VERSION ""

NS_ :

BS_:

BU_: FUSION BMS CCU EBM EOP_F EOP_R MCU_B_F MCU_B_R Shifter MCU_N_F MCU_N_R DataCenter

BO_ 496 FD3_VCU0: 64 FUSION
 SG_ SysPwrSta : 7|4@0+ (1,0) [0|15] "" Vector__XXX
 SG_ PowerUpFault : 11|4@0+ (1,0) [0|7] "" Vector__XXX
 SG_ PowerUpState : 15|4@0+ (1,0) [0|7] "" Vector__XXX
 SG_ PowerDownFault : 19|4@0+ (1,0) [0|7] "" Vector__XXX
 SG_ PowerDownState : 22|3@0+ (1,0) [0|7] "" Vector__XXX
 SG_ TCountSta : 26|2@0+ (1,0) [0|2] "" Vector__XXX
 SG_ PwrStaConstraint : 29|3@0+ (1,0) [0|4] "" Vector__XXX
 SG_ PwrStaSelect : 31|2@0+ (1,0) [0|3] "" Vector__XXX
 SG_ Rr_TqSource : 35|4@0+ (1,0) [0|9] "" Vector__XXX
 SG_ PwrDownReq : 37|2@0+ (1,0) [0|2] "" Vector__XXX
 SG_ PwrUpReq : 39|2@0+ (1,0) [0|2] "" Vector__XXX
 SG_ HVTHCMSysAvail : 41|2@0+ (1,0) [0|3] "" Vector__XXX
 SG_ LVBattVoltSta : 43|2@0+ (1,0) [0|3] "" DataCenter
 SG_ Fr_TqSource : 47|4@0+ (1,0) [0|9] "" Vector__XXX
 SG_ VehHVPwrAvail4THCM : 55|8@0+ (50,0) [0|12650] "W" Vector__XXX
 SG_ HVRlyOpFail : 56|1@0+ (1,0) [0|1] "" Vector__XXX
 SG_ SysAllowReadySta : 57|1@0+ (1,0) [0|1] "" Vector__XXX
 SG_ VCURRDoorSta : 58|1@0+ (1,0) [0|1] "" Vector__XXX
 SG_ VCURLDoorSta : 59|1@0+ (1,0) [0|1] "" Vector__XXX
 SG_ VCUFRDoorSta : 60|1@0+ (1,0) [0|1] "" Vector__XXX
 SG_ VCUFLDoorSta : 61|1@0+ (1,0) [0|1] "" Vector__XXX
 SG_ VCUBrkSWSta : 63|2@0+ (1,0) [0|2] "" Vector__XXX
 SG_ PwrStaONTOIVIPopT : 67|12@0+ (1,0) [0|4095] "SECOND" Vector__XXX
 SG_ PwrStaTOSta : 69|1@0+ (1,0) [0|1] "" Vector__XXX
 SG_ PwrStaONTOIVIPopReq : 70|1@0+ (1,0) [0|1] "" Vector__XXX
 SG_ MCUActDisFail : 71|1@0+ (1,0) [0|1] "" Vector__XXX
 SG_ TimerAllowSleep : 80|1@0+ (1,0) [0|1] "" Vector__XXX
 SG_ LVSilentChrgReq : 81|1@0+ (1,0) [0|1] "" Vector__XXX
 SG_ LVSilentChrgLv : 83|2@0+ (1,0) [0|3] "" Vector__XXX
 SG_ LVSilentChrgSta : 85|2@0+ (1,0) [0|3] "" Vector__XXX
 SG_ SilentChkAllowSleep : 86|1@0+ (1,0) [0|1] "" Vector__XXX
 SG_ SchedChgTOSta : 87|1@0+ (1,0) [0|1] "" Vector__XXX
 SG_ LVChrgHoldTAct : 91|12@0+ (1,0) [0|4095] "SECOND" Vector__XXX
 SG_ EVCCAplusPwrUpReq : 94|1@0+ (1,0) [0|1] "" Vector__XXX
 SG_ PMMAllowECUSleep : 95|1@0+ (1,0) [0|1] "" Vector__XXX
 SG_ LVBattChrgtimeAct : 107|12@0+ (1,0) [0|4095] "SECOND" Vector__XXX
 SG_ FDADC12VDetAvg : 127|8@0+ (0.1,0) [0|25.5] "V" DataCenter
 SG_ WisrBootReason : 231|32@0+ (1,0) [0|4.294967295E9] "" Vector__XXX
 SG_ PmicBootReason : 223|8@0+ (1,0) [0|255] "" Vector__XXX
 SG_ FDC_VMC_ActStESCYaw_Sta : 263|16@0+ (0.01,-300) [-300|300] "Deg/s" Vector__XXX
 SG_ FDC_VMC_LongAcc_Sta : 279|16@0+ (0.001,-20) [-20|20] "G's" Vector__XXX
 SG_ FDC_VCU_VehActSpd_Sta : 295|16@0+ (0.01,-300) [-300|300] "km/h" Vector__XXX
 SG_ FDC_VCU_ActMaxSlideRate_Sta : 311|16@0+ (0.01,-150) [-150|150] "%" Vector__XXX
 SG_ FDC_VCU_SlideRegenLimTq_Sta : 327|16@0+ (0.5,-5300) [-5300|5300] "Nm" Vector__XXX
 SG_ FDC_VCU_DTCCarousel_Sta : 343|8@0+ (1,0) [0|255] "" Vector__XXX
 SG_ FDC_VCU_VehMalfunLevel_Sta : 3|4@0+ (1,0) [0|15] "" Vector__XXX
 SG_ FDC_VCU_RWDRDCActive_Sta : 93|2@0+ (1,0) [0|3] "" Vector__XXX
 SG_ FDC_VCU_AllowMovThd_OTA_Sta : 111|2@0+ (1,0) [0|3] "" Vector__XXX
 SG_ FDC_VCU_RegenTqLimitEn_Sta : 23|1@0+ (1,0) [0|1] "" Vector__XXX
 SG_ FDC_VCU_ForceP_Cmd : 24|1@0+ (1,0) [0|1] "" Vector__XXX
 SG_ FDC_VCU_PwrReq_OTA_Sta : 109|2@0+ (1,0) [0|3] "" Vector__XXX
 SG_ FDC_VCU_OTAPwrReqOFFChk_Sta : 351|2@0+ (1,0) [0|3] "" Vector__XXX
 SG_ FDC_VCU_OTAPwrReqStdChk_Sta : 349|2@0+ (1,0) [0|3] "" Vector__XXX
 SG_ FDADC12VDet : 215|8@0+ (0.1,0) [0|25.5] "V" Vector__XXX
 SG_ FDC_VCU_EAPS2Raw_Sta : 367|8@0+ (0.4,0) [0|102] "%" Vector__XXX
 SG_ FDC_VCU_EAPS1Raw_Sta : 359|8@0+ (0.4,0) [0|102] "%" Vector__XXX
 SG_ FDC_VCU_EAPS2Min_Sta : 383|8@0+ (0.4,0) [0|102] "%" Vector__XXX
 SG_ FDC_VCU_EAPS1Min_Sta : 375|8@0+ (0.4,0) [0|102] "%" Vector__XXX
 SG_ FDC_VCU_BrakeSigMatrix_Sta : 391|6@0+ (1,0) [0|63] "" Vector__XXX
 SG_ FDC_VCU_CANBrkSW2Sta_Sta : 347|2@0+ (1,0) [0|3] "" Vector__XXX
 SG_ FDC_VCU_BrkPedalPosSta_Sta : 345|2@0+ (1,0) [0|3] "" Vector__XXX
 SG_ FDC_VCU_LowIdleAccPedal_Sta : 68|1@0+ (1,0) [0|1] "" Vector__XXX
 SG_ FDC_SYS_PmicBootPath : 487|32@0+ (1,0) [0|4.294967295E9] "" Vector__XXX
 SG_ FDC_VCU_LVStaDropQukCnt_Sta : 471|8@0+ (1,0) [0|255] "" DataCenter
 SG_ FDC_VCU_LVChrgFreqCnt_Sta : 479|8@0+ (1,0) [0|255] "" DataCenter
 SG_ FDC_VCU_FrRateLimitInc_Sta : 135|16@0+ (2,0) [0|131070] "Nm" Vector__XXX
 SG_ FDC_VCU_RrRateLimitInc_Sta : 167|16@0+ (2,0) [0|131070] "Nm" Vector__XXX
 SG_ FDC_VCU_FrRateLimitDec_Sta : 151|16@0+ (2,-131070) [-131070|0] "Nm" Vector__XXX
 SG_ FDC_VCU_RrRateLimitDec_Sta : 183|16@0+ (2,-131070) [-131070|0] "Nm" Vector__XXX
 SG_ FDC_VCU_FrFirstOrderInpTs : 199|8@0+ (0.01,0) [0|2.55] "" Vector__XXX
 SG_ FDC_VCU_RrFirstOrderInpTs : 207|8@0+ (0.01,0) [0|2.55] "" Vector__XXX
 SG_ FDC_VCU_BOSEnable_Sta : 385|1@0+ (1,0) [0|1] "" Vector__XXX

BO_ 534 FD3_BCM1: 16 FUSION
 SG_ BCM_Buzzer_Req : 64|1@0+ (1,0) [0|1] "" Vector__XXX
 SG_ TailgateRemote : 66|2@0+ (1,0) [0|3] "" Vector__XXX
 SG_ RoomLampL : 67|1@0+ (1,0) [0|1] "" Vector__XXX
 SG_ RoomLampH : 68|1@0+ (1,0) [0|1] "" Vector__XXX
 SG_ DimmerEN : 69|1@0+ (1,0) [0|1] "" Shifter
 SG_ BCM_DoorLock_Sta : 70|1@0+ (1,0) [0|1] "" Vector__XXX
 SG_ HornCtrl : 71|1@0+ (1,0) [0|1] "" Vector__XXX
 SG_ Dimmer : 78|7@0+ (1,0) [0|100] "%" Shifter
 SG_ LockSetting : 79|1@0+ (1,0) [0|1] "" Vector__XXX
 SG_ LTurnLP : 80|1@0+ (1,0) [0|1] "" Vector__XXX
 SG_ RTurnLP : 81|1@0+ (1,0) [0|1] "" Vector__XXX
 SG_ AntitheftSta : 83|2@0+ (1,0) [0|3] "" Vector__XXX
 SG_ AntiTheftSeatFold : 84|1@0+ (1,0) [0|1] "" Vector__XXX
 SG_ CrashDetd : 85|1@0+ (1,0) [0|1] "" Vector__XXX
 SG_ L_APM_WdwEnable : 87|1@0+ (1,0) [0|1] "" Vector__XXX
 SG_ RDRL : 88|1@0+ (1,0) [0|1] "" Vector__XXX
 SG_ ReverseLamp : 89|1@0+ (1,0) [0|1] "" Vector__XXX
 SG_ BrakeLamp : 90|1@0+ (1,0) [0|1] "" Vector__XXX
 SG_ LBSD : 91|1@0+ (1,0) [0|1] "" Vector__XXX
 SG_ RBSD : 92|1@0+ (1,0) [0|1] "" Vector__XXX
 SG_ Fr_FogLamp : 93|1@0+ (1,0) [0|1] "" Vector__XXX
 SG_ Rr_FogLamp : 94|1@0+ (1,0) [0|1] "" Vector__XXX
 SG_ HazardSW : 95|1@0+ (1,0) [0|1] "" Vector__XXX
 SG_ Rr_Wiper : 96|1@0+ (1,0) [0|1] "" Vector__XXX
 SG_ WiperFixMode : 97|1@0+ (1,0) [0|1] "" Vector__XXX
 SG_ WasherCtrl : 99|2@0+ (1,0) [0|3] "" Vector__XXX
 SG_ L_Beam : 100|1@0+ (1,0) [0|1] "" Vector__XXX
 SG_ H_Beam : 101|1@0+ (1,0) [0|1] "" Vector__XXX
 SG_ PosLamp : 102|1@0+ (1,0) [0|1] "" Vector__XXX
 SG_ LDRL : 103|1@0+ (1,0) [0|1] "" Vector__XXX
 SG_ MirrorDefog : 104|1@0+ (1,0) [0|1] "" Vector__XXX
 SG_ Rr_Defog : 105|1@0+ (1,0) [0|1] "" Vector__XXX
 SG_ TrunkRel : 106|1@0+ (1,0) [0|1] "" Vector__XXX
 SG_ TailgateHDSW : 107|1@0+ (1,0) [0|1] "" Vector__XXX
 SG_ MirrorCtrl : 109|2@0+ (1,0) [0|3] "" Vector__XXX
 SG_ Fr_Wiper_H : 110|1@0+ (1,0) [0|1] "" Vector__XXX
 SG_ Fr_Wiper_L : 111|1@0+ (1,0) [0|1] "" Vector__XXX
 SG_ CTDCtrl : 113|2@0+ (1,0) [0|3] "" BMS
 SG_ Fr_ChargingDoorCtrl : 115|2@0+ (1,0) [0|3] "" Vector__XXX
 SG_ Rr_ChargingDoorCtrl : 117|2@0+ (1,0) [0|3] "" Vector__XXX
 SG_ CTDLockSW : 118|1@0+ (1,0) [0|1] "" Vector__XXX
 SG_ CTDUnlockSW : 119|1@0+ (1,0) [0|1] "" Vector__XXX
 SG_ DrDoorSW : 120|1@0+ (1,0) [0|1] "" EBM
 SG_ PsDoorSW : 121|1@0+ (1,0) [0|1] "" Vector__XXX
 SG_ RLDoorSW : 122|1@0+ (1,0) [0|1] "" Vector__XXX
 SG_ RRDoorSW : 123|1@0+ (1,0) [0|1] "" Vector__XXX
 SG_ AllDoorSW : 124|1@0+ (1,0) [0|1] "" Vector__XXX
 SG_ DoorLockIND : 125|1@0+ (1,0) [0|1] "" Vector__XXX
 SG_ HoodSW : 126|1@0+ (1,0) [0|1] "" Vector__XXX
 SG_ Tailgate_SW : 127|1@0+ (1,0) [0|1] "" Vector__XXX

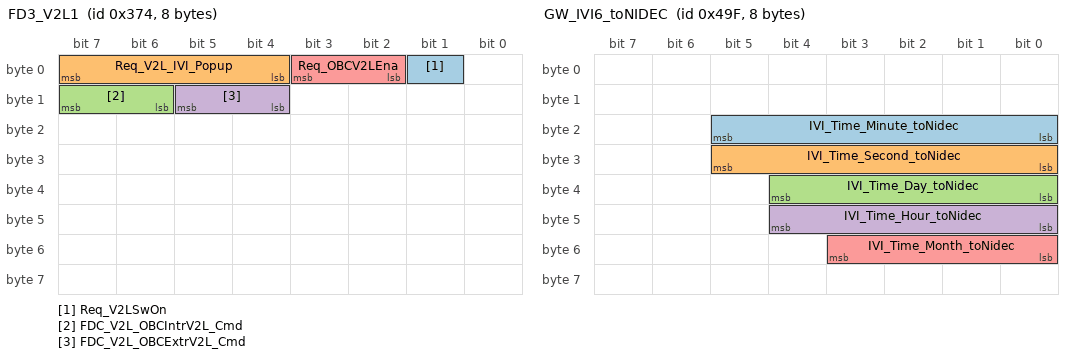
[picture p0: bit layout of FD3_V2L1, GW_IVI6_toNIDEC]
BO_ 884 FD3_V2L1: 8 FUSION
 SG_ Req_V2LSwOn : 1|1@0+ (1,0) [0|1] "" Vector__XXX
 SG_ Req_V2L_IVI_Popup : 7|4@0+ (1,0) [0|7] "" Vector__XXX
 SG_ FDC_V2L_OBCIntrV2L_Cmd : 15|2@0+ (1,0) [0|3] "" CCU
 SG_ FDC_V2L_OBCExtrV2L_Cmd : 13|2@0+ (1,0) [0|3] "" CCU
 SG_ Req_OBCV2LEna : 3|2@0+ (1,0) [0|2] "" CCU

BO_ 1080 FD3_OTA1: 12 FUSION
 SG_ OTA_Progress_Rate : 7|8@0+ (1,0) [0|102] "%" Vector__XXX
 SG_ OTA_DL_Available : 8|1@0+ (1,0) [0|1] "" Vector__XXX
 SG_ OTA_Mode : 9|1@0+ (1,0) [0|1] "" BMS,Shifter
 SG_ OTA_Network_Type : 11|2@0+ (1,0) [0|3] "" Vector__XXX
 SG_ OTA_MDA_Status : 52|5@0+ (1,0) [0|14] "" Vector__XXX
 SG_ OTA_Updating_ECU_8bit : 23|8@0+ (1,0) [0|255] "" Vector__XXX
 SG_ OTA_DL_Speed : 27|20@0+ (1,0) [0|1048575] "Kb/s" Vector__XXX
 SG_ OTA_InVehicle_FW : 29|2@0+ (1,0) [0|2] "" Vector__XXX
 SG_ OTA_TBOXResetReq : 30|1@0+ (1,0) [0|1] "" Vector__XXX
 SG_ OTA_Lock_Req : 31|1@0+ (1,0) [0|1] "" Vector__XXX
 SG_ OTA_Remained_Time : 58|11@0+ (10,0) [0|1081] "SECOND" Vector__XXX
 SG_ OTA_Update_Available : 62|1@0+ (1,0) [0|1] "" Vector__XXX
 SG_ OTA_Permit_Agreed : 63|1@0+ (1,0) [0|1] "" Vector__XXX
 SG_ OTA_Debug_Code : 79|8@0+ (1,0) [0|65] "" Vector__XXX
 SG_ OTA_Emergency_Sta : 61|2@0+ (1,0) [0|3] "" Vector__XXX

BO_ 1183 GW_IVI6_toNIDEC: 8 FUSION
 SG_ IVI_Time_Minute_toNidec : 21|6@0+ (1,0) [0|63] "MINUTE" EOP_F,EOP_R,MCU_N_F,MCU_N_R
 SG_ IVI_Time_Second_toNidec : 29|6@0+ (1,0) [0|63] "SECOND" EOP_F,EOP_R,MCU_N_F,MCU_N_R
 SG_ IVI_Time_Day_toNidec : 36|5@0+ (1,0) [0|31] "DAY" EOP_F,EOP_R,MCU_N_F,MCU_N_R
 SG_ IVI_Time_Hour_toNidec : 44|5@0+ (1,0) [0|31] "HOUR" EOP_F,EOP_R,MCU_N_F,MCU_N_R
 SG_ IVI_Time_Month_toNidec : 51|4@0+ (1,0) [0|12] "MONTH" EOP_F,EOP_R,MCU_N_F,MCU_N_R

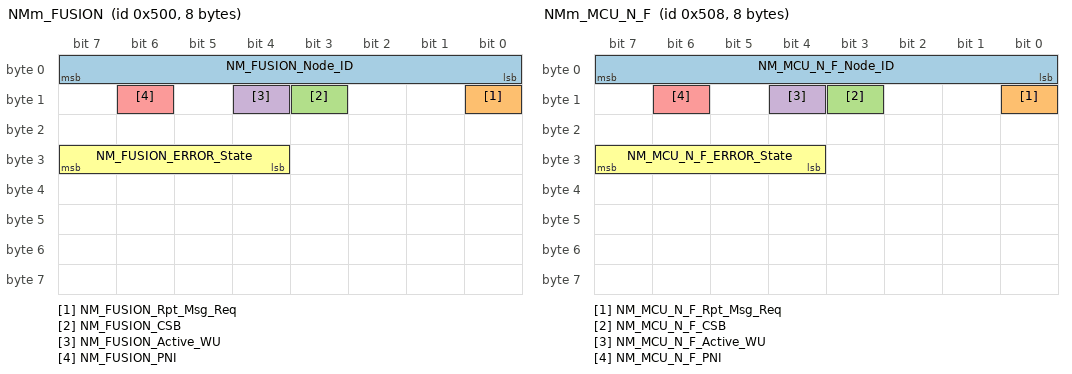
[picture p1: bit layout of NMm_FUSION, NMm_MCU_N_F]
BO_ 1280 NMm_FUSION: 8 FUSION
 SG_ NM_FUSION_Node_ID : 7|8@0+ (1,0) [0|127] "" BMS,CCU,EBM,EOP_F,EOP_R,MCU_N_F,MCU_N_R,Shifter,MCU_B_F,MCU_B_R
 SG_ NM_FUSION_Rpt_Msg_Req : 8|1@0+ (1,0) [0|1] "" BMS,CCU,EBM,EOP_F,EOP_R,MCU_N_F,MCU_N_R,Shifter,MCU_B_F,MCU_B_R
 SG_ NM_FUSION_CSB : 11|1@0+ (1,0) [0|1] "" BMS,CCU,EBM,EOP_F,EOP_R,MCU_N_F,MCU_N_R,Shifter,MCU_B_F,MCU_B_R
 SG_ NM_FUSION_Active_WU : 12|1@0+ (1,0) [0|1] "" BMS,CCU,EBM,EOP_F,EOP_R,MCU_N_F,MCU_N_R,Shifter,MCU_B_F,MCU_B_R
 SG_ NM_FUSION_PNI : 14|1@0+ (1,0) [0|1] "" BMS,CCU,EBM,EOP_F,EOP_R,MCU_N_F,MCU_N_R,Shifter,MCU_B_F,MCU_B_R
 SG_ NM_FUSION_ERROR_State : 31|4@0+ (1,0) [0|8] "" BMS,CCU,EBM,EOP_F,EOP_R,MCU_N_F,MCU_N_R,Shifter,MCU_B_F,MCU_B_R

BO_ 1667 DiagPhysReqToMCU_N_R: 8 FUSION
 SG_ DiagPhysReqToMCU_N_R : 7|64@0+ (1,0) [0|0] "" MCU_N_R

BO_ 1672 DiagPhysReqToMCU_N_F: 8 FUSION
 SG_ DiagPhysReqToMCU_N_F : 7|64@0+ (1,0) [0|0] "" MCU_N_F

BO_ 1683 DiagPhysReqToEOP_R: 64 FUSION
 SG_ DiagPhysReqToEOP_R : 7|64@0+ (1,0) [0|0] "" EOP_R

BO_ 1688 DiagPhysReqToEOP_F: 64 FUSION
 SG_ DiagPhysReqToEOP_F : 7|64@0+ (1,0) [0|0] "" EOP_F

BO_ 1699 DiagPhysReqToEBM: 64 FUSION
 SG_ DiagPhysReqToEBM : 7|64@0+ (1,0) [0|0] "" EBM

BO_ 1712 DiagPhysReqToBMS: 8 FUSION
 SG_ DiagPhysReqToBMS : 7|64@0+ (1,0) [0|0] "" BMS

BO_ 1715 DiagPhysReqToCCU: 8 FUSION
 SG_ DiagPhysReqToCCU : 7|64@0+ (1,0) [0|0] "" CCU

BO_ 1720 DiagPhysReqToShifter: 8 FUSION
 SG_ DiagPhysReqToShifter : 7|64@0+ (1,0) [0|0] "" Shifter

BO_ 2000 DiagFuncReqFT: 8 FUSION
 SG_ DiagFuncReqFT : 7|64@0+ (1,0) [0|0] "" BMS,CCU,EBM,EOP_F,EOP_R,MCU_N_F,MCU_N_R,Shifter,MCU_B_F,MCU_B_R

BO_ 401 MCU_B_F1: 32 MCU_B_F
 SG_ Fr_MCU1Chksum : 7|8@0+ (1,0) [0|255] "" FUSION
 SG_ Fr_MCU1RolCnt : 11|4@0+ (1,0) [0|14] "" FUSION
 SG_ Fr_MCUSysSta : 59|4@0+ (1,0) [0|15] "" FUSION
 SG_ MCUWarn_F : 62|3@0+ (1,0) [0|7] "" FUSION
 SG_ Fr_MCUReady : 63|1@0+ (1,0) [0|1] "" FUSION
 SG_ Fr_MCUBAT : 71|8@0+ (0.1,0) [0|25.4] "V" FUSION
 SG_ Fr_MCUIGN_sta : 72|1@0+ (1,0) [0|1] "" FUSION
 SG_ Fr_Reserved_bits : 79|7@0+ (1,0) [0|127] "" FUSION
 SG_ Fr_RegenAvailTq : 87|12@0+ (1,-1022) [-1022|0] "Nm" FUSION
 SG_ Fr_MotorAvailTq : 91|12@0+ (1,0) [0|1022] "Nm" FUSION
 SG_ Fr_TMiq : 110|15@0+ (0.1,-1500) [-1500|1500] "A" FUSION
 SG_ Fr_TMid : 126|15@0+ (0.1,-1500) [-1500|1500] "A" FUSION
 SG_ Fr_MCUErr : 143|8@0+ (1,0) [0|255] "" FUSION
 SG_ Fr_TMTemp : 144|9@0+ (1,-40) [-40|254] "Deg^C" FUSION
 SG_ Fr_MCUTemp : 167|9@0+ (1,-40) [-40|254] "Deg^C" FUSION
 SG_ Fr_MCUDCBusCurr : 174|15@0+ (0.1,-1500) [-1500|1500] "A" FUSION
 SG_ Fr_MCUDCBusVolt : 191|16@0+ (0.1,0) [0|4000] "V" FUSION
 SG_ Fr_MCUReady4Pre : 200|1@0+ (1,0) [0|1] "" FUSION
 SG_ Fr_ActvDmpDisabSta : 201|1@0+ (1,0) [0|1] "" FUSION
 SG_ Fr_EDUDrtSta : 202|1@0+ (1,0) [0|1] "" FUSION
 SG_ Fr_MCUDischrgSta : 203|1@0+ (1,0) [0|1] "" FUSION
 SG_ Fr_TMSpd : 215|16@0+ (1,-18000) [-18000|18000] "RPM" FUSION
 SG_ Fr_EDURealTMTq : 231|16@0+ (0.1,-1022) [-1022|5531.5] "Nm" FUSION
 SG_ Fr_EDUTqReqFbk : 243|12@0+ (1,-1022) [-1022|1022] "Nm" FUSION
 SG_ Fr_MCUEnaSta : 244|1@0+ (1,0) [0|1] "" FUSION
 SG_ Fr_EDUOpratingSta : 245|1@0+ (1,0) [0|1] "" FUSION
 SG_ Fr_EDURotateDirction : 247|2@0+ (1,0) [0|2] "" FUSION
 SG_ MCU_B_F_IGBTDdeTemp_Sta : 24|9@0+ (1,-40) [-40|254] "Deg^C" FUSION
 SG_ MCU_B_F_RealPwrKw_Sta : 47|16@0+ (0.1,-530) [-530|6023.4] "KW" FUSION

BO_ 404 MCU_B_F2: 16 MCU_B_F
 SG_ Fr_MCU2Chksum : 7|8@0+ (1,0) [0|255] "" FUSION
 SG_ Fr_MCU2RolCnt : 11|4@0+ (1,0) [0|14] "" FUSION
 SG_ Fr_LLCflowReq : 21|6@0+ (0.25,0) [0|15.5] "L/min" FUSION
 SG_ Fr_CoolanttempReq : 24|9@0+ (1,-40) [-40|214] "Deg^C" FUSION
 SG_ Fr_Failcodehistory1 : 41|2@0+ (1,0) [0|2] "" FUSION
 SG_ Fr_Failcodehistory2 : 43|2@0+ (1,0) [0|2] "" FUSION
 SG_ Fr_TMTempWarn : 45|2@0+ (1,0) [0|3] "" FUSION
 SG_ Fr_MCUTempWarn : 47|2@0+ (1,0) [0|3] "" FUSION
 SG_ Fr_Failcode2 : 55|8@0+ (1,0) [0|255] "" FUSION
 SG_ Fr_Failcode1 : 63|8@0+ (1,0) [0|255] "" FUSION
 SG_ Fr_LLCTemp : 80|9@0+ (1,-40) [-40|214] "Deg^C" FUSION
 SG_ Fr_MCU_HW_Ver : 103|16@0+ (1,0) [0|65535] "" FUSION
 SG_ Fr_MCU_SW_Ver : 119|16@0+ (1,0) [0|65535] "" FUSION
 SG_ MCU_B_F_LLCTempWarn_Sta : 23|2@0+ (1,0) [0|3] "" FUSION
 SG_ MCU_B_F_FailLv_Sta : 27|3@0+ (1,0) [0|7] "" FUSION
 SG_ MCU_B_F_KL302TqCnt_Sta : 71|8@0+ (1,0) [0|254] "" FUSION

BO_ 406 MCU_N_F1: 32 MCU_N_F
 SG_ Fr_MCU1Chksum_Nidec : 7|8@0+ (1,0) [0|255] "" FUSION
 SG_ MCUWarn_F_Nidec : 10|3@0+ (1,0) [0|7] "" FUSION
 SG_ Fr_MCUReady_Nidec : 11|1@0+ (1,0) [0|1] "" FUSION
 SG_ Fr_MCU1RolCnt_Nidec : 15|4@0+ (1,0) [0|15] "" FUSION
 SG_ Fr_MCUSysSta_Nidec : 59|4@0+ (1,0) [0|15] "" FUSION
 SG_ Fr_MCUBAT_Nidec : 71|8@0+ (0.1,0) [0|25.4] "V" FUSION
 SG_ Fr_MCUIGN_sta_Nidec : 72|1@0+ (1,0) [0|1] "" FUSION
 SG_ Fr_Reserved_bits_Nidec : 79|7@0+ (1,0) [0|127] "" FUSION
 SG_ Fr_RegenAvailTq_Nidec : 87|12@0+ (1,-1022) [-1022|0] "Nm" FUSION
 SG_ Fr_MotorAvailTq_Nidec : 91|12@0+ (1,0) [0|1022] "Nm" FUSION
 SG_ Fr_TMiq_Nidec : 110|15@0+ (0.1,-1500) [-1500|1500] "A" FUSION
 SG_ Fr_TMid_Nidec : 126|15@0+ (0.1,-1500) [-1500|1500] "A" FUSION
 SG_ Fr_MCUErr_Nidec : 143|8@0+ (1,0) [0|255] "" FUSION
 SG_ Fr_TMTemp_Nidec : 144|9@0+ (1,-40) [-40|254] "Deg^C" FUSION
 SG_ Fr_MCUTemp_Nidec : 167|9@0+ (1,-40) [-40|254] "Deg^C" FUSION
 SG_ Fr_MCUDCBusCurr_Nidec : 174|15@0+ (0.1,-1500) [-1500|1500] "A" FUSION
 SG_ Fr_MCUDCBusVolt_Nidec : 191|16@0+ (0.1,0) [0|4000] "V" FUSION
 SG_ Fr_MCUReady4Pre_Nidec : 200|1@0+ (1,0) [0|1] "" FUSION
 SG_ Fr_ActvDmpDisabSta_Nidec : 201|1@0+ (1,0) [0|1] "" FUSION
 SG_ Fr_EDUDrtSta_Nidec : 202|1@0+ (1,0) [0|1] "" FUSION
 SG_ Fr_MCUDischrgSta_Nidec : 203|1@0+ (1,0) [0|1] "" FUSION
 SG_ Fr_TMSpd_Nidec : 215|16@0+ (1,-17000) [-17000|17000] "RPM" FUSION
 SG_ Fr_EDURealTMTq_Nidec : 227|12@0+ (1,-1022) [-1022|1022] "Nm" FUSION
 SG_ Fr_EDUTqReqFbk_Nidec : 243|12@0+ (1,-1022) [-1022|1022] "Nm" FUSION
 SG_ Fr_MCUEnaSta_Nidec : 244|1@0+ (1,0) [0|1] "" FUSION
 SG_ Fr_EDUOpratingSta_Nidec : 245|1@0+ (1,0) [0|1] "" FUSION
 SG_ Fr_EDURotateDirction_Nidec : 247|2@0+ (1,0) [0|2] "" FUSION

BO_ 408 MCU_N_F2: 12 MCU_N_F
 SG_ Fr_MCU2Chksum_Nidec : 7|8@0+ (1,0) [0|255] "" FUSION
 SG_ Fr_MCU2RolCnt_Nidec : 15|4@0+ (1,0) [0|15] "" FUSION
 SG_ Fr_CoolanttempReq_Nidec : 24|9@0+ (1,-40) [-40|214] "Deg^C" FUSION
 SG_ Fr_Failcodehistory1_Nidec : 41|2@0+ (1,0) [0|2] "" FUSION
 SG_ Fr_Failcodehistory2_Nidec : 43|2@0+ (1,0) [0|2] "" FUSION
 SG_ Fr_TMTempWarn_Nidec : 45|2@0+ (1,0) [0|3] "" FUSION
 SG_ Fr_MCUTempWarn_Nidec : 47|2@0+ (1,0) [0|3] "" FUSION
 SG_ Fr_Failcode2_Nidec : 55|8@0+ (1,0) [0|255] "" FUSION
 SG_ Fr_Failcode1_Nidec : 63|8@0+ (1,0) [0|255] "" FUSION
 SG_ Fr_EOP_SpdSet_Nidec : 67|12@0+ (1,0) [0|4000] "RPM" FUSION
 SG_ Fr_LLCTemp_Nidec : 80|9@0+ (1,-40) [-40|214] "Deg^C" FUSION
 SG_ Fr_LLCflowReq_Nidec : 87|6@0+ (0.25,0) [0|15.5] "L/min" FUSION
 SG_ MCU_F_ResetCnt_Sta : 23|8@0+ (1,0) [0|255] "" FUSION

BO_ 921 MCU_N_F3: 8 MCU_N_F
 SG_ Fr_MCU_HW_Ver_Nidec : 39|16@0+ (1,0) [0|65535] "" FUSION
 SG_ Fr_MCU_SW_Ver_Nidec : 55|16@0+ (1,0) [0|65535] "" FUSION

BO_ 1288 NMm_MCU_N_F: 8 MCU_N_F
 SG_ NM_MCU_N_F_Node_ID : 7|8@0+ (1,0) [0|127] "" FUSION
 SG_ NM_MCU_N_F_Rpt_Msg_Req : 8|1@0+ (1,0) [0|1] "" FUSION
 SG_ NM_MCU_N_F_CSB : 11|1@0+ (1,0) [0|1] "" FUSION
 SG_ NM_MCU_N_F_Active_WU : 12|1@0+ (1,0) [0|1] "" FUSION
 SG_ NM_MCU_N_F_PNI : 14|1@0+ (1,0) [0|1] "" FUSION
 SG_ NM_MCU_N_F_ERROR_State : 31|4@0+ (1,0) [0|8] "" FUSION

BO_ 1544 DiagRespFromMCU_N_F: 8 MCU_N_F
 SG_ DiagRespFromMCU_N_F : 7|64@0+ (1,0) [0|0] "" FUSION

BO_ 400 MCU_B_R1: 32 MCU_B_R
 SG_ Rr_MCU1Chksum : 7|8@0+ (1,0) [0|255] "" FUSION
 SG_ Rr_MCU1RolCnt : 11|4@0+ (1,0) [0|14] "" FUSION
 SG_ Rr_MCUSysSta : 59|4@0+ (1,0) [0|15] "" FUSION
 SG_ MCUWarn_R : 62|3@0+ (1,0) [0|7] "" FUSION
 SG_ Rr_MCUReady : 63|1@0+ (1,0) [0|1] "" FUSION
 SG_ Rr_MCUBAT : 71|8@0+ (0.1,0) [0|25.4] "V" FUSION
 SG_ Rr_MCUIGN_sta : 72|1@0+ (1,0) [0|1] "" FUSION
 SG_ Rr_Reserved_bits : 79|7@0+ (1,0) [0|127] "" FUSION
 SG_ Rr_RegenAvailTq : 87|12@0+ (1,-1022) [-1022|0] "Nm" FUSION
 SG_ Rr_MotorAvailTq : 91|12@0+ (1,0) [0|1022] "Nm" FUSION
 SG_ Rr_TMiq : 110|15@0+ (0.1,-1500) [-1500|1500] "A" FUSION
 SG_ Rr_TMid : 126|15@0+ (0.1,-1500) [-1500|1500] "A" FUSION
 SG_ Rr_MCUErr : 143|8@0+ (1,0) [0|255] "" FUSION
 SG_ Rr_TMTemp : 144|9@0+ (1,-40) [-40|254] "Deg^C" FUSION
 SG_ Rr_MCUTemp : 167|9@0+ (1,-40) [-40|254] "Deg^C" FUSION
 SG_ Rr_MCUDCBusCurr : 174|15@0+ (0.1,-1500) [-1500|1500] "A" FUSION
 SG_ Rr_MCUDCBusVolt : 191|16@0+ (0.1,0) [0|4000] "V" FUSION
 SG_ Rr_MCUReady4Pre : 200|1@0+ (1,0) [0|1] "" FUSION
 SG_ Rr_ActvDmpDisabSta : 201|1@0+ (1,0) [0|1] "" FUSION
 SG_ Rr_EDUDrtSta : 202|1@0+ (1,0) [0|1] "" FUSION
 SG_ Rr_MCUDischrgSta : 203|1@0+ (1,0) [0|1] "" FUSION
 SG_ Rr_TMSpd : 215|16@0+ (1,-18000) [-18000|18000] "RPM" FUSION
 SG_ Rr_EDURealTMTq : 231|16@0+ (0.1,-1022) [-1022|5531.5] "Nm" FUSION
 SG_ Rr_EDUTqReqFbk : 243|12@0+ (1,-1022) [-1022|1022] "Nm" FUSION
 SG_ Rr_MCUEnaSta : 244|1@0+ (1,0) [0|1] "" FUSION
 SG_ Rr_EDUOpratingSta : 245|1@0+ (1,0) [0|1] "" FUSION
 SG_ Rr_EDURotateDirction : 247|2@0+ (1,0) [0|2] "" FUSION
 SG_ MCU_B_R_RealPwrKw_Sta : 47|16@0+ (0.1,-530) [-530|6023.4] "KW" FUSION
 SG_ MCU_B_R_IGBTDdeTemp_Sta : 24|9@0+ (1,-40) [-40|254] "Deg^C" FUSION

BO_ 402 MCU_N_R1: 32 MCU_N_R
 SG_ Rr_MCU1Chksum_Nidec : 7|8@0+ (1,0) [0|255] "" FUSION
 SG_ MCUWarn_R_Nidec : 10|3@0+ (1,0) [0|7] "" FUSION
 SG_ Rr_MCU1RolCnt_Nidec : 15|4@0+ (1,0) [0|15] "" FUSION
 SG_ Rr_MCUSysSta_Nidec : 59|4@0+ (1,0) [0|15] "" FUSION
 SG_ Rr_MCUBAT_Nidec : 71|8@0+ (0.1,0) [0|25.4] "V" FUSION
 SG_ Rr_MCUIGN_sta_Nidec : 72|1@0+ (1,0) [0|1] "" FUSION
 SG_ Rr_Reserved_bits_Nidec : 79|7@0+ (1,0) [0|127] "" FUSION
 SG_ Rr_RegenAvailTq_Nidec : 87|12@0+ (1,-1022) [-1022|0] "Nm" FUSION
 SG_ Rr_MotorAvailTq_Nidec : 91|12@0+ (1,0) [0|1022] "Nm" FUSION
 SG_ Rr_TMiq_Nidec : 110|15@0+ (0.1,-1500) [-1500|1500] "A" FUSION
 SG_ Rr_TMid_Nidec : 126|15@0+ (0.1,-1500) [-1500|1500] "A" FUSION
 SG_ Rr_MCUErr_Nidec : 143|8@0+ (1,0) [0|255] "" FUSION
 SG_ Rr_TMTemp_Nidec : 144|9@0+ (1,-40) [-40|254] "Deg^C" FUSION
 SG_ Rr_MCUTemp_Nidec : 167|9@0+ (1,-40) [-40|254] "Deg^C" FUSION
 SG_ Rr_MCUDCBusCurr_Nidec : 174|15@0+ (0.1,-1500) [-1500|1500] "A" FUSION
 SG_ Rr_MCUDCBusVolt_Nidec : 191|16@0+ (0.1,0) [0|4000] "V" FUSION
 SG_ Rr_MCUReady4Pre_Nidec : 200|1@0+ (1,0) [0|1] "" FUSION
 SG_ Rr_ActvDmpDisabSta_Nidec : 201|1@0+ (1,0) [0|1] "" FUSION
 SG_ Rr_EDUDrtSta_Nidec : 202|1@0+ (1,0) [0|1] "" FUSION
 SG_ Rr_MCUDischrgSta_Nidec : 203|1@0+ (1,0) [0|1] "" FUSION
 SG_ Rr_MCUReady_Nidec : 207|1@0+ (1,0) [0|1] "" FUSION
 SG_ Rr_TMSpd_Nidec : 215|16@0+ (1,-17000) [-17000|17000] "RPM" FUSION
 SG_ Rr_EDURealTMTq_Nidec : 227|12@0+ (1,-1022) [-1022|1022] "Nm" FUSION
 SG_ Rr_EDUTqReqFbk_Nidec : 243|12@0+ (1,-1022) [-1022|1022] "Nm" FUSION
 SG_ Rr_MCUEnaSta_Nidec : 244|1@0+ (1,0) [0|1] "" FUSION
 SG_ Rr_EDUOpratingSta_Nidec : 245|1@0+ (1,0) [0|1] "" FUSION
 SG_ Rr_EDURotateDirction_Nidec : 247|2@0+ (1,0) [0|2] "" FUSION

BO_ 403 MCU_B_R2: 16 MCU_B_R
 SG_ Rr_MCU2Chksum : 7|8@0+ (1,0) [0|255] "" FUSION
 SG_ Rr_MCU2RolCnt : 11|4@0+ (1,0) [0|14] "" FUSION
 SG_ Rr_LLCflowReq : 21|6@0+ (0.25,0) [0|15.5] "L/min" FUSION
 SG_ Rr_CoolanttempReq : 24|9@0+ (1,-40) [-40|214] "" FUSION
 SG_ Rr_Failcodehistory1 : 41|2@0+ (1,0) [0|2] "" FUSION
 SG_ Rr_Failcodehistory2 : 43|2@0+ (1,0) [0|2] "" FUSION
 SG_ Rr_TMTempWarn : 45|2@0+ (1,0) [0|3] "" FUSION
 SG_ Rr_MCUTempWarn : 47|2@0+ (1,0) [0|3] "" FUSION
 SG_ Rr_Failcode2 : 55|8@0+ (1,0) [0|255] "" FUSION
 SG_ Rr_Failcode1 : 63|8@0+ (1,0) [0|255] "" FUSION
 SG_ Rr_LLCTemp : 80|9@0+ (1,-40) [-40|214] "Deg^C" FUSION
 SG_ Rr_MCU3_HW_Ver : 103|16@0+ (1,0) [0|65535] "" FUSION
 SG_ Rr_MCU3_SW_Ver : 119|16@0+ (1,0) [0|65535] "" FUSION
 SG_ MCU_B_R_LLCTempWarn_Sta : 23|2@0+ (1,0) [0|3] "" FUSION
 SG_ MCU_B_R_FailLv_Sta : 27|3@0+ (1,0) [0|7] "" FUSION
 SG_ MCU_B_R_KL302TqCnt_Sta : 71|8@0+ (1,0) [0|254] "" FUSION

BO_ 412 MCU_N_R2: 12 MCU_N_R
 SG_ Rr_MCU2Chksum_Nidec : 7|8@0+ (1,0) [0|255] "" FUSION
 SG_ Rr_MCU2RolCnt_Nidec : 15|4@0+ (1,0) [0|15] "" FUSION
 SG_ Rr_CoolanttempReq_Nidec : 24|9@0+ (1,-40) [-40|214] "" FUSION
 SG_ Rr_Failcodehistory1_Nidec : 41|2@0+ (1,0) [0|2] "" FUSION
 SG_ Rr_Failcodehistory2_Nidec : 43|2@0+ (1,0) [0|2] "" FUSION
 SG_ Rr_TMTempWarn_Nidec : 45|2@0+ (1,0) [0|3] "" FUSION
 SG_ Rr_MCUTempWarn_Nidec : 47|2@0+ (1,0) [0|3] "" FUSION
 SG_ Rr_Failcode2_Nidec : 55|8@0+ (1,0) [0|255] "" FUSION
 SG_ Rr_Failcode1_Nidec : 63|8@0+ (1,0) [0|255] "" FUSION
 SG_ Rr_EOP_SpdSet_Nidec : 67|12@0+ (1,0) [0|4000] "RPM" FUSION
 SG_ Rr_LLCTemp_Nidec : 80|9@0+ (1,-40) [-40|214] "Deg^C" FUSION
 SG_ Rr_LLCflowReq_Nidec : 87|6@0+ (0.25,0) [0|15.5] "L/min" FUSION
 SG_ MCU_R_ResetCnt_Sta : 23|8@0+ (1,0) [0|255] "" FUSION

BO_ 925 MCU_N_R3: 8 MCU_N_R
 SG_ Rr_MCU3_HW_Ver_Nidec : 39|16@0+ (1,0) [0|65535] "" FUSION
 SG_ Rr_MCU3_SW_Ver_Nidec : 55|16@0+ (1,0) [0|65535] "" FUSION

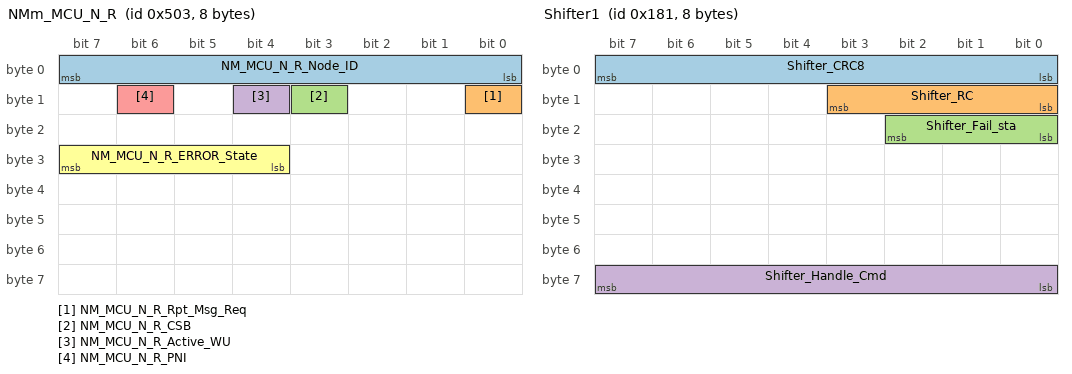
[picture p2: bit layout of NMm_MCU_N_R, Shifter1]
BO_ 1283 NMm_MCU_N_R: 8 MCU_N_R
 SG_ NM_MCU_N_R_Node_ID : 7|8@0+ (1,0) [0|127] "" FUSION
 SG_ NM_MCU_N_R_Rpt_Msg_Req : 8|1@0+ (1,0) [0|1] "" FUSION
 SG_ NM_MCU_N_R_CSB : 11|1@0+ (1,0) [0|1] "" FUSION
 SG_ NM_MCU_N_R_Active_WU : 12|1@0+ (1,0) [0|1] "" FUSION
 SG_ NM_MCU_N_R_PNI : 14|1@0+ (1,0) [0|1] "" FUSION
 SG_ NM_MCU_N_R_ERROR_State : 31|4@0+ (1,0) [0|8] "" FUSION

BO_ 1539 DiagRespFromMCU_N_R: 8 MCU_N_R
 SG_ DiagRespFromMCU_N_R : 7|64@0+ (1,0) [0|0] "" FUSION

BO_ 385 Shifter1: 8 Shifter
 SG_ Shifter_CRC8 : 7|8@0+ (1,0) [0|255] "" FUSION
 SG_ Shifter_RC : 11|4@0+ (1,0) [0|14] "" FUSION
 SG_ Shifter_Fail_sta : 18|3@0+ (1,0) [0|7] "" FUSION
 SG_ Shifter_Handle_Cmd : 63|8@0+ (1,0) [0|255] "" FUSION

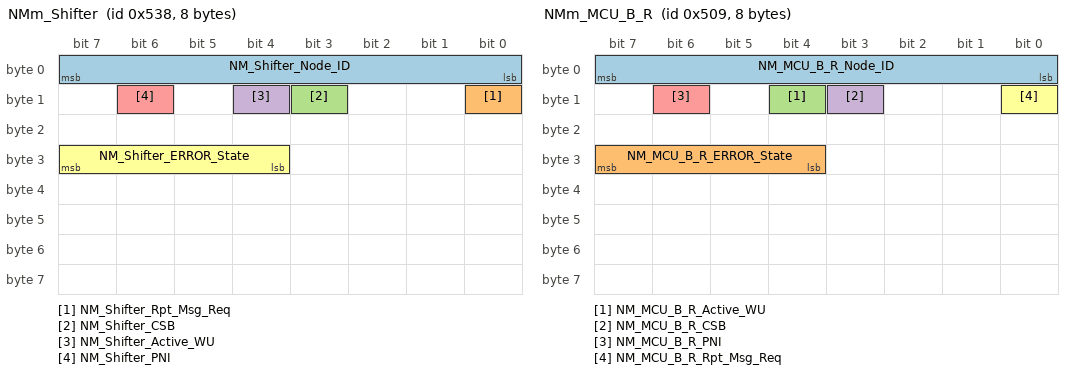
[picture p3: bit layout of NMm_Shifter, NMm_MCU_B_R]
BO_ 1336 NMm_Shifter: 8 Shifter
 SG_ NM_Shifter_Node_ID : 7|8@0+ (1,0) [0|127] "" FUSION
 SG_ NM_Shifter_Rpt_Msg_Req : 8|1@0+ (1,0) [0|1] "" FUSION
 SG_ NM_Shifter_CSB : 11|1@0+ (1,0) [0|1] "" FUSION
 SG_ NM_Shifter_Active_WU : 12|1@0+ (1,0) [0|1] "" FUSION
 SG_ NM_Shifter_PNI : 14|1@0+ (1,0) [0|1] "" FUSION
 SG_ NM_Shifter_ERROR_State : 31|4@0+ (1,0) [0|8] "" FUSION

BO_ 1592 DiagRespFromShifter: 8 Shifter
 SG_ DiagRespFromShifter : 7|64@0+ (1,0) [0|0] "" FUSION

BO_ 1545 DiagRespFromMCU_B_R: 64 MCU_B_R
 SG_ DiagRespFromMCU_B_R : 7|64@0+ (1,0) [0|0] "" FUSION

BO_ 1673 DiagPhysReqToMCU_B_R: 64 FUSION
 SG_ DiagPhysReqToMCU_B_R : 7|64@0+ (1,0) [0|0] "" MCU_B_R

BO_ 1674 DiagPhysReqToMCU_B_F: 64 FUSION
 SG_ DiagPhysReqToMCU_B_F : 7|64@0+ (1,0) [0|0] "" MCU_B_F

BO_ 1546 DiagRespFromMCU_B_F: 64 MCU_B_F
 SG_ DiagRespFromMCU_B_F : 7|64@0+ (1,0) [0|0] "" FUSION

BO_ 1289 NMm_MCU_B_R: 8 MCU_B_R
 SG_ NM_MCU_B_R_Node_ID : 7|8@0+ (1,0) [0|127] "" FUSION
 SG_ NM_MCU_B_R_ERROR_State : 31|4@0+ (1,0) [0|8] "" FUSION
 SG_ NM_MCU_B_R_Active_WU : 12|1@0+ (1,0) [0|1] "" FUSION
 SG_ NM_MCU_B_R_CSB : 11|1@0+ (1,0) [0|1] "" FUSION
 SG_ NM_MCU_B_R_PNI : 14|1@0+ (1,0) [0|1] "" FUSION
 SG_ NM_MCU_B_R_Rpt_Msg_Req : 8|1@0+ (1,0) [0|1] "" FUSION

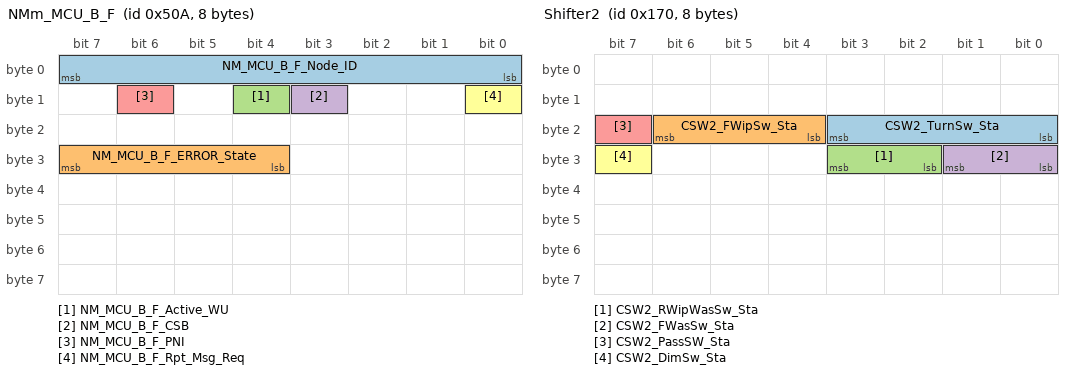
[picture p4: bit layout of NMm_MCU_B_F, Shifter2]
BO_ 1290 NMm_MCU_B_F: 8 MCU_B_F
 SG_ NM_MCU_B_F_Node_ID : 7|8@0+ (1,0) [0|127] "" FUSION
 SG_ NM_MCU_B_F_ERROR_State : 31|4@0+ (1,0) [0|8] "" FUSION
 SG_ NM_MCU_B_F_Active_WU : 12|1@0+ (1,0) [0|1] "" FUSION
 SG_ NM_MCU_B_F_CSB : 11|1@0+ (1,0) [0|1] "" FUSION
 SG_ NM_MCU_B_F_PNI : 14|1@0+ (1,0) [0|1] "" FUSION
 SG_ NM_MCU_B_F_Rpt_Msg_Req : 8|1@0+ (1,0) [0|1] "" FUSION

BO_ 368 Shifter2: 8 Shifter
 SG_ CSW2_TurnSw_Sta : 19|4@0+ (1,0) [0|5] "" FUSION
 SG_ CSW2_FWipSw_Sta : 22|3@0+ (1,0) [0|7] "" FUSION
 SG_ CSW2_RWipWasSw_Sta : 27|2@0+ (1,0) [0|3] "" FUSION
 SG_ CSW2_FWasSw_Sta : 25|2@0+ (1,0) [0|3] "" FUSION
 SG_ CSW2_PassSW_Sta : 23|1@0+ (1,0) [0|1] "" FUSION
 SG_ CSW2_DimSw_Sta : 31|1@0+ (1,0) [0|1] "" FUSION

BO_ 2015 DiagFuncReqOBD: 8 FUSION
 SG_ DiagFuncReqOBD : 7|64@0+ (1,0) [0|0] "" BMS,CCU,MCU_B_F,MCU_B_R

BO_ 564 BMS13: 64 BMS
 SG_ CellVoltage160 : 7|16@0+ (1,0) [0|65534] "mV" FUSION
 SG_ CellVoltage159 : 23|16@0+ (1,0) [0|65534] "mV" FUSION
 SG_ CellVoltage158 : 39|16@0+ (1,0) [0|65534] "mV" FUSION
 SG_ CellVoltage157 : 55|16@0+ (1,0) [0|65534] "mV" FUSION
 SG_ CellVoltage156 : 71|16@0+ (1,0) [0|65534] "mV" FUSION
 SG_ CellVoltage155 : 87|16@0+ (1,0) [0|65534] "mV" FUSION
 SG_ CellVoltage154 : 103|16@0+ (1,0) [0|65534] "mV" FUSION
 SG_ CellVoltage153 : 119|16@0+ (1,0) [0|65534] "mV" FUSION
 SG_ CellVoltage152 : 135|16@0+ (1,0) [0|65534] "mV" FUSION
 SG_ CellVoltage151 : 151|16@0+ (1,0) [0|65534] "mV" FUSION
 SG_ CellVoltage150 : 167|16@0+ (1,0) [0|65534] "mV" FUSION
 SG_ CellVoltage149 : 183|16@0+ (1,0) [0|65534] "mV" FUSION
 SG_ CellVoltage148 : 199|16@0+ (1,0) [0|65534] "mV" FUSION
 SG_ CellVoltage147 : 215|16@0+ (1,0) [0|65534] "mV" FUSION
 SG_ CellVoltage146 : 231|16@0+ (1,0) [0|65534] "mV" FUSION
 SG_ CellVoltage145 : 247|16@0+ (1,0) [0|65534] "mV" FUSION
 SG_ CellVoltage144 : 263|16@0+ (1,0) [0|65534] "mV" FUSION
 SG_ CellVoltage143 : 279|16@0+ (1,0) [0|65534] "mV" FUSION
 SG_ CellVoltage142 : 295|16@0+ (1,0) [0|65534] "mV" FUSION
 SG_ CellVoltage141 : 311|16@0+ (1,0) [0|65534] "mV" FUSION
 SG_ CellVoltage140 : 327|16@0+ (1,0) [0|65534] "mV" FUSION
 SG_ CellVoltage139 : 343|16@0+ (1,0) [0|65534] "mV" FUSION
 SG_ CellVoltage138 : 359|16@0+ (1,0) [0|65534] "mV" FUSION
 SG_ CellVoltage137 : 375|16@0+ (1,0) [0|65534] "mV" FUSION
 SG_ CellVoltage136 : 391|16@0+ (1,0) [0|65534] "mV" FUSION
 SG_ CellVoltage135 : 407|16@0+ (1,0) [0|65534] "mV" FUSION
 SG_ CellVoltage134 : 423|16@0+ (1,0) [0|65534] "mV" FUSION
 SG_ CellVoltage133 : 439|16@0+ (1,0) [0|65534] "mV" FUSION
 SG_ CellVoltage132 : 455|16@0+ (1,0) [0|65534] "mV" FUSION
 SG_ CellVoltage131 : 471|16@0+ (1,0) [0|65534] "mV" FUSION
 SG_ CellVoltage130 : 487|16@0+ (1,0) [0|65534] "mV" FUSION
 SG_ CellVoltage129 : 503|16@0+ (1,0) [0|65534] "mV" FUSION

BO_ 565 BMS14: 64 BMS
 SG_ CellVoltage192 : 7|16@0+ (1,0) [0|65534] "mV" FUSION
 SG_ CellVoltage191 : 23|16@0+ (1,0) [0|65534] "mV" FUSION
 SG_ CellVoltage190 : 39|16@0+ (1,0) [0|65534] "mV" FUSION
 SG_ CellVoltage189 : 55|16@0+ (1,0) [0|65534] "mV" FUSION
 SG_ CellVoltage188 : 71|16@0+ (1,0) [0|65534] "mV" FUSION
 SG_ CellVoltage187 : 87|16@0+ (1,0) [0|65534] "mV" FUSION
 SG_ CellVoltage186 : 103|16@0+ (1,0) [0|65534] "mV" FUSION
 SG_ CellVoltage185 : 119|16@0+ (1,0) [0|65534] "mV" FUSION
 SG_ CellVoltage184 : 135|16@0+ (1,0) [0|65534] "mV" FUSION
 SG_ CellVoltage183 : 151|16@0+ (1,0) [0|65534] "mV" FUSION
 SG_ CellVoltage182 : 167|16@0+ (1,0) [0|65534] "mV" FUSION
 SG_ CellVoltage181 : 183|16@0+ (1,0) [0|65534] "mV" FUSION
 SG_ CellVoltage180 : 199|16@0+ (1,0) [0|65534] "mV" FUSION
 SG_ CellVoltage179 : 215|16@0+ (1,0) [0|65534] "mV" FUSION
 SG_ CellVoltage178 : 231|16@0+ (1,0) [0|65534] "mV" FUSION
 SG_ CellVoltage177 : 247|16@0+ (1,0) [0|65534] "mV" FUSION
 SG_ CellVoltage176 : 263|16@0+ (1,0) [0|65534] "mV" FUSION
 SG_ CellVoltage175 : 279|16@0+ (1,0) [0|65534] "mV" FUSION
 SG_ CellVoltage174 : 295|16@0+ (1,0) [0|65534] "mV" FUSION
 SG_ CellVoltage173 : 311|16@0+ (1,0) [0|65534] "mV" FUSION
 SG_ CellVoltage172 : 327|16@0+ (1,0) [0|65534] "mV" FUSION
 SG_ CellVoltage171 : 343|16@0+ (1,0) [0|65534] "mV" FUSION
 SG_ CellVoltage170 : 359|16@0+ (1,0) [0|65534] "mV" FUSION
 SG_ CellVoltage169 : 375|16@0+ (1,0) [0|65534] "mV" FUSION
 SG_ CellVoltage168 : 391|16@0+ (1,0) [0|65534] "mV" FUSION
 SG_ CellVoltage167 : 407|16@0+ (1,0) [0|65534] "mV" FUSION
 SG_ CellVoltage166 : 423|16@0+ (1,0) [0|65534] "mV" FUSION
 SG_ CellVoltage165 : 439|16@0+ (1,0) [0|65534] "mV" FUSION
 SG_ CellVoltage164 : 455|16@0+ (1,0) [0|65534] "mV" FUSION
 SG_ CellVoltage163 : 471|16@0+ (1,0) [0|65534] "mV" FUSION
 SG_ CellVoltage162 : 487|16@0+ (1,0) [0|65534] "mV" FUSION
 SG_ CellVoltage161 : 503|16@0+ (1,0) [0|65534] "mV" FUSION

BO_ 566 BMS15: 64 BMS
 SG_ CellVoltage216 : 135|16@0+ (1,0) [0|65534] "mV" FUSION
 SG_ CellVoltage215 : 151|16@0+ (1,0) [0|65534] "mV" FUSION
 SG_ CellVoltage214 : 167|16@0+ (1,0) [0|65534] "mV" FUSION
 SG_ CellVoltage213 : 183|16@0+ (1,0) [0|65534] "mV" FUSION
 SG_ CellVoltage212 : 199|16@0+ (1,0) [0|65534] "mV" FUSION
 SG_ CellVoltage211 : 215|16@0+ (1,0) [0|65534] "mV" FUSION
 SG_ CellVoltage210 : 231|16@0+ (1,0) [0|65534] "mV" FUSION
 SG_ CellVoltage209 : 247|16@0+ (1,0) [0|65534] "mV" FUSION
 SG_ CellVoltage208 : 263|16@0+ (1,0) [0|65534] "mV" FUSION
 SG_ CellVoltage207 : 279|16@0+ (1,0) [0|65534] "mV" FUSION
 SG_ CellVoltage206 : 295|16@0+ (1,0) [0|65534] "mV" FUSION
 SG_ CellVoltage205 : 311|16@0+ (1,0) [0|65534] "mV" FUSION
 SG_ CellVoltage204 : 327|16@0+ (1,0) [0|65534] "mV" FUSION
 SG_ CellVoltage203 : 343|16@0+ (1,0) [0|65534] "mV" FUSION
 SG_ CellVoltage202 : 359|16@0+ (1,0) [0|65534] "mV" FUSION
 SG_ CellVoltage201 : 375|16@0+ (1,0) [0|65534] "mV" FUSION
 SG_ CellVoltage200 : 391|16@0+ (1,0) [0|65534] "mV" FUSION
 SG_ CellVoltage199 : 407|16@0+ (1,0) [0|65534] "mV" FUSION
 SG_ CellVoltage198 : 423|16@0+ (1,0) [0|65534] "mV" FUSION
 SG_ CellVoltage197 : 439|16@0+ (1,0) [0|65534] "mV" FUSION
 SG_ CellVoltage196 : 455|16@0+ (1,0) [0|65534] "mV" FUSION
 SG_ CellVoltage195 : 471|16@0+ (1,0) [0|65534] "mV" FUSION
 SG_ CellVoltage194 : 487|16@0+ (1,0) [0|65534] "mV" FUSION
 SG_ CellVoltage193 : 503|16@0+ (1,0) [0|65534] "mV" FUSION

BO_ 409 MCU_FVT_R1: 20 MCU_B_R
 SG_ MCU_FVT_R_TMSpd_Sta : 55|16@0+ (1,-22000) [-22000|43535] "RPM" FUSION
 SG_ MCU_FVT_R_EDUTqReq_Fbk : 71|16@0+ (0.1,-1022) [-1022|5531.5] "" FUSION
 SG_ MCU_FVT_R_Failcode3_Sta : 95|8@0+ (1,0) [0|255] "" FUSION
 SG_ MCU_FVT_R_MCUErr_Sta : 87|8@0+ (1,0) [0|255] "" FUSION
 SG_ MCU_FVT_R_OilTemp_Sta : 32|9@0+ (1,-40) [-40|471] "Deg^C" FUSION
 SG_ MCU_FVT_R_MCUBAT_Sta : 16|9@0+ (0.2,0) [0|102.2] "V" FUSION
 SG_ MCU_FVT_R_MCUSys_Sta : 23|4@0+ (1,0) [0|15] "" FUSION
 SG_ MCU_FVT_R_HeatingOP_Sta : 33|1@0+ (1,0) [0|1] "" FUSION
 SG_ MCU_FVT_R_BoostOP_Sta : 17|1@0+ (1,0) [0|1] "" FUSION

BO_ 410 MCU_FVT_F1: 20 MCU_B_F
 SG_ MCU_FVT_F_TMSpd_Sta : 55|16@0+ (1,-22000) [-22000|43535] "RPM" FUSION
 SG_ MCU_FVT_F_EDUTqReq_Fbk : 71|16@0+ (0.1,-1022) [-1022|5531.5] "" FUSION
 SG_ MCU_FVT_F_Failcode3_Sta : 95|8@0+ (1,0) [0|255] "" FUSION
 SG_ MCU_FVT_F_MCUErr_Sta : 87|8@0+ (1,0) [0|255] "" FUSION
 SG_ MCU_FVT_F_OilTemp_Sta : 32|9@0+ (1,-40) [-40|471] "Deg^C" FUSION
 SG_ MCU_FVT_F_MCUBAT_Sta : 16|9@0+ (0.2,0) [0|102.2] "V" FUSION
 SG_ MCU_FVT_F_MCUSys_Sta : 23|4@0+ (1,0) [0|15] "" FUSION
 SG_ MCU_FVT_F_HeatingOP_Sta : 33|1@0+ (1,0) [0|1] "" FUSION
 SG_ MCU_FVT_F_BoostOP_Sta : 17|1@0+ (1,0) [0|1] "" FUSION

BO_ 1731 DiagPhysReqToEOP_FVT_R: 8 FUSION
 SG_ DiagPhysReqToEOP_FVT_R : 7|64@0+ (1,0) [0|0] "" MCU_B_R

BO_ 1603 DiagRespFromEOP_FVT_R: 8 MCU_B_R
 SG_ DiagRespFromEOP_FVT_R : 7|64@0+ (1,0) [0|0] "" FUSION

BO_ 1732 DiagPhysReqToEOP_FVT_F: 8 FUSION
 SG_ DiagPhysReqToEOP_FVT_F : 7|64@0+ (1,0) [0|0] "" MCU_B_F

BO_ 1604 DiagRespFromEOP_FVT_F: 8 MCU_B_F
 SG_ DiagRespFromEOP_FVT_F : 7|64@0+ (1,0) [0|0] "" FUSION

CM_ BO_ 1183 "for D31L NIDEC MCU";
CM_ BO_ 368 "Shifter and CSW gen2 CAN ECU";
CM_ SG_ 496 SysPwrSta "System power mode";
CM_ SG_ 496 PowerUpFault "Power up fault";
CM_ SG_ 496 PowerUpState "Power up mode";
CM_ SG_ 496 PowerDownFault "Power down fault";
CM_ SG_ 496 PowerDownState "Power down state";
CM_ SG_ 496 TCountSta "Timmer counting state";
CM_ SG_ 496 PwrStaConstraint "Power state constraint";
CM_ SG_ 496 PwrStaSelect "Power state select";
CM_ SG_ 496 Rr_TqSource "Rear EDU Torque Source";
CM_ SG_ 496 PwrUpReq "Power up request";
CM_ SG_ 496 HVTHCMSysAvail "HV THCM syetem avaliable state";
CM_ SG_ 496 LVBattVoltSta "LV battery voltage state";
CM_ SG_ 496 Fr_TqSource "Front EDU Torque Source";
CM_ SG_ 496 VehHVPwrAvail4THCM "Vehicle HV power avalible for THCM";
CM_ SG_ 496 HVRlyOpFail "HV relay opend fail";
CM_ SG_ 496 SysAllowReadySta "System allow  to ready state";
CM_ SG_ 496 VCURRDoorSta "VCU RR door state";
CM_ SG_ 496 VCURLDoorSta "VCU RL door state";
CM_ SG_ 496 VCUFRDoorSta "VCU FR door state";
CM_ SG_ 496 VCUFLDoorSta "VCU FL door state";
CM_ SG_ 496 VCUBrkSWSta "VCU brake SW state";
CM_ SG_ 496 PwrStaONTOIVIPopT "Count down time value for power state ON timeout IVI popup";
CM_ SG_ 496 PwrStaTOSta "Power state timeout state";
CM_ SG_ 496 PwrStaONTOIVIPopReq "Power state ON timeout IVI popup";
CM_ SG_ 496 MCUActDisFail "MCU active discharge fail";
CM_ SG_ 496 TimerAllowSleep "Timer allow sleep flag.";
CM_ SG_ 496 LVSilentChrgReq "LV Silent Chrge Request";
CM_ SG_ 496 LVSilentChrgLv "LV silent charging level";
CM_ SG_ 496 LVSilentChrgSta "LV Silent Chrge State";
CM_ SG_ 496 SilentChkAllowSleep "Silent charge check allow sleep flag.";
CM_ SG_ 496 SchedChgTOSta "Schedule charge timeout state";
CM_ SG_ 496 LVChrgHoldTAct "Calibration value for LV charge hold time";
CM_ SG_ 496 EVCCAplusPwrUpReq "EVCC A-plus signal power up request.";
CM_ SG_ 496 PMMAllowECUSleep "PMM allow ECU sleep flag.";
CM_ SG_ 496 LVBattChrgtimeAct "V Battery charge time.";
CM_ SG_ 496 FDADC12VDetAvg "FD ADC 12V detect voltage average value";
CM_ SG_ 496 WisrBootReason "FDC wisr boot reason";
CM_ SG_ 496 PmicBootReason "FDC PMIC boot reason";
CM_ SG_ 496 FDC_VMC_ActStESCYaw_Sta "Actual standard ESC yaw rate";
CM_ SG_ 496 FDC_VMC_LongAcc_Sta "longitudinal acceleration";
CM_ SG_ 496 FDC_VCU_VehActSpd_Sta "Actual max slide rate";
CM_ SG_ 496 FDC_VCU_ActMaxSlideRate_Sta "Actual max slide rate";
CM_ SG_ 496 FDC_VCU_SlideRegenLimTq_Sta "Slide regen limit tq";
CM_ SG_ 496 FDC_VCU_DTCCarousel_Sta "DTC carousel";
CM_ SG_ 496 FDC_VCU_VehMalfunLevel_Sta "Vehicle malfunction level";
CM_ SG_ 496 FDC_VCU_RWDRDCActive_Sta "RWD RDC active";
CM_ SG_ 496 FDC_VCU_AllowMovThd_OTA_Sta "OTA allow move threshold";
CM_ SG_ 496 FDC_VCU_RegenTqLimitEn_Sta "Regen torque limit enable";
CM_ SG_ 496 FDC_VCU_ForceP_Cmd "Force P gear command";
CM_ SG_ 496 FDC_VCU_PwrReq_OTA_Sta "Power request by OTA";
CM_ SG_ 496 FDC_VCU_OTAPwrReqOFFChk_Sta "VCU check state of OTA power request OFF";
CM_ SG_ 496 FDC_VCU_OTAPwrReqStdChk_Sta "VCU check state of OTA power request STANDBY";
CM_ SG_ 496 FDADC12VDet "FD ADC 12V detect voltage value";
CM_ SG_ 496 FDC_VCU_EAPS2Raw_Sta "APS2 raw reading";
CM_ SG_ 496 FDC_VCU_EAPS1Raw_Sta "APS1 raw reading";
CM_ SG_ 496 FDC_VCU_EAPS2Min_Sta "APS2 minimum point";
CM_ SG_ 496 FDC_VCU_EAPS1Min_Sta "APS1 minimum point";
CM_ SG_ 496 FDC_VCU_BrakeSigMatrix_Sta "Brake signal matrix";
CM_ SG_ 496 FDC_VCU_CANBrkSW2Sta_Sta "Brake switch state from CAN";
CM_ SG_ 496 FDC_VCU_BrkPedalPosSta_Sta "Brake pedal position state";
CM_ SG_ 496 FDC_VCU_LowIdleAccPedal_Sta "Accel pedal low idle state";
CM_ SG_ 496 FDC_SYS_PmicBootPath "Output a 4 bytes raw value for we can identify the FDC boot path.";
CM_ SG_ 496 FDC_VCU_LVStaDropQukCnt_Sta "Count number of LV state drop quickly  ";
CM_ SG_ 496 FDC_VCU_LVChrgFreqCnt_Sta "Count number of LV charge frequently level";
CM_ SG_ 496 FDC_VCU_FrRateLimitInc_Sta "Fr Increase Rate Limit Tq";
CM_ SG_ 496 FDC_VCU_RrRateLimitInc_Sta "Rr Increase Rate Limit Tq";
CM_ SG_ 496 FDC_VCU_FrRateLimitDec_Sta "Fr Decrease Rate Limit Tq";
CM_ SG_ 496 FDC_VCU_RrRateLimitDec_Sta "Rr Decrease Rate Limit Tq";
CM_ SG_ 496 FDC_VCU_FrFirstOrderInpTs "Fr 1st Order Input Ts";
CM_ SG_ 496 FDC_VCU_RrFirstOrderInpTs "Rr 1st Order Input Ts";
CM_ SG_ 496 FDC_VCU_BOSEnable_Sta "BOS enable flag";
CM_ SG_ 534 BCM_Buzzer_Req "BCM Buzzer Request";
CM_ SG_ 534 TailgateRemote "Remote Control PTG";
CM_ SG_ 534 RoomLampL "Room Lamp Low";
CM_ SG_ 534 RoomLampH "Room Lamp High";
CM_ SG_ 534 DimmerEN "Dimmer Enable";
CM_ SG_ 534 BCM_DoorLock_Sta "BCM Unlock Single Door Setting";
CM_ SG_ 534 HornCtrl "Horn Control";
CM_ SG_ 534 Dimmer "Dimmer";
CM_ SG_ 534 LockSetting "BCM Unlock Single Door Setting";
CM_ SG_ 534 LTurnLP "Left Turn Lamp";
CM_ SG_ 534 RTurnLP "Right Turn Lamp";
CM_ SG_ 534 AntitheftSta "Anti-theft Status";
CM_ SG_ 534 AntiTheftSeatFold "Anti-theft Seat Fold";
CM_ SG_ 534 CrashDetd "Crash Detected";
CM_ SG_ 534 L_APM_WdwEnable "Enable windows movement";
CM_ SG_ 534 RDRL "Right DRL";
CM_ SG_ 534 ReverseLamp "ReverseLamp";
CM_ SG_ 534 BrakeLamp "BrakeLamp";
CM_ SG_ 534 LBSD "Left BSD";
CM_ SG_ 534 RBSD "Right BSD";
CM_ SG_ 534 Fr_FogLamp "Front Fog Lamp";
CM_ SG_ 534 Rr_FogLamp "Rear Fog Lamp";
CM_ SG_ 534 HazardSW "Hazard SW";
CM_ SG_ 534 Rr_Wiper "Rear Wiper";
CM_ SG_ 534 WiperFixMode "Wiper Fix Mode";
CM_ SG_ 534 WasherCtrl "WasherControl";
CM_ SG_ 534 L_Beam "Low Beam";
CM_ SG_ 534 H_Beam "High Beam";
CM_ SG_ 534 PosLamp "PositionLamp";
CM_ SG_ 534 LDRL "Left DRL";
CM_ SG_ 534 MirrorDefog "Mirror Defog";
CM_ SG_ 534 Rr_Defog "Rear Defog";
CM_ SG_ 534 TrunkRel "Trunk Release";
CM_ SG_ 534 TailgateHDSW "Tailgate Handle SW";
CM_ SG_ 534 MirrorCtrl "Mirror Control";
CM_ SG_ 534 Fr_Wiper_H "Front Wiper High";
CM_ SG_ 534 Fr_Wiper_L "Front Wiper LOW";
CM_ SG_ 534 CTDCtrl "Door Lock Control";
CM_ SG_ 534 Fr_ChargingDoorCtrl "Front Charging Door Control";
CM_ SG_ 534 Rr_ChargingDoorCtrl "Rear Charging Door Control";
CM_ SG_ 534 CTDLockSW "Central Door Lock SW";
CM_ SG_ 534 CTDUnlockSW "Central Door Unlock SW";
CM_ SG_ 534 DrDoorSW "Driver Side Door Switch";
CM_ SG_ 534 PsDoorSW "Passenger Side Door Switch";
CM_ SG_ 534 RLDoorSW "Rear Left Door Switch";
CM_ SG_ 534 RRDoorSW "Rear Right Door Switch";
CM_ SG_ 534 AllDoorSW "All Door Switch";
CM_ SG_ 534 DoorLockIND "Door Lock Indicator";
CM_ SG_ 534 HoodSW "Hood Switch";
CM_ SG_ 534 Tailgate_SW "Tailgate Switch";
CM_ SG_ 884 Req_V2LSwOn "FD asks IVI popup wording for SW on.";
CM_ SG_ 884 Req_V2L_IVI_Popup "FD asks IVI popup wording for V2L fault.";
CM_ SG_ 884 FDC_V2L_OBCIntrV2L_Cmd "Request the internal discharge relay status of the OBC.";
CM_ SG_ 884 FDC_V2L_OBCExtrV2L_Cmd "Request the external discharge relay status of the OBC.";
CM_ SG_ 884 Req_OBCV2LEna "FD trigs OBC V2L enabled.";
CM_ SG_ 1080 OTA_Progress_Rate "MDA download or update progress rate";
CM_ SG_ 1080 OTA_DL_Available "Fusion MDA available for download";
CM_ SG_ 1080 OTA_Mode "Vehicel OTA mode Status";
CM_ SG_ 1080 OTA_Network_Type "Vehicle Network Type";
CM_ SG_ 1080 OTA_MDA_Status "Fusion Master OTA agent status";
CM_ SG_ 1080 OTA_Updating_ECU_8bit "Fusion MDA is updating ECU";
CM_ SG_ 1080 OTA_DL_Speed "Firmware Package download speed";
CM_ SG_ 1080 OTA_InVehicle_FW "In Vehicle Firmware Version Status";
CM_ SG_ 1080 OTA_TBOXResetReq "TBOX Reset Request";
CM_ SG_ 1080 OTA_Lock_Req "OTA Lock request to DKC";
CM_ SG_ 1080 OTA_Remained_Time "Download/Upgrade Estimated Time";
CM_ SG_ 1080 OTA_Update_Available "Fusion MDA available for update";
CM_ SG_ 1080 OTA_Permit_Agreed "Download/Upgrade coundition check result";
CM_ SG_ 1080 OTA_Debug_Code "OTA Error Code for Debug";
CM_ SG_ 1080 OTA_Emergency_Sta "Fusion emergency state";
CM_ SG_ 1183 IVI_Time_Minute_toNidec "IVI_GPS Satellite Time_Minute
FDC for D31L NIDEC MCU";
CM_ SG_ 1183 IVI_Time_Second_toNidec "IVI_GPS Satellite Time_Second
FDC for D31L NIDEC MCU";
CM_ SG_ 1183 IVI_Time_Day_toNidec "IVI_GPS Satellite Time_Day
FDC for D31L NIDEC MCU";
CM_ SG_ 1183 IVI_Time_Hour_toNidec "IVI_GPS Satellite Time_Hour
FDC for D31L NIDEC MCU";
CM_ SG_ 1183 IVI_Time_Month_toNidec "IVI_GPS Satellite Time_Month
FDC for D31L NIDEC MCU";
CM_ SG_ 1280 NM_FUSION_Node_ID "Source Node Identifier";
CM_ SG_ 1280 NM_FUSION_Rpt_Msg_Req "Repeat Message Request";
CM_ SG_ 1280 NM_FUSION_CSB "NM Coordinator Sleep Bit";
CM_ SG_ 1280 NM_FUSION_Active_WU "Active Wakeup Bit";
CM_ SG_ 1280 NM_FUSION_PNI "Partial Network Information Bit (PNI)";
CM_ SG_ 1280 NM_FUSION_ERROR_State "Defined Error states of the CAN Controller";
CM_ SG_ 1667 DiagPhysReqToMCU_N_R "Diagnostic Physical Request to MCU_R";
CM_ SG_ 1672 DiagPhysReqToMCU_N_F "Diagnostic Physical Request to MCU_F";
CM_ SG_ 1683 DiagPhysReqToEOP_R "Diagnostic Physical Request to EOP_R";
CM_ SG_ 1688 DiagPhysReqToEOP_F "Diagnostic Physical Request to EOP_F";
CM_ SG_ 1699 DiagPhysReqToEBM "Diagnostic Physical Request to EBM";
CM_ SG_ 1712 DiagPhysReqToBMS "Diagnostic Physical Request to BMS";
CM_ SG_ 1715 DiagPhysReqToCCU "Diagnostic Physical Request to CCU";
CM_ SG_ 1720 DiagPhysReqToShifter "Diagnostic Physical Request to Shifter";
CM_ SG_ 2000 DiagFuncReqFT "Diagnostic Functional Request from Tester";
CM_ SG_ 401 Fr_MCU1Chksum "Checksum of MCU_F1(AUTOSAR E2E profile 1)

Polynomial 0x1D (x^8+x^4+x^3+x^2+1) Both start value and XOR value are 0x00.";
CM_ SG_ 401 Fr_MCU1RolCnt "MCU1_F1 4-bit rolling counter
It starts counting from 0, ends at 14 and returns to zero (0~14).";
CM_ SG_ 401 Fr_MCUSysSta "Front MCU System Status";
CM_ SG_ 401 MCUWarn_F "MCU warning signal_Front";
CM_ SG_ 401 Fr_MCUReady "Front MCU Ready";
CM_ SG_ 401 Fr_MCUBAT "Front Bat Voltage";
CM_ SG_ 401 Fr_MCUIGN_sta "IGN ON/OFF Status";
CM_ SG_ 401 Fr_Reserved_bits "Front Reserved bits";
CM_ SG_ 401 Fr_RegenAvailTq "Front RegenerationTorque Available";
CM_ SG_ 401 Fr_MotorAvailTq "Front Motor Torque Available";
CM_ SG_ 401 Fr_TMiq "Front TM iq Feedback";
CM_ SG_ 401 Fr_TMid "Front TM id Feedback";
CM_ SG_ 401 Fr_MCUErr "Front MCU Error Code";
CM_ SG_ 401 Fr_TMTemp "Front TM Temperature";
CM_ SG_ 401 Fr_MCUTemp "Front MCU Temperature";
CM_ SG_ 401 Fr_MCUDCBusCurr "Front MCU DC Current";
CM_ SG_ 401 Fr_MCUDCBusVolt "Front MCU DC-Bus Voltage";
CM_ SG_ 401 Fr_MCUReady4Pre "Front MCU Ready for Precharge";
CM_ SG_ 401 Fr_ActvDmpDisabSta "Front MCU Low speed active damping disable status";
CM_ SG_ 401 Fr_EDUDrtSta "Front EDU Torque Derating Status";
CM_ SG_ 401 Fr_MCUDischrgSta "Front MCU Discharge Status";
CM_ SG_ 401 Fr_TMSpd "Front TM speed";
CM_ SG_ 401 Fr_EDURealTMTq "Front EDU Real Torque from TM";
CM_ SG_ 401 Fr_EDUTqReqFbk "Front EDU Torque Request Feedback";
CM_ SG_ 401 Fr_MCUEnaSta "Front MCU Enable Status";
CM_ SG_ 401 Fr_EDUOpratingSta "Front EDU Torque/Speed Status";
CM_ SG_ 401 Fr_EDURotateDirction "Front EDU Direction Status";
CM_ SG_ 401 MCU_B_F_IGBTDdeTemp_Sta "Front IGBTDde of MCU Temp";
CM_ SG_ 401 MCU_B_F_RealPwrKw_Sta "Front Real Power_Kw";
CM_ SG_ 404 Fr_MCU2Chksum "Checksum of MCU_F2(AUTOSAR E2E profile 1)

Polynomial 0x1D (x^8+x^4+x^3+x^2+1) Both start value and XOR value are 0x00.";
CM_ SG_ 404 Fr_MCU2RolCnt "MCU_F2 4-bit rolling counter
It starts counting from 0, ends at 14 and returns to zero (0~14).";
CM_ SG_ 404 Fr_LLCflowReq "Front request LLC flow rate";
CM_ SG_ 404 Fr_CoolanttempReq "LLC coolant temp Request";
CM_ SG_ 404 Fr_Failcodehistory1 "Front Failcode history status";
CM_ SG_ 404 Fr_Failcodehistory2 "Front Failcode history status";
CM_ SG_ 404 Fr_TMTempWarn "Front TM Temperature Warning";
CM_ SG_ 404 Fr_MCUTempWarn "Front MCU Temperature Warning";
CM_ SG_ 404 Fr_Failcode2 "Front Detail fail code";
CM_ SG_ 404 Fr_Failcode1 "Front Detail fail code";
CM_ SG_ 404 Fr_LLCTemp "Front LLC temperature";
CM_ SG_ 404 Fr_MCU_HW_Ver "Front MCU Hardware version";
CM_ SG_ 404 Fr_MCU_SW_Ver "Front MCU Software version";
CM_ SG_ 404 MCU_B_F_LLCTempWarn_Sta "Front LLC temperature Warning";
CM_ SG_ 404 MCU_B_F_FailLv_Sta "Front EDU Failure LVL Status";
CM_ SG_ 404 MCU_B_F_KL302TqCnt_Sta "Front KL30 to Torque mode counter";
CM_ SG_ 406 Fr_MCU1Chksum_Nidec "Front MCU1 Frame checksum(SAEJ1850) 
x^8+x^4+x^3+x^2+1
It shall use 0xFF as the start value and XOR value.";
CM_ SG_ 406 MCUWarn_F_Nidec "Front MCU warning signal from Nidec";
CM_ SG_ 406 Fr_MCUReady_Nidec "Front MCU Ready from Nidec";
CM_ SG_ 406 Fr_MCU1RolCnt_Nidec "Front MCU1 4 bits Process counter";
CM_ SG_ 406 Fr_MCUSysSta_Nidec "Front MCU System Status from Nidec";
CM_ SG_ 406 Fr_MCUBAT_Nidec "Front Bat Voltage from Nidec";
CM_ SG_ 406 Fr_MCUIGN_sta_Nidec "IGN ON/OFF Status from Nidec";
CM_ SG_ 406 Fr_Reserved_bits_Nidec "Front Reserved bits from Nidec";
CM_ SG_ 406 Fr_RegenAvailTq_Nidec "Front RegenerationTorque Available from Nidec";
CM_ SG_ 406 Fr_MotorAvailTq_Nidec "Front Motor Torque Available from Nidec";
CM_ SG_ 406 Fr_TMiq_Nidec "Front TM iq Feedback from Nidec";
CM_ SG_ 406 Fr_TMid_Nidec "Front TM id Feedback from Nidec";
CM_ SG_ 406 Fr_MCUErr_Nidec "Front MCU Error Code from Nidec";
CM_ SG_ 406 Fr_TMTemp_Nidec "Front TM Temperature from Nidec";
CM_ SG_ 406 Fr_MCUTemp_Nidec "Front MCU Temperature from Nidec";
CM_ SG_ 406 Fr_MCUDCBusCurr_Nidec "Front MCU DC Current from Nidec";
CM_ SG_ 406 Fr_MCUDCBusVolt_Nidec "Front MCU DC-Bus Voltage from Nidec";
CM_ SG_ 406 Fr_MCUReady4Pre_Nidec "Front MCU Ready for Precharge from Nidec";
CM_ SG_ 406 Fr_ActvDmpDisabSta_Nidec "Front MCU Low speed active damping disable status from Nidec";
CM_ SG_ 406 Fr_EDUDrtSta_Nidec "Front EDU Torque Derating Status from Nidec";
CM_ SG_ 406 Fr_MCUDischrgSta_Nidec "Front MCU Discharge Status from Nidec";
CM_ SG_ 406 Fr_TMSpd_Nidec "Front TM speed from Nidec";
CM_ SG_ 406 Fr_EDURealTMTq_Nidec "Front EDU Real Torque from TM from Nidec";
CM_ SG_ 406 Fr_EDUTqReqFbk_Nidec "Front EDU Torque Request Feedback from Nidec";
CM_ SG_ 406 Fr_MCUEnaSta_Nidec "Front MCU Enable Status from Nidec";
CM_ SG_ 406 Fr_EDUOpratingSta_Nidec "Front EDU Torque/Speed Status from Nidec";
CM_ SG_ 406 Fr_EDURotateDirction_Nidec "Front EDU Direction Status from Nidec";
CM_ SG_ 408 Fr_MCU2Chksum_Nidec "Front MCU2 Frame checksum(SAEJ1850) 
x^8+x^4+x^3+x^2+1
It shall use 0xFF as the start value and XOR value.";
CM_ SG_ 408 Fr_MCU2RolCnt_Nidec "Front MCU2 4bits Process counter";
CM_ SG_ 408 Fr_CoolanttempReq_Nidec "LLC coolant temp Request from Nidec";
CM_ SG_ 408 Fr_Failcodehistory1_Nidec "Front Failcode history status from Nidec";
CM_ SG_ 408 Fr_Failcodehistory2_Nidec "Front Failcode history status from Nidec";
CM_ SG_ 408 Fr_TMTempWarn_Nidec "Front TM Temperature Warning from Nidec";
CM_ SG_ 408 Fr_MCUTempWarn_Nidec "Front MCU Temperature Warning from Nidec";
CM_ SG_ 408 Fr_Failcode2_Nidec "Front Detail fail code from Nidec";
CM_ SG_ 408 Fr_Failcode1_Nidec "Front Detail fail code from Nidec";
CM_ SG_ 408 Fr_EOP_SpdSet_Nidec "Front MCU request EOP Speed from Nidec";
CM_ SG_ 408 Fr_LLCTemp_Nidec "Front LLC temperature from Nidec";
CM_ SG_ 408 Fr_LLCflowReq_Nidec "Front request LLC flow rate from Nidec";
CM_ SG_ 408 MCU_F_ResetCnt_Sta "Front  MCU Reset counter";
CM_ SG_ 921 Fr_MCU_HW_Ver_Nidec "Front MCU Hardware version from Nidec";
CM_ SG_ 921 Fr_MCU_SW_Ver_Nidec "Front MCU Software version from Nidec";
CM_ SG_ 1288 NM_MCU_N_F_Node_ID "Source Node Identifier";
CM_ SG_ 1288 NM_MCU_N_F_Rpt_Msg_Req "Repeat Message Request";
CM_ SG_ 1288 NM_MCU_N_F_CSB "NM Coordinator Sleep Bit";
CM_ SG_ 1288 NM_MCU_N_F_Active_WU "Active Wakeup Bit";
CM_ SG_ 1288 NM_MCU_N_F_PNI "Partial Network Information Bit (PNI)";
CM_ SG_ 1288 NM_MCU_N_F_ERROR_State "Defined Error states of the CAN Controller";
CM_ SG_ 1544 DiagRespFromMCU_N_F "Diagnostic Response from MCU_F";
CM_ SG_ 400 Rr_MCU1Chksum "Checksum of MCU_R1(AUTOSAR E2E profile 1)

Polynomial 0x1D (x^8+x^4+x^3+x^2+1) Both start value and XOR value are 0x00.";
CM_ SG_ 400 Rr_MCU1RolCnt "MCU_R1 4-bit rolling counter
It starts counting from 0, ends at 14 and returns to zero (0~14).";
CM_ SG_ 400 Rr_MCUSysSta "Rear MCU System Status";
CM_ SG_ 400 MCUWarn_R "MCU warning signal_Rear";
CM_ SG_ 400 Rr_MCUReady "Rear MCU Ready";
CM_ SG_ 400 Rr_MCUBAT "Rear  Bat Voltage";
CM_ SG_ 400 Rr_MCUIGN_sta "IGN ON/OFF Status";
CM_ SG_ 400 Rr_Reserved_bits "Rear  Reserved bits";
CM_ SG_ 400 Rr_RegenAvailTq "Rear RegenerationTorque Available";
CM_ SG_ 400 Rr_MotorAvailTq "Rear Motor Torque Available";
CM_ SG_ 400 Rr_TMiq "Rear  TM iq Feedback";
CM_ SG_ 400 Rr_TMid "Rear  TM id Feedback";
CM_ SG_ 400 Rr_MCUErr "Rear  MCU Error Code";
CM_ SG_ 400 Rr_TMTemp "Rear TM Temperature";
CM_ SG_ 400 Rr_MCUTemp "Rear MCU Temperature";
CM_ SG_ 400 Rr_MCUDCBusCurr "Rear  MCU DC Current";
CM_ SG_ 400 Rr_MCUDCBusVolt "Rear MCU DC-Bus Voltage";
CM_ SG_ 400 Rr_MCUReady4Pre "Rear MCU Ready for Precharge";
CM_ SG_ 400 Rr_ActvDmpDisabSta "Rear MCU Low speed active damping disable status";
CM_ SG_ 400 Rr_EDUDrtSta "Rear EDU Torque Derating Status";
CM_ SG_ 400 Rr_MCUDischrgSta "Rear MCU Discharge Status";
CM_ SG_ 400 Rr_TMSpd "Rear TM speed";
CM_ SG_ 400 Rr_EDURealTMTq "Rear EDU Real Torque from TM";
CM_ SG_ 400 Rr_EDUTqReqFbk "Rear EDU Torque Request Feedback";
CM_ SG_ 400 Rr_MCUEnaSta "Rear MCU Enable Status";
CM_ SG_ 400 Rr_EDUOpratingSta "Rear EDU Torque/Speed Status";
CM_ SG_ 400 Rr_EDURotateDirction "Rear EDU Direction Status";
CM_ SG_ 400 MCU_B_R_RealPwrKw_Sta "Rear Real Power_Kw";
CM_ SG_ 400 MCU_B_R_IGBTDdeTemp_Sta "Rear IGBTDde of MCU Temp";
CM_ SG_ 402 Rr_MCU1Chksum_Nidec "Front MCU1 Frame checksum(SAEJ1850) 
x^8+x^4+x^3+x^2+1
It shall use 0xFF as the start value and XOR value.";
CM_ SG_ 402 MCUWarn_R_Nidec "Rear MCU warning signal from Nidec";
CM_ SG_ 402 Rr_MCU1RolCnt_Nidec "Front MCU1 4 bits Process counter";
CM_ SG_ 402 Rr_MCUSysSta_Nidec "Rear MCU System Status from Nidec";
CM_ SG_ 402 Rr_MCUBAT_Nidec "Rear  Bat Voltage from Nidec";
CM_ SG_ 402 Rr_MCUIGN_sta_Nidec "IGN ON/OFF Status from Nidec";
CM_ SG_ 402 Rr_Reserved_bits_Nidec "Rear  Reserved bits from Nidec";
CM_ SG_ 402 Rr_RegenAvailTq_Nidec "Rear RegenerationTorque Available from Nidec";
CM_ SG_ 402 Rr_MotorAvailTq_Nidec "Rear Motor Torque Available from Nidec";
CM_ SG_ 402 Rr_TMiq_Nidec "Rear  TM iq Feedback from Nidec";
CM_ SG_ 402 Rr_TMid_Nidec "Rear  TM id Feedback from Nidec";
CM_ SG_ 402 Rr_MCUErr_Nidec "Rear  MCU Error Code from Nidec";
CM_ SG_ 402 Rr_TMTemp_Nidec "Rear TM Temperature from Nidec";
CM_ SG_ 402 Rr_MCUTemp_Nidec "Rear MCU Temperature from Nidec";
CM_ SG_ 402 Rr_MCUDCBusCurr_Nidec "Rear  MCU DC Current from Nidec";
CM_ SG_ 402 Rr_MCUDCBusVolt_Nidec "Rear MCU DC-Bus Voltage from Nidec";
CM_ SG_ 402 Rr_MCUReady4Pre_Nidec "Rear MCU Ready for Precharge from Nidec";
CM_ SG_ 402 Rr_ActvDmpDisabSta_Nidec "Rear MCU Low speed active damping disable status from Nidec";
CM_ SG_ 402 Rr_EDUDrtSta_Nidec "Rear EDU Torque Derating Status from Nidec";
CM_ SG_ 402 Rr_MCUDischrgSta_Nidec "Rear MCU Discharge Status from Nidec";
CM_ SG_ 402 Rr_MCUReady_Nidec "Rear MCU Ready from Nidec";
CM_ SG_ 402 Rr_TMSpd_Nidec "Rear TM speed from Nidec";
CM_ SG_ 402 Rr_EDURealTMTq_Nidec "Rear EDU Real Torque from TM from Nidec";
CM_ SG_ 402 Rr_EDUTqReqFbk_Nidec "Rear EDU Torque Request Feedback from Nidec";
CM_ SG_ 402 Rr_MCUEnaSta_Nidec "Rear MCU Enable Status from Nidec";
CM_ SG_ 402 Rr_EDUOpratingSta_Nidec "Rear EDU Torque/Speed Status from Nidec";
CM_ SG_ 402 Rr_EDURotateDirction_Nidec "Rear EDU Direction Status from Nidec";
CM_ SG_ 403 Rr_MCU2Chksum "Checksum of MCU_R2(AUTOSAR E2E profile 1)

Polynomial 0x1D (x^8+x^4+x^3+x^2+1) Both start value and XOR value are 0x00.";
CM_ SG_ 403 Rr_MCU2RolCnt "MCU_R2 4-bit rolling counter
It starts counting from 0, ends at 14 and returns to zero (0~14).";
CM_ SG_ 403 Rr_LLCflowReq "Rear  request LLC flow rate";
CM_ SG_ 403 Rr_CoolanttempReq "LLC coolant temp Request";
CM_ SG_ 403 Rr_Failcodehistory1 "Rear  Failcode history status";
CM_ SG_ 403 Rr_Failcodehistory2 "Rear Failcode history status";
CM_ SG_ 403 Rr_TMTempWarn "Rear TM Temperature Warning";
CM_ SG_ 403 Rr_MCUTempWarn "Rear MCU Temperature Warning";
CM_ SG_ 403 Rr_Failcode2 "Rear  Detail fail code";
CM_ SG_ 403 Rr_Failcode1 "Rear  Detail fail code";
CM_ SG_ 403 Rr_LLCTemp "Rear  LLC temperature";
CM_ SG_ 403 Rr_MCU3_HW_Ver "Rear MCU Hardware version";
CM_ SG_ 403 Rr_MCU3_SW_Ver "Rear MCU Software version";
CM_ SG_ 403 MCU_B_R_LLCTempWarn_Sta "Rear LLC temperature Warning";
CM_ SG_ 403 MCU_B_R_FailLv_Sta "Rear EDU Failure LVL Status";
CM_ SG_ 403 MCU_B_R_KL302TqCnt_Sta "Rear KL30 to Torque mode counter";
CM_ SG_ 412 Rr_MCU2Chksum_Nidec "Rear  MCU2 Frame checksum(SAEJ1850) 
x^8+x^4+x^3+x^2+1
It shall use 0xFF as the start value and XOR value.";
CM_ SG_ 412 Rr_MCU2RolCnt_Nidec "Rear MCU2 4bits Process counter";
CM_ SG_ 412 Rr_CoolanttempReq_Nidec "LLC coolant temp Request from Nidec";
CM_ SG_ 412 Rr_Failcodehistory1_Nidec "Rear  Failcode history status from Nidec";
CM_ SG_ 412 Rr_Failcodehistory2_Nidec "Rear Failcode history status from Nidec";
CM_ SG_ 412 Rr_TMTempWarn_Nidec "Rear TM Temperature Warning from Nidec";
CM_ SG_ 412 Rr_MCUTempWarn_Nidec "Rear MCU Temperature Warning from Nidec";
CM_ SG_ 412 Rr_Failcode2_Nidec "Rear  Detail fail code from Nidec";
CM_ SG_ 412 Rr_Failcode1_Nidec "Rear  Detail fail code from Nidec";
CM_ SG_ 412 Rr_EOP_SpdSet_Nidec "Rear  MCU request EOP Speed from Nidec";
CM_ SG_ 412 Rr_LLCTemp_Nidec "Rear  LLC temperature from Nidec";
CM_ SG_ 412 Rr_LLCflowReq_Nidec "Rear  request LLC flow rate from Nidec";
CM_ SG_ 412 MCU_R_ResetCnt_Sta "Rear MCU Reset counter";
CM_ SG_ 925 Rr_MCU3_HW_Ver_Nidec "Rear MCU Hardware version from Nidec";
CM_ SG_ 925 Rr_MCU3_SW_Ver_Nidec "Rear MCU Software version from Nidec";
CM_ SG_ 1283 NM_MCU_N_R_Node_ID "Source Node Identifier";
CM_ SG_ 1283 NM_MCU_N_R_Rpt_Msg_Req "Repeat Message Request";
CM_ SG_ 1283 NM_MCU_N_R_CSB "NM Coordinator Sleep Bit";
CM_ SG_ 1283 NM_MCU_N_R_Active_WU "Active Wakeup Bit";
CM_ SG_ 1283 NM_MCU_N_R_PNI "Partial Network Information Bit (PNI)";
CM_ SG_ 1283 NM_MCU_N_R_ERROR_State "Defined Error states of the CAN Controller";
CM_ SG_ 1539 DiagRespFromMCU_N_R "Diagnostic Response from MCU_R";
CM_ SG_ 385 Shifter_CRC8 "Checksum of Shifter1(AUTOSAR E2E profile 1)

Polynomial 0x1D (x^8+x^4+x^3+x^2+1) Both start value and XOR value are 0x00.";
CM_ SG_ 385 Shifter_RC "Shifter 4-bit rolling counter
It starts counting from 0, ends at 14 and returns to zero (0~14).";
CM_ SG_ 385 Shifter_Fail_sta "Shifter fail status";
CM_ SG_ 385 Shifter_Handle_Cmd "Shifter Control Unit handle Command(PRND)";
CM_ SG_ 1336 NM_Shifter_Node_ID "Source Node Identifier";
CM_ SG_ 1336 NM_Shifter_Rpt_Msg_Req "Repeat Message Request";
CM_ SG_ 1336 NM_Shifter_CSB "NM Coordinator Sleep Bit";
CM_ SG_ 1336 NM_Shifter_Active_WU "Active Wakeup Bit";
CM_ SG_ 1336 NM_Shifter_PNI "Partial Network Information Bit (PNI)";
CM_ SG_ 1336 NM_Shifter_ERROR_State "Defined Error states of the CAN Controller";
CM_ SG_ 1592 DiagRespFromShifter "Diagnostic Response from Shifter";
CM_ SG_ 1545 DiagRespFromMCU_B_R "Diagnostic Response from MCU_R";
CM_ SG_ 1673 DiagPhysReqToMCU_B_R "Diagnostic Physical Request to MCU_R";
CM_ SG_ 1674 DiagPhysReqToMCU_B_F "Diagnostic Physical Request to MCU_F";
CM_ SG_ 1546 DiagRespFromMCU_B_F "Diagnostic Response from MCU_F";
CM_ SG_ 1289 NM_MCU_B_R_Node_ID "Source Node Identifier";
CM_ SG_ 1289 NM_MCU_B_R_ERROR_State "Defined Error states of the CAN Controller";
CM_ SG_ 1289 NM_MCU_B_R_Active_WU "Active Wakeup Bit";
CM_ SG_ 1289 NM_MCU_B_R_CSB "NM Coordinator Sleep Bit";
CM_ SG_ 1289 NM_MCU_B_R_PNI "Partial Network Information Bit (PNI)";
CM_ SG_ 1289 NM_MCU_B_R_Rpt_Msg_Req "Repeat Message Request";
CM_ SG_ 1290 NM_MCU_B_F_Node_ID "Source Node Identifier";
CM_ SG_ 1290 NM_MCU_B_F_ERROR_State "Defined Error states of the CAN Controller";
CM_ SG_ 1290 NM_MCU_B_F_Active_WU "Active Wakeup Bit";
CM_ SG_ 1290 NM_MCU_B_F_CSB "NM Coordinator Sleep Bit";
CM_ SG_ 1290 NM_MCU_B_F_PNI "Partial Network Information Bit (PNI)";
CM_ SG_ 1290 NM_MCU_B_F_Rpt_Msg_Req "Repeat Message Request";
CM_ SG_ 368 CSW2_TurnSw_Sta "Turning Switch Status (Shifter and CSW gen2 CAN ECU)";
CM_ SG_ 368 CSW2_FWipSw_Sta "Front Wiper Switch Status (Shifter and CSW gen2 CAN ECU)";
CM_ SG_ 368 CSW2_RWipWasSw_Sta "Rear Wiper_Washer Switch Status (Shifter and CSW gen2 CAN ECU)";
CM_ SG_ 368 CSW2_FWasSw_Sta "Front Washer_mist Switch Status (Shifter and CSW gen2 CAN ECU)";
CM_ SG_ 368 CSW2_PassSW_Sta "Passing Switch Status (Shifter and CSW gen2 CAN ECU)";
CM_ SG_ 368 CSW2_DimSw_Sta "Dimmer Switch Status (Shifter and CSW gen2 CAN ECU)";
CM_ SG_ 2015 DiagFuncReqOBD "Diagnostic Functional Request from OBD Tester";
CM_ SG_ 564 CellVoltage160 "CellVoltage160";
CM_ SG_ 564 CellVoltage159 "CellVoltage159";
CM_ SG_ 564 CellVoltage158 "CellVoltage158";
CM_ SG_ 564 CellVoltage157 "CellVoltage157";
CM_ SG_ 564 CellVoltage156 "CellVoltage156";
CM_ SG_ 564 CellVoltage155 "CellVoltage155";
CM_ SG_ 564 CellVoltage154 "CellVoltage154";
CM_ SG_ 564 CellVoltage153 "CellVoltage153";
CM_ SG_ 564 CellVoltage152 "CellVoltage152";
CM_ SG_ 564 CellVoltage151 "CellVoltage151";
CM_ SG_ 564 CellVoltage150 "CellVoltage150";
CM_ SG_ 564 CellVoltage149 "CellVoltage149";
CM_ SG_ 564 CellVoltage148 "CellVoltage148";
CM_ SG_ 564 CellVoltage147 "CellVoltage147";
CM_ SG_ 564 CellVoltage146 "CellVoltage146";
CM_ SG_ 564 CellVoltage145 "CellVoltage145";
CM_ SG_ 564 CellVoltage144 "CellVoltage144";
CM_ SG_ 564 CellVoltage143 "CellVoltage143";
CM_ SG_ 564 CellVoltage142 "CellVoltage142";
CM_ SG_ 564 CellVoltage141 "CellVoltage141";
CM_ SG_ 564 CellVoltage140 "CellVoltage140";
CM_ SG_ 564 CellVoltage139 "CellVoltage139";
CM_ SG_ 564 CellVoltage138 "CellVoltage138";
CM_ SG_ 564 CellVoltage137 "CellVoltage137";
CM_ SG_ 564 CellVoltage136 "CellVoltage136";
CM_ SG_ 564 CellVoltage135 "CellVoltage135";
CM_ SG_ 564 CellVoltage134 "CellVoltage134";
CM_ SG_ 564 CellVoltage133 "CellVoltage133";
CM_ SG_ 564 CellVoltage132 "CellVoltage132";
CM_ SG_ 564 CellVoltage131 "CellVoltage131";
CM_ SG_ 564 CellVoltage130 "CellVoltage130";
CM_ SG_ 564 CellVoltage129 "CellVoltage129";
CM_ SG_ 565 CellVoltage192 "CellVoltage192";
CM_ SG_ 565 CellVoltage191 "CellVoltage191";
CM_ SG_ 565 CellVoltage190 "CellVoltage190";
CM_ SG_ 565 CellVoltage189 "CellVoltage189";
CM_ SG_ 565 CellVoltage188 "CellVoltage188";
CM_ SG_ 565 CellVoltage187 "CellVoltage187";
CM_ SG_ 565 CellVoltage186 "CellVoltage186";
CM_ SG_ 565 CellVoltage185 "CellVoltage185";
CM_ SG_ 565 CellVoltage184 "CellVoltage184";
CM_ SG_ 565 CellVoltage183 "CellVoltage183";
CM_ SG_ 565 CellVoltage182 "CellVoltage182";
CM_ SG_ 565 CellVoltage181 "CellVoltage181";
CM_ SG_ 565 CellVoltage180 "CellVoltage180";
CM_ SG_ 565 CellVoltage179 "CellVoltage179";
CM_ SG_ 565 CellVoltage178 "CellVoltage178";
CM_ SG_ 565 CellVoltage177 "CellVoltage177";
CM_ SG_ 565 CellVoltage176 "CellVoltage176";
CM_ SG_ 565 CellVoltage175 "CellVoltage175";
CM_ SG_ 565 CellVoltage174 "CellVoltage174";
CM_ SG_ 565 CellVoltage173 "CellVoltage173";
CM_ SG_ 565 CellVoltage172 "CellVoltage172";
CM_ SG_ 565 CellVoltage171 "CellVoltage171";
CM_ SG_ 565 CellVoltage170 "CellVoltage170";
CM_ SG_ 565 CellVoltage169 "CellVoltage169";
CM_ SG_ 565 CellVoltage168 "CellVoltage168";
CM_ SG_ 565 CellVoltage167 "CellVoltage167";
CM_ SG_ 565 CellVoltage166 "CellVoltage166";
CM_ SG_ 565 CellVoltage165 "CellVoltage165";
CM_ SG_ 565 CellVoltage164 "CellVoltage164";
CM_ SG_ 565 CellVoltage163 "CellVoltage163";
CM_ SG_ 565 CellVoltage162 "CellVoltage162";
CM_ SG_ 565 CellVoltage161 "CellVoltage161";
CM_ SG_ 566 CellVoltage216 "CellVoltage216";
CM_ SG_ 566 CellVoltage215 "CellVoltage215";
CM_ SG_ 566 CellVoltage214 "CellVoltage214";
CM_ SG_ 566 CellVoltage213 "CellVoltage213";
CM_ SG_ 566 CellVoltage212 "CellVoltage212";
CM_ SG_ 566 CellVoltage211 "CellVoltage211";
CM_ SG_ 566 CellVoltage210 "CellVoltage210";
CM_ SG_ 566 CellVoltage209 "CellVoltage209";
CM_ SG_ 566 CellVoltage208 "CellVoltage208";
CM_ SG_ 566 CellVoltage207 "CellVoltage207";
CM_ SG_ 566 CellVoltage206 "CellVoltage206";
CM_ SG_ 566 CellVoltage205 "CellVoltage205";
CM_ SG_ 566 CellVoltage204 "CellVoltage204";
CM_ SG_ 566 CellVoltage203 "CellVoltage203";
CM_ SG_ 566 CellVoltage202 "CellVoltage202";
CM_ SG_ 566 CellVoltage201 "CellVoltage201";
CM_ SG_ 566 CellVoltage200 "CellVoltage200";
CM_ SG_ 566 CellVoltage199 "CellVoltage199";
CM_ SG_ 566 CellVoltage198 "CellVoltage198";
CM_ SG_ 566 CellVoltage197 "CellVoltage197";
CM_ SG_ 566 CellVoltage196 "CellVoltage196";
CM_ SG_ 566 CellVoltage195 "CellVoltage195";
CM_ SG_ 566 CellVoltage194 "CellVoltage194";
CM_ SG_ 566 CellVoltage193 "CellVoltage193";
CM_ SG_ 409 MCU_FVT_R_TMSpd_Sta "Rear TM speed for FVT";
CM_ SG_ 409 MCU_FVT_R_EDUTqReq_Fbk "Rear EDU Torque Request Feedback for FVT";
CM_ SG_ 409 MCU_FVT_R_Failcode3_Sta "Rear MCU Detail fail code for FVT";
CM_ SG_ 409 MCU_FVT_R_MCUErr_Sta "Rear MCU Error Code for FVT";
CM_ SG_ 409 MCU_FVT_R_OilTemp_Sta "Rear Oil Temperature for FVT";
CM_ SG_ 409 MCU_FVT_R_MCUBAT_Sta "Rear MCU Bat Voltage for FVT";
CM_ SG_ 409 MCU_FVT_R_MCUSys_Sta "Rear MCU System Status for FVT";
CM_ SG_ 409 MCU_FVT_R_HeatingOP_Sta "Rear Heating Operating Feedback for FVT";
CM_ SG_ 409 MCU_FVT_R_BoostOP_Sta "Rear Boost Charge Operating Feedback for FVT";
CM_ SG_ 410 MCU_FVT_F_TMSpd_Sta "Front TM speed for FVT1";
CM_ SG_ 410 MCU_FVT_F_EDUTqReq_Fbk "Front EDU Torque Request Feedback for FVT";
CM_ SG_ 410 MCU_FVT_F_Failcode3_Sta "Front MCU Detail fail code for FVT";
CM_ SG_ 410 MCU_FVT_F_MCUErr_Sta "Front MCU Error Code for FVT";
CM_ SG_ 410 MCU_FVT_F_OilTemp_Sta "Front Oil Temperature for FVT";
CM_ SG_ 410 MCU_FVT_F_MCUBAT_Sta "Front MCU Bat Voltage for FVT";
CM_ SG_ 410 MCU_FVT_F_MCUSys_Sta "Front MCU System Status for FVT";
CM_ SG_ 410 MCU_FVT_F_HeatingOP_Sta "Front Heating Operating Feedback for FVT";
CM_ SG_ 410 MCU_FVT_F_BoostOP_Sta "Front Boost Charge Operating Feedback for FVT";
CM_ SG_ 1731 DiagPhysReqToEOP_FVT_R "Diagnostic Physical Request to EOP_FVT_R";
CM_ SG_ 1603 DiagRespFromEOP_FVT_R "Diagnostic Response from EOP_FVT_R";
CM_ SG_ 1732 DiagPhysReqToEOP_FVT_F "Diagnostic Physical Request to EOP_FVT_F";
CM_ SG_ 1604 DiagRespFromEOP_FVT_F "Diagnostic Response from EOP_FVT_F";
BA_DEF_ BO_ "GenMsgSendType" ENUM "Cycle","NoMsgSendType","IfActive","Event","CA","CE";
BA_DEF_ BO_ "GenMsgNrOfRepetition" INT 0 0;
BA_DEF_ BO_ "GenMsgILSupport" ENUM "No","Yes";
BA_DEF_ BO_ "GenMsgCycleTime" INT 0 0;
BA_DEF_ BO_ "DiagResponse" ENUM "No","Yes";
BA_DEF_ BO_ "DiagRequest" ENUM "No","Yes";
BA_DEF_ BO_ "NmMessage" ENUM "No","Yes";
BA_DEF_ BO_ "VFrameFormat" ENUM "StandardCAN","ExtendedCAN","reserved","reserved","reserved","reserved","reserved","reserved","reserved","reserved","reserved","reserved","reserved","reserved","StandardCAN_FD","ExtendedCAN_FD";
BA_DEF_ BO_ "DataID" STRING ;
BA_DEF_ BO_ "DoIPLogicalAddress" STRING ;
BA_DEF_ BO_ "CANFD_BRS" ENUM "0","1";
BA_DEF_ BO_ "GenMsgRequestable" INT 0 1;
BA_DEF_ SG_ "GenSigInvalidValue" HEX 0 0;
BA_DEF_ SG_ "GenSigStartValue" HEX 0 0;
BA_DEF_ SG_ "GenSigInactiveValue" HEX 0 0;
BA_DEF_ SG_ "GenSigRoutingTimeoutValue_String" STRING ;
BA_DEF_ SG_ "DataCenterDataType" STRING ;
BA_DEF_ SG_ "GenSigRoutingTimeoutValue" HEX 0 0;
BA_DEF_ SG_ "GenSigSendType" ENUM "Cycle","OnWrite","OnWriteWithRepetition","OnChange","OnChangeWithRepetition","IfActive","IfActiveWithRepetition","NoSigSendType","vector_leerstring";
BA_DEF_ SG_ "SigType" ENUM "Default","Range","RangeSigned","ASCII","Discrete","Control","ReferencePGN","DTC","StringDelimiter","StringLength","StringLengthControl","MessageCounter","MessageChecksum";
BA_DEF_ SG_ "GenSigILSupport" ENUM "No","Yes";
BA_DEF_DEF_ "GenMsgSendType" "Cycle";
BA_DEF_DEF_ "GenMsgNrOfRepetition" 0;
BA_DEF_DEF_ "GenMsgILSupport" "Yes";
BA_DEF_DEF_ "GenMsgCycleTime" 100;
BA_DEF_DEF_ "DiagResponse" "No";
BA_DEF_DEF_ "DiagRequest" "No";
BA_DEF_DEF_ "NmMessage" "No";
BA_DEF_DEF_ "VFrameFormat" "StandardCAN";
BA_DEF_DEF_ "DataID" "";
BA_DEF_DEF_ "DoIPLogicalAddress" "";
BA_DEF_DEF_ "CANFD_BRS" "1";
BA_DEF_DEF_ "GenMsgRequestable" 1;
BA_DEF_DEF_ "GenSigInvalidValue" 0;
BA_DEF_DEF_ "GenSigStartValue" 0;
BA_DEF_DEF_ "GenSigInactiveValue" 0;
BA_DEF_DEF_ "GenSigRoutingTimeoutValue_String" "";
BA_DEF_DEF_ "DataCenterDataType" "";
BA_DEF_DEF_ "GenSigRoutingTimeoutValue" 0;
BA_DEF_DEF_ "GenSigSendType" "Cycle";
BA_DEF_DEF_ "SigType" "Default";
BA_DEF_DEF_ "GenSigILSupport" "Yes";
BA_ "GenMsgCycleTime" BO_ 496 10;
BA_ "VFrameFormat" BO_ 496 14;
BA_ "GenMsgNrOfRepetition" BO_ 534 1;
BA_ "GenMsgCycleTime" BO_ 534 200;
BA_ "GenMsgSendType" BO_ 534 5;
BA_ "VFrameFormat" BO_ 534 14;
BA_ "GenMsgNrOfRepetition" BO_ 884 1;
BA_ "GenMsgSendType" BO_ 884 5;
BA_ "VFrameFormat" BO_ 884 14;
BA_ "GenMsgNrOfRepetition" BO_ 1080 1;
BA_ "GenMsgCycleTime" BO_ 1080 200;
BA_ "GenMsgSendType" BO_ 1080 5;
BA_ "VFrameFormat" BO_ 1080 14;
BA_ "GenMsgCycleTime" BO_ 1183 1000;
BA_ "VFrameFormat" BO_ 1183 14;
BA_ "GenMsgCycleTime" BO_ 1280 0;
BA_ "NmMessage" BO_ 1280 1;
BA_ "GenMsgSendType" BO_ 1280 3;
BA_ "GenMsgCycleTime" BO_ 1667 0;
BA_ "DiagRequest" BO_ 1667 1;
BA_ "GenMsgSendType" BO_ 1667 3;
BA_ "VFrameFormat" BO_ 1667 14;
BA_ "DoIPLogicalAddress" BO_ 1667 "0x0683";
BA_ "GenMsgCycleTime" BO_ 1672 0;
BA_ "DiagRequest" BO_ 1672 1;
BA_ "GenMsgSendType" BO_ 1672 3;
BA_ "VFrameFormat" BO_ 1672 14;
BA_ "DoIPLogicalAddress" BO_ 1672 "0x0688";
BA_ "GenMsgCycleTime" BO_ 1683 0;
BA_ "DiagRequest" BO_ 1683 1;
BA_ "GenMsgSendType" BO_ 1683 3;
BA_ "VFrameFormat" BO_ 1683 14;
BA_ "DoIPLogicalAddress" BO_ 1683 "0x0693";
BA_ "GenMsgCycleTime" BO_ 1688 0;
BA_ "DiagRequest" BO_ 1688 1;
BA_ "GenMsgSendType" BO_ 1688 3;
BA_ "VFrameFormat" BO_ 1688 14;
BA_ "DoIPLogicalAddress" BO_ 1688 "0x0698";
BA_ "GenMsgCycleTime" BO_ 1699 0;
BA_ "DiagRequest" BO_ 1699 1;
BA_ "GenMsgSendType" BO_ 1699 3;
BA_ "VFrameFormat" BO_ 1699 14;
BA_ "DoIPLogicalAddress" BO_ 1699 "0x06A3";
BA_ "GenMsgCycleTime" BO_ 1712 0;
BA_ "DiagRequest" BO_ 1712 1;
BA_ "GenMsgSendType" BO_ 1712 3;
BA_ "VFrameFormat" BO_ 1712 14;
BA_ "DoIPLogicalAddress" BO_ 1712 "0x06B0";
BA_ "GenMsgCycleTime" BO_ 1715 0;
BA_ "DiagRequest" BO_ 1715 1;
BA_ "GenMsgSendType" BO_ 1715 3;
BA_ "VFrameFormat" BO_ 1715 14;
BA_ "DoIPLogicalAddress" BO_ 1715 "0x06B3";
BA_ "GenMsgCycleTime" BO_ 1720 0;
BA_ "DiagRequest" BO_ 1720 1;
BA_ "GenMsgSendType" BO_ 1720 3;
BA_ "VFrameFormat" BO_ 1720 14;
BA_ "DoIPLogicalAddress" BO_ 1720 "0x06B8";
BA_ "GenMsgCycleTime" BO_ 2000 0;
BA_ "DiagRequest" BO_ 2000 1;
BA_ "GenMsgSendType" BO_ 2000 3;
BA_ "VFrameFormat" BO_ 2000 14;
BA_ "DoIPLogicalAddress" BO_ 2000 "0xEFFF";
BA_ "GenMsgCycleTime" BO_ 401 10;
BA_ "DataID" BO_ 401 "0x57F4";
BA_ "VFrameFormat" BO_ 401 14;
BA_ "GenMsgCycleTime" BO_ 404 10;
BA_ "DataID" BO_ 404 "0x5277";
BA_ "VFrameFormat" BO_ 404 14;
BA_ "DataID" BO_ 406 "0x95F9";
BA_ "VFrameFormat" BO_ 406 14;
BA_ "GenMsgCycleTime" BO_ 408 200;
BA_ "VFrameFormat" BO_ 408 14;
BA_ "GenMsgCycleTime" BO_ 921 1000;
BA_ "VFrameFormat" BO_ 921 14;
BA_ "GenMsgCycleTime" BO_ 1288 0;
BA_ "NmMessage" BO_ 1288 1;
BA_ "GenMsgSendType" BO_ 1288 3;
BA_ "GenMsgCycleTime" BO_ 1544 0;
BA_ "DiagResponse" BO_ 1544 1;
BA_ "GenMsgSendType" BO_ 1544 3;
BA_ "VFrameFormat" BO_ 1544 14;
BA_ "DoIPLogicalAddress" BO_ 1544 "0x0688";
BA_ "GenMsgCycleTime" BO_ 400 10;
BA_ "DataID" BO_ 400 "0x1274";
BA_ "VFrameFormat" BO_ 400 14;
BA_ "GenMsgCycleTime" BO_ 402 10;
BA_ "DataID" BO_ 402 "0x0278";
BA_ "VFrameFormat" BO_ 402 14;
BA_ "GenMsgCycleTime" BO_ 403 10;
BA_ "DataID" BO_ 403 "0x62BB";
BA_ "VFrameFormat" BO_ 403 14;
BA_ "GenMsgCycleTime" BO_ 412 200;
BA_ "VFrameFormat" BO_ 412 14;
BA_ "GenMsgCycleTime" BO_ 925 1000;
BA_ "VFrameFormat" BO_ 925 14;
BA_ "GenMsgCycleTime" BO_ 1283 0;
BA_ "NmMessage" BO_ 1283 1;
BA_ "GenMsgSendType" BO_ 1283 3;
BA_ "GenMsgCycleTime" BO_ 1539 0;
BA_ "DiagResponse" BO_ 1539 1;
BA_ "GenMsgSendType" BO_ 1539 3;
BA_ "VFrameFormat" BO_ 1539 14;
BA_ "DoIPLogicalAddress" BO_ 1539 "0x0683";
BA_ "GenMsgNrOfRepetition" BO_ 385 1;
BA_ "DataID" BO_ 385 "0xF99D";
BA_ "GenMsgSendType" BO_ 385 5;
BA_ "VFrameFormat" BO_ 385 14;
BA_ "GenMsgCycleTime" BO_ 1336 0;
BA_ "NmMessage" BO_ 1336 1;
BA_ "GenMsgSendType" BO_ 1336 3;
BA_ "GenMsgCycleTime" BO_ 1592 0;
BA_ "DiagResponse" BO_ 1592 1;
BA_ "GenMsgSendType" BO_ 1592 3;
BA_ "VFrameFormat" BO_ 1592 14;
BA_ "DoIPLogicalAddress" BO_ 1592 "0x06B8";
BA_ "GenMsgCycleTime" BO_ 1545 0;
BA_ "DiagResponse" BO_ 1545 1;
BA_ "GenMsgSendType" BO_ 1545 3;
BA_ "VFrameFormat" BO_ 1545 14;
BA_ "DoIPLogicalAddress" BO_ 1545 "0x0689";
BA_ "GenMsgCycleTime" BO_ 1673 0;
BA_ "DiagRequest" BO_ 1673 1;
BA_ "GenMsgSendType" BO_ 1673 3;
BA_ "VFrameFormat" BO_ 1673 14;
BA_ "DoIPLogicalAddress" BO_ 1673 "0x0689";
BA_ "GenMsgCycleTime" BO_ 1674 0;
BA_ "DiagRequest" BO_ 1674 1;
BA_ "GenMsgSendType" BO_ 1674 3;
BA_ "VFrameFormat" BO_ 1674 14;
BA_ "DoIPLogicalAddress" BO_ 1674 "0x068A";
BA_ "GenMsgCycleTime" BO_ 1546 0;
BA_ "DiagResponse" BO_ 1546 1;
BA_ "GenMsgSendType" BO_ 1546 3;
BA_ "VFrameFormat" BO_ 1546 14;
BA_ "DoIPLogicalAddress" BO_ 1546 "0x068A";
BA_ "GenMsgCycleTime" BO_ 1289 0;
BA_ "NmMessage" BO_ 1289 1;
BA_ "GenMsgSendType" BO_ 1289 3;
BA_ "GenMsgCycleTime" BO_ 1290 0;
BA_ "NmMessage" BO_ 1290 1;
BA_ "GenMsgSendType" BO_ 1290 3;
BA_ "GenMsgNrOfRepetition" BO_ 368 1;
BA_ "GenMsgSendType" BO_ 368 5;
BA_ "VFrameFormat" BO_ 368 14;
BA_ "GenMsgCycleTime" BO_ 2015 0;
BA_ "DiagRequest" BO_ 2015 1;
BA_ "GenMsgSendType" BO_ 2015 3;
BA_ "VFrameFormat" BO_ 2015 14;
BA_ "DoIPLogicalAddress" BO_ 2015 "0xE000 ";
BA_ "VFrameFormat" BO_ 564 14;
BA_ "VFrameFormat" BO_ 565 14;
BA_ "VFrameFormat" BO_ 566 14;
BA_ "GenMsgCycleTime" BO_ 409 10;
BA_ "VFrameFormat" BO_ 409 14;
BA_ "GenMsgCycleTime" BO_ 410 10;
BA_ "VFrameFormat" BO_ 410 14;
BA_ "GenMsgCycleTime" BO_ 1731 0;
BA_ "DiagRequest" BO_ 1731 1;
BA_ "GenMsgSendType" BO_ 1731 3;
BA_ "VFrameFormat" BO_ 1731 14;
BA_ "DoIPLogicalAddress" BO_ 1731 "0x06C3";
BA_ "GenMsgCycleTime" BO_ 1603 0;
BA_ "DiagResponse" BO_ 1603 1;
BA_ "GenMsgSendType" BO_ 1603 3;
BA_ "VFrameFormat" BO_ 1603 14;
BA_ "DoIPLogicalAddress" BO_ 1603 "0x06C3";
BA_ "GenMsgCycleTime" BO_ 1732 0;
BA_ "DiagRequest" BO_ 1732 1;
BA_ "GenMsgSendType" BO_ 1732 3;
BA_ "VFrameFormat" BO_ 1732 14;
BA_ "DoIPLogicalAddress" BO_ 1732 "0x06C4";
BA_ "GenMsgCycleTime" BO_ 1604 0;
BA_ "DiagResponse" BO_ 1604 1;
BA_ "GenMsgSendType" BO_ 1604 3;
BA_ "VFrameFormat" BO_ 1604 14;
BA_ "DoIPLogicalAddress" BO_ 1604 "0x06C4";
BA_ "DataCenterDataType" SG_ 496 LVBattVoltSta "Varchar(10)";
BA_ "GenSigInvalidValue" SG_ 496 VCUBrkSWSta 2;
BA_ "GenSigRoutingTimeoutValue_String" SG_ 496 VCUBrkSWSta "0x2";
BA_ "GenSigRoutingTimeoutValue" SG_ 496 VCUBrkSWSta 2;
BA_ "DataCenterDataType" SG_ 496 LVSilentChrgReq "varchar(20)";
BA_ "GenSigInvalidValue" SG_ 496 LVSilentChrgSta 3;
BA_ "GenSigRoutingTimeoutValue_String" SG_ 496 LVSilentChrgSta "0x3";
BA_ "GenSigRoutingTimeoutValue" SG_ 496 LVSilentChrgSta 3;
BA_ "DataCenterDataType" SG_ 496 LVSilentChrgSta "varchar(15)";
BA_ "DataCenterDataType" SG_ 496 FDADC12VDetAvg "Decimal";
BA_ "GenSigStartValue" SG_ 496 FDC_VMC_ActStESCYaw_Sta 30000;
BA_ "GenSigInactiveValue" SG_ 496 FDC_VMC_ActStESCYaw_Sta 30000;
BA_ "GenSigStartValue" SG_ 496 FDC_VMC_LongAcc_Sta 20000;
BA_ "GenSigInactiveValue" SG_ 496 FDC_VMC_LongAcc_Sta 20000;
BA_ "GenSigStartValue" SG_ 496 FDC_VCU_VehActSpd_Sta 30000;
BA_ "GenSigInactiveValue" SG_ 496 FDC_VCU_VehActSpd_Sta 30000;
BA_ "GenSigStartValue" SG_ 496 FDC_VCU_ActMaxSlideRate_Sta 15000;
BA_ "GenSigInactiveValue" SG_ 496 FDC_VCU_ActMaxSlideRate_Sta 15000;
BA_ "GenSigStartValue" SG_ 496 FDC_VCU_SlideRegenLimTq_Sta 10600;
BA_ "GenSigInactiveValue" SG_ 496 FDC_VCU_SlideRegenLimTq_Sta 10600;
BA_ "GenSigInvalidValue" SG_ 496 FDC_VCU_VehMalfunLevel_Sta 5;
BA_ "GenSigRoutingTimeoutValue_String" SG_ 496 FDC_VCU_VehMalfunLevel_Sta "0x5";
BA_ "GenSigRoutingTimeoutValue" SG_ 496 FDC_VCU_VehMalfunLevel_Sta 5;
BA_ "GenSigInvalidValue" SG_ 496 FDC_VCU_AllowMovThd_OTA_Sta 2;
BA_ "GenSigRoutingTimeoutValue_String" SG_ 496 FDC_VCU_AllowMovThd_OTA_Sta "0x2";
BA_ "GenSigRoutingTimeoutValue" SG_ 496 FDC_VCU_AllowMovThd_OTA_Sta 2;
BA_ "GenSigInvalidValue" SG_ 496 FDC_VCU_EAPS2Raw_Sta 255;
BA_ "GenSigRoutingTimeoutValue_String" SG_ 496 FDC_VCU_EAPS2Raw_Sta "0xFF";
BA_ "GenSigInactiveValue" SG_ 496 FDC_VCU_EAPS2Raw_Sta 255;
BA_ "GenSigRoutingTimeoutValue" SG_ 496 FDC_VCU_EAPS2Raw_Sta 255;
BA_ "GenSigInvalidValue" SG_ 496 FDC_VCU_EAPS1Raw_Sta 255;
BA_ "GenSigRoutingTimeoutValue_String" SG_ 496 FDC_VCU_EAPS1Raw_Sta "0xFF";
BA_ "GenSigInactiveValue" SG_ 496 FDC_VCU_EAPS1Raw_Sta 255;
BA_ "GenSigRoutingTimeoutValue" SG_ 496 FDC_VCU_EAPS1Raw_Sta 255;
BA_ "GenSigInvalidValue" SG_ 496 FDC_VCU_EAPS2Min_Sta 255;
BA_ "GenSigRoutingTimeoutValue_String" SG_ 496 FDC_VCU_EAPS2Min_Sta "0xFF";
BA_ "GenSigInactiveValue" SG_ 496 FDC_VCU_EAPS2Min_Sta 255;
BA_ "GenSigRoutingTimeoutValue" SG_ 496 FDC_VCU_EAPS2Min_Sta 255;
BA_ "GenSigInvalidValue" SG_ 496 FDC_VCU_EAPS1Min_Sta 255;
BA_ "GenSigRoutingTimeoutValue_String" SG_ 496 FDC_VCU_EAPS1Min_Sta "0xFF";
BA_ "GenSigInactiveValue" SG_ 496 FDC_VCU_EAPS1Min_Sta 255;
BA_ "GenSigRoutingTimeoutValue" SG_ 496 FDC_VCU_EAPS1Min_Sta 255;
BA_ "GenSigInvalidValue" SG_ 496 FDC_VCU_CANBrkSW2Sta_Sta 2;
BA_ "GenSigRoutingTimeoutValue_String" SG_ 496 FDC_VCU_CANBrkSW2Sta_Sta "0x2";
BA_ "GenSigRoutingTimeoutValue" SG_ 496 FDC_VCU_CANBrkSW2Sta_Sta 2;
BA_ "GenSigInvalidValue" SG_ 496 FDC_VCU_BrkPedalPosSta_Sta 2;
BA_ "GenSigRoutingTimeoutValue_String" SG_ 496 FDC_VCU_BrkPedalPosSta_Sta "0x2";
BA_ "GenSigRoutingTimeoutValue" SG_ 496 FDC_VCU_BrkPedalPosSta_Sta 2;
BA_ "GenSigRoutingTimeoutValue_String" SG_ 496 FDC_VCU_LowIdleAccPedal_Sta "0x0";
BA_ "GenSigRoutingTimeoutValue_String" SG_ 496 FDC_VCU_LVStaDropQukCnt_Sta "0x0";
BA_ "DataCenterDataType" SG_ 496 FDC_VCU_LVStaDropQukCnt_Sta "Decimal";
BA_ "GenSigRoutingTimeoutValue_String" SG_ 496 FDC_VCU_LVChrgFreqCnt_Sta "0x0";
BA_ "DataCenterDataType" SG_ 496 FDC_VCU_LVChrgFreqCnt_Sta "Decimal";
BA_ "GenSigInvalidValue" SG_ 496 FDC_VCU_FrRateLimitInc_Sta 65535;
BA_ "GenSigRoutingTimeoutValue_String" SG_ 496 FDC_VCU_FrRateLimitInc_Sta "0xFFFF";
BA_ "GenSigRoutingTimeoutValue" SG_ 496 FDC_VCU_FrRateLimitInc_Sta 65535;
BA_ "GenSigInvalidValue" SG_ 496 FDC_VCU_RrRateLimitInc_Sta 65535;
BA_ "GenSigRoutingTimeoutValue_String" SG_ 496 FDC_VCU_RrRateLimitInc_Sta "0xFFFF";
BA_ "GenSigRoutingTimeoutValue" SG_ 496 FDC_VCU_RrRateLimitInc_Sta 65535;
BA_ "GenSigStartValue" SG_ 496 FDC_VCU_FrRateLimitDec_Sta 65535;
BA_ "GenSigRoutingTimeoutValue_String" SG_ 496 FDC_VCU_FrRateLimitDec_Sta "0x0";
BA_ "GenSigStartValue" SG_ 496 FDC_VCU_RrRateLimitDec_Sta 65535;
BA_ "GenSigRoutingTimeoutValue_String" SG_ 496 FDC_VCU_RrRateLimitDec_Sta "0x0";
BA_ "GenSigInvalidValue" SG_ 496 FDC_VCU_FrFirstOrderInpTs 255;
BA_ "GenSigRoutingTimeoutValue_String" SG_ 496 FDC_VCU_FrFirstOrderInpTs "0xFF";
BA_ "GenSigRoutingTimeoutValue" SG_ 496 FDC_VCU_FrFirstOrderInpTs 255;
BA_ "GenSigInvalidValue" SG_ 496 FDC_VCU_RrFirstOrderInpTs 255;
BA_ "GenSigRoutingTimeoutValue_String" SG_ 496 FDC_VCU_RrFirstOrderInpTs "0xFF";
BA_ "GenSigRoutingTimeoutValue" SG_ 496 FDC_VCU_RrFirstOrderInpTs 255;
BA_ "GenSigRoutingTimeoutValue_String" SG_ 496 FDC_VCU_BOSEnable_Sta "0x0";
BA_ "GenSigSendType" SG_ 534 BCM_Buzzer_Req 3;
BA_ "GenSigSendType" SG_ 534 TailgateRemote 3;
BA_ "GenSigSendType" SG_ 534 RoomLampL 3;
BA_ "GenSigSendType" SG_ 534 RoomLampH 3;
BA_ "GenSigSendType" SG_ 534 DimmerEN 3;
BA_ "GenSigSendType" SG_ 534 BCM_DoorLock_Sta 3;
BA_ "DataCenterDataType" SG_ 534 BCM_DoorLock_Sta "Varchar(7)";
BA_ "GenSigSendType" SG_ 534 HornCtrl 3;
BA_ "GenSigInvalidValue" SG_ 534 Dimmer 127;
BA_ "GenSigRoutingTimeoutValue_String" SG_ 534 Dimmer "0x7F";
BA_ "GenSigRoutingTimeoutValue" SG_ 534 Dimmer 127;
BA_ "GenSigSendType" SG_ 534 Dimmer 3;
BA_ "GenSigSendType" SG_ 534 LockSetting 3;
BA_ "GenSigSendType" SG_ 534 LTurnLP 3;
BA_ "GenSigSendType" SG_ 534 RTurnLP 3;
BA_ "GenSigSendType" SG_ 534 AntitheftSta 3;
BA_ "DataCenterDataType" SG_ 534 AntitheftSta "Varchar(30)";
BA_ "GenSigSendType" SG_ 534 AntiTheftSeatFold 3;
BA_ "GenSigSendType" SG_ 534 CrashDetd 3;
BA_ "DataCenterDataType" SG_ 534 CrashDetd "Varchar(20)";
BA_ "GenSigSendType" SG_ 534 L_APM_WdwEnable 3;
BA_ "GenSigSendType" SG_ 534 RDRL 3;
BA_ "GenSigSendType" SG_ 534 ReverseLamp 3;
BA_ "GenSigSendType" SG_ 534 BrakeLamp 3;
BA_ "GenSigSendType" SG_ 534 LBSD 3;
BA_ "GenSigSendType" SG_ 534 RBSD 3;
BA_ "GenSigSendType" SG_ 534 Fr_FogLamp 3;
BA_ "GenSigSendType" SG_ 534 Rr_FogLamp 3;
BA_ "GenSigSendType" SG_ 534 HazardSW 3;
BA_ "GenSigSendType" SG_ 534 Rr_Wiper 3;
BA_ "GenSigSendType" SG_ 534 WiperFixMode 3;
BA_ "GenSigSendType" SG_ 534 WasherCtrl 3;
BA_ "GenSigSendType" SG_ 534 L_Beam 3;
BA_ "GenSigSendType" SG_ 534 H_Beam 3;
BA_ "GenSigSendType" SG_ 534 PosLamp 3;
BA_ "GenSigSendType" SG_ 534 LDRL 3;
BA_ "GenSigSendType" SG_ 534 MirrorDefog 3;
BA_ "GenSigSendType" SG_ 534 Rr_Defog 3;
BA_ "GenSigSendType" SG_ 534 TrunkRel 3;
BA_ "GenSigSendType" SG_ 534 TailgateHDSW 3;
BA_ "GenSigSendType" SG_ 534 MirrorCtrl 3;
BA_ "GenSigSendType" SG_ 534 Fr_Wiper_H 3;
BA_ "GenSigSendType" SG_ 534 Fr_Wiper_L 3;
BA_ "GenSigSendType" SG_ 534 CTDCtrl 3;
BA_ "GenSigSendType" SG_ 534 Fr_ChargingDoorCtrl 3;
BA_ "GenSigSendType" SG_ 534 Rr_ChargingDoorCtrl 3;
BA_ "GenSigSendType" SG_ 534 CTDLockSW 3;
BA_ "GenSigSendType" SG_ 534 CTDUnlockSW 3;
BA_ "GenSigSendType" SG_ 534 DrDoorSW 3;
BA_ "GenSigSendType" SG_ 534 PsDoorSW 3;
BA_ "GenSigSendType" SG_ 534 RLDoorSW 3;
BA_ "GenSigSendType" SG_ 534 RRDoorSW 3;
BA_ "GenSigSendType" SG_ 534 AllDoorSW 3;
BA_ "GenSigSendType" SG_ 534 DoorLockIND 3;
BA_ "GenSigSendType" SG_ 534 HoodSW 3;
BA_ "GenSigSendType" SG_ 534 Tailgate_SW 3;
BA_ "GenSigSendType" SG_ 884 Req_V2LSwOn 3;
BA_ "GenSigSendType" SG_ 884 Req_V2L_IVI_Popup 3;
BA_ "GenSigSendType" SG_ 884 FDC_V2L_OBCIntrV2L_Cmd 3;
BA_ "GenSigSendType" SG_ 884 FDC_V2L_OBCExtrV2L_Cmd 3;
BA_ "GenSigSendType" SG_ 884 Req_OBCV2LEna 3;
BA_ "GenSigInvalidValue" SG_ 1080 OTA_Progress_Rate 102;
BA_ "GenSigSendType" SG_ 1080 OTA_Progress_Rate 3;
BA_ "DataCenterDataType" SG_ 1080 OTA_Progress_Rate "array";
BA_ "GenSigSendType" SG_ 1080 OTA_DL_Available 3;
BA_ "GenSigSendType" SG_ 1080 OTA_Mode 3;
BA_ "GenSigSendType" SG_ 1080 OTA_Network_Type 3;
BA_ "GenSigSendType" SG_ 1080 OTA_MDA_Status 3;
BA_ "DataCenterDataType" SG_ 1080 OTA_MDA_Status "array";
BA_ "GenSigInvalidValue" SG_ 1080 OTA_Updating_ECU_8bit 30;
BA_ "GenSigSendType" SG_ 1080 OTA_Updating_ECU_8bit 3;
BA_ "DataCenterDataType" SG_ 1080 OTA_Updating_ECU_8bit "array";
BA_ "GenSigSendType" SG_ 1080 OTA_DL_Speed 3;
BA_ "GenSigSendType" SG_ 1080 OTA_InVehicle_FW 3;
BA_ "GenSigSendType" SG_ 1080 OTA_TBOXResetReq 3;
BA_ "GenSigSendType" SG_ 1080 OTA_Lock_Req 3;
BA_ "GenSigInvalidValue" SG_ 1080 OTA_Remained_Time 1082;
BA_ "GenSigSendType" SG_ 1080 OTA_Update_Available 3;
BA_ "GenSigRoutingTimeoutValue_String" SG_ 1080 OTA_Emergency_Sta "0x0";
BA_ "GenSigSendType" SG_ 1080 OTA_Emergency_Sta 3;
BA_ "GenSigSendType" SG_ 1280 NM_FUSION_Node_ID 7;
BA_ "GenSigSendType" SG_ 1280 NM_FUSION_Rpt_Msg_Req 7;
BA_ "GenSigSendType" SG_ 1280 NM_FUSION_CSB 7;
BA_ "GenSigSendType" SG_ 1280 NM_FUSION_Active_WU 7;
BA_ "GenSigSendType" SG_ 1280 NM_FUSION_PNI 7;
BA_ "GenSigSendType" SG_ 1280 NM_FUSION_ERROR_State 7;
BA_ "GenSigSendType" SG_ 1667 DiagPhysReqToMCU_N_R 3;
BA_ "GenSigSendType" SG_ 1672 DiagPhysReqToMCU_N_F 3;
BA_ "GenSigSendType" SG_ 1683 DiagPhysReqToEOP_R 3;
BA_ "GenSigSendType" SG_ 1688 DiagPhysReqToEOP_F 3;
BA_ "GenSigSendType" SG_ 1699 DiagPhysReqToEBM 3;
BA_ "GenSigSendType" SG_ 1712 DiagPhysReqToBMS 3;
BA_ "GenSigSendType" SG_ 1715 DiagPhysReqToCCU 3;
BA_ "GenSigSendType" SG_ 1720 DiagPhysReqToShifter 3;
BA_ "GenSigSendType" SG_ 2000 DiagFuncReqFT 3;
BA_ "GenSigStartValue" SG_ 401 MCUWarn_F 7;
BA_ "GenSigInvalidValue" SG_ 401 Fr_MCUBAT 255;
BA_ "GenSigInvalidValue" SG_ 401 Fr_RegenAvailTq 4095;
BA_ "GenSigInvalidValue" SG_ 401 Fr_MotorAvailTq 4095;
BA_ "GenSigRoutingTimeoutValue_String" SG_ 401 Fr_MotorAvailTq "0xFFF";
BA_ "GenSigInactiveValue" SG_ 401 Fr_MotorAvailTq 4095;
BA_ "GenSigRoutingTimeoutValue" SG_ 401 Fr_MotorAvailTq 4095;
BA_ "GenSigInvalidValue" SG_ 401 Fr_TMiq 32767;
BA_ "GenSigInvalidValue" SG_ 401 Fr_TMid 32767;
BA_ "GenSigInvalidValue" SG_ 401 Fr_TMTemp 511;
BA_ "GenSigRoutingTimeoutValue_String" SG_ 401 Fr_TMTemp "0x1FF";
BA_ "GenSigInactiveValue" SG_ 401 Fr_TMTemp 511;
BA_ "GenSigRoutingTimeoutValue" SG_ 401 Fr_TMTemp 511;
BA_ "GenSigInvalidValue" SG_ 401 Fr_MCUTemp 511;
BA_ "GenSigRoutingTimeoutValue_String" SG_ 401 Fr_MCUTemp "0x1FF";
BA_ "GenSigInactiveValue" SG_ 401 Fr_MCUTemp 511;
BA_ "GenSigRoutingTimeoutValue" SG_ 401 Fr_MCUTemp 511;
BA_ "GenSigInvalidValue" SG_ 401 Fr_MCUDCBusCurr 32767;
BA_ "DataCenterDataType" SG_ 401 Fr_MCUDCBusCurr "Varchar(10)";
BA_ "GenSigInvalidValue" SG_ 401 Fr_MCUDCBusVolt 65535;
BA_ "DataCenterDataType" SG_ 401 Fr_MCUDCBusVolt "Varchar(10)";
BA_ "GenSigInvalidValue" SG_ 401 Fr_TMSpd 65535;
BA_ "GenSigStartValue" SG_ 401 Fr_TMSpd 18000;
BA_ "GenSigRoutingTimeoutValue_String" SG_ 401 Fr_TMSpd "0xFFFF";
BA_ "GenSigInactiveValue" SG_ 401 Fr_TMSpd 65535;
BA_ "GenSigRoutingTimeoutValue" SG_ 401 Fr_TMSpd 65535;
BA_ "GenSigInvalidValue" SG_ 401 Fr_EDURealTMTq 65535;
BA_ "GenSigStartValue" SG_ 401 Fr_EDURealTMTq 10220;
BA_ "GenSigRoutingTimeoutValue_String" SG_ 401 Fr_EDURealTMTq "0xFFFF";
BA_ "GenSigInactiveValue" SG_ 401 Fr_EDURealTMTq 65535;
BA_ "GenSigRoutingTimeoutValue" SG_ 401 Fr_EDURealTMTq 65535;
BA_ "GenSigInvalidValue" SG_ 401 Fr_EDUTqReqFbk 4095;
BA_ "GenSigStartValue" SG_ 401 Fr_EDUTqReqFbk 1022;
BA_ "GenSigInvalidValue" SG_ 401 MCU_B_F_IGBTDdeTemp_Sta 511;
BA_ "GenSigStartValue" SG_ 401 MCU_B_F_IGBTDdeTemp_Sta 40;
BA_ "GenSigRoutingTimeoutValue_String" SG_ 401 MCU_B_F_IGBTDdeTemp_Sta "0x1FF";
BA_ "GenSigInactiveValue" SG_ 401 MCU_B_F_IGBTDdeTemp_Sta 40;
BA_ "GenSigRoutingTimeoutValue" SG_ 401 MCU_B_F_IGBTDdeTemp_Sta 511;
BA_ "GenSigInvalidValue" SG_ 401 MCU_B_F_RealPwrKw_Sta 65535;
BA_ "GenSigStartValue" SG_ 401 MCU_B_F_RealPwrKw_Sta 5300;
BA_ "GenSigRoutingTimeoutValue_String" SG_ 401 MCU_B_F_RealPwrKw_Sta "0xFFFF";
BA_ "GenSigInactiveValue" SG_ 401 MCU_B_F_RealPwrKw_Sta 5300;
BA_ "GenSigRoutingTimeoutValue" SG_ 401 MCU_B_F_RealPwrKw_Sta 65535;
BA_ "GenSigInvalidValue" SG_ 404 Fr_LLCflowReq 63;
BA_ "GenSigInvalidValue" SG_ 404 Fr_CoolanttempReq 511;
BA_ "GenSigStartValue" SG_ 404 Fr_CoolanttempReq 40;
BA_ "GenSigInvalidValue" SG_ 404 Fr_TMTempWarn 3;
BA_ "GenSigStartValue" SG_ 404 Fr_TMTempWarn 3;
BA_ "GenSigRoutingTimeoutValue_String" SG_ 404 Fr_TMTempWarn "0x3";
BA_ "GenSigInactiveValue" SG_ 404 Fr_TMTempWarn 3;
BA_ "GenSigRoutingTimeoutValue" SG_ 404 Fr_TMTempWarn 3;
BA_ "GenSigInvalidValue" SG_ 404 Fr_MCUTempWarn 3;
BA_ "GenSigStartValue" SG_ 404 Fr_MCUTempWarn 3;
BA_ "GenSigRoutingTimeoutValue_String" SG_ 404 Fr_MCUTempWarn "0x3";
BA_ "GenSigInactiveValue" SG_ 404 Fr_MCUTempWarn 3;
BA_ "GenSigRoutingTimeoutValue" SG_ 404 Fr_MCUTempWarn 3;
BA_ "GenSigInvalidValue" SG_ 404 Fr_LLCTemp 511;
BA_ "GenSigInvalidValue" SG_ 404 MCU_B_F_LLCTempWarn_Sta 3;
BA_ "GenSigRoutingTimeoutValue_String" SG_ 404 MCU_B_F_LLCTempWarn_Sta "0x3";
BA_ "GenSigInactiveValue" SG_ 404 MCU_B_F_LLCTempWarn_Sta 3;
BA_ "GenSigRoutingTimeoutValue" SG_ 404 MCU_B_F_LLCTempWarn_Sta 3;
BA_ "GenSigInvalidValue" SG_ 404 MCU_B_F_FailLv_Sta 7;
BA_ "GenSigRoutingTimeoutValue_String" SG_ 404 MCU_B_F_FailLv_Sta "0x7";
BA_ "GenSigRoutingTimeoutValue" SG_ 404 MCU_B_F_FailLv_Sta 7;
BA_ "GenSigInvalidValue" SG_ 404 MCU_B_F_KL302TqCnt_Sta 255;
BA_ "GenSigRoutingTimeoutValue_String" SG_ 404 MCU_B_F_KL302TqCnt_Sta "0xFF";
BA_ "GenSigRoutingTimeoutValue" SG_ 404 MCU_B_F_KL302TqCnt_Sta 255;
BA_ "GenSigStartValue" SG_ 406 MCUWarn_F_Nidec 7;
BA_ "GenSigInvalidValue" SG_ 406 Fr_MCUBAT_Nidec 255;
BA_ "GenSigInvalidValue" SG_ 406 Fr_RegenAvailTq_Nidec 4095;
BA_ "GenSigInvalidValue" SG_ 406 Fr_MotorAvailTq_Nidec 4095;
BA_ "GenSigRoutingTimeoutValue_String" SG_ 406 Fr_MotorAvailTq_Nidec "0xFFF";
BA_ "GenSigInactiveValue" SG_ 406 Fr_MotorAvailTq_Nidec 4095;
BA_ "GenSigRoutingTimeoutValue" SG_ 406 Fr_MotorAvailTq_Nidec 4095;
BA_ "GenSigInvalidValue" SG_ 406 Fr_TMiq_Nidec 32767;
BA_ "GenSigInvalidValue" SG_ 406 Fr_TMid_Nidec 32767;
BA_ "GenSigInvalidValue" SG_ 406 Fr_TMTemp_Nidec 511;
BA_ "GenSigRoutingTimeoutValue_String" SG_ 406 Fr_TMTemp_Nidec "0x1FF";
BA_ "GenSigInactiveValue" SG_ 406 Fr_TMTemp_Nidec 511;
BA_ "GenSigRoutingTimeoutValue" SG_ 406 Fr_TMTemp_Nidec 511;
BA_ "GenSigInvalidValue" SG_ 406 Fr_MCUTemp_Nidec 511;
BA_ "GenSigRoutingTimeoutValue_String" SG_ 406 Fr_MCUTemp_Nidec "0x1FF";
BA_ "GenSigInactiveValue" SG_ 406 Fr_MCUTemp_Nidec 511;
BA_ "GenSigRoutingTimeoutValue" SG_ 406 Fr_MCUTemp_Nidec 511;
BA_ "GenSigInvalidValue" SG_ 406 Fr_MCUDCBusCurr_Nidec 32767;
BA_ "GenSigInvalidValue" SG_ 406 Fr_MCUDCBusVolt_Nidec 65535;
BA_ "GenSigInvalidValue" SG_ 406 Fr_TMSpd_Nidec 65535;
BA_ "GenSigStartValue" SG_ 406 Fr_TMSpd_Nidec 17000;
BA_ "GenSigRoutingTimeoutValue_String" SG_ 406 Fr_TMSpd_Nidec "0xFFFF";
BA_ "GenSigInactiveValue" SG_ 406 Fr_TMSpd_Nidec 65535;
BA_ "GenSigRoutingTimeoutValue" SG_ 406 Fr_TMSpd_Nidec 65535;
BA_ "GenSigInvalidValue" SG_ 406 Fr_EDURealTMTq_Nidec 4095;
BA_ "GenSigRoutingTimeoutValue_String" SG_ 406 Fr_EDURealTMTq_Nidec "0xFFF";
BA_ "GenSigInactiveValue" SG_ 406 Fr_EDURealTMTq_Nidec 4095;
BA_ "GenSigRoutingTimeoutValue" SG_ 406 Fr_EDURealTMTq_Nidec 4095;
BA_ "GenSigInvalidValue" SG_ 406 Fr_EDUTqReqFbk_Nidec 4095;
BA_ "GenSigStartValue" SG_ 406 Fr_EDUTqReqFbk_Nidec 1022;
BA_ "GenSigInvalidValue" SG_ 408 Fr_CoolanttempReq_Nidec 511;
BA_ "GenSigStartValue" SG_ 408 Fr_CoolanttempReq_Nidec 40;
BA_ "GenSigInvalidValue" SG_ 408 Fr_TMTempWarn_Nidec 3;
BA_ "GenSigStartValue" SG_ 408 Fr_TMTempWarn_Nidec 3;
BA_ "GenSigRoutingTimeoutValue_String" SG_ 408 Fr_TMTempWarn_Nidec "0x3";
BA_ "GenSigInactiveValue" SG_ 408 Fr_TMTempWarn_Nidec 3;
BA_ "GenSigRoutingTimeoutValue" SG_ 408 Fr_TMTempWarn_Nidec 3;
BA_ "GenSigInvalidValue" SG_ 408 Fr_MCUTempWarn_Nidec 3;
BA_ "GenSigStartValue" SG_ 408 Fr_MCUTempWarn_Nidec 3;
BA_ "GenSigRoutingTimeoutValue_String" SG_ 408 Fr_MCUTempWarn_Nidec "0x3";
BA_ "GenSigInactiveValue" SG_ 408 Fr_MCUTempWarn_Nidec 3;
BA_ "GenSigRoutingTimeoutValue" SG_ 408 Fr_MCUTempWarn_Nidec 3;
BA_ "GenSigInvalidValue" SG_ 408 Fr_EOP_SpdSet_Nidec 4095;
BA_ "GenSigInvalidValue" SG_ 408 Fr_LLCTemp_Nidec 511;
BA_ "GenSigInvalidValue" SG_ 408 Fr_LLCflowReq_Nidec 63;
BA_ "GenSigSendType" SG_ 1288 NM_MCU_N_F_Node_ID 7;
BA_ "GenSigSendType" SG_ 1288 NM_MCU_N_F_Rpt_Msg_Req 7;
BA_ "GenSigSendType" SG_ 1288 NM_MCU_N_F_CSB 7;
BA_ "GenSigSendType" SG_ 1288 NM_MCU_N_F_Active_WU 7;
BA_ "GenSigSendType" SG_ 1288 NM_MCU_N_F_PNI 7;
BA_ "GenSigSendType" SG_ 1288 NM_MCU_N_F_ERROR_State 7;
BA_ "GenSigSendType" SG_ 1544 DiagRespFromMCU_N_F 3;
BA_ "GenSigStartValue" SG_ 400 MCUWarn_R 7;
BA_ "GenSigInvalidValue" SG_ 400 Rr_MCUBAT 255;
BA_ "GenSigInvalidValue" SG_ 400 Rr_RegenAvailTq 4095;
BA_ "GenSigInvalidValue" SG_ 400 Rr_MotorAvailTq 4095;
BA_ "GenSigRoutingTimeoutValue_String" SG_ 400 Rr_MotorAvailTq "0xFFF";
BA_ "GenSigInactiveValue" SG_ 400 Rr_MotorAvailTq 4095;
BA_ "GenSigRoutingTimeoutValue" SG_ 400 Rr_MotorAvailTq 4095;
BA_ "GenSigInvalidValue" SG_ 400 Rr_TMiq 32767;
BA_ "GenSigStartValue" SG_ 400 Rr_TMiq 15000;
BA_ "GenSigInvalidValue" SG_ 400 Rr_TMid 32767;
BA_ "GenSigStartValue" SG_ 400 Rr_TMid 15000;
BA_ "GenSigInvalidValue" SG_ 400 Rr_TMTemp 511;
BA_ "GenSigRoutingTimeoutValue_String" SG_ 400 Rr_TMTemp "0x1FF";
BA_ "GenSigInactiveValue" SG_ 400 Rr_TMTemp 511;
BA_ "GenSigRoutingTimeoutValue" SG_ 400 Rr_TMTemp 511;
BA_ "GenSigInvalidValue" SG_ 400 Rr_MCUTemp 511;
BA_ "GenSigRoutingTimeoutValue_String" SG_ 400 Rr_MCUTemp "0x1FF";
BA_ "GenSigInactiveValue" SG_ 400 Rr_MCUTemp 511;
BA_ "GenSigRoutingTimeoutValue" SG_ 400 Rr_MCUTemp 511;
BA_ "GenSigInvalidValue" SG_ 400 Rr_MCUDCBusCurr 32767;
BA_ "GenSigStartValue" SG_ 400 Rr_MCUDCBusCurr 15000;
BA_ "DataCenterDataType" SG_ 400 Rr_MCUDCBusCurr "Decimal";
BA_ "GenSigInvalidValue" SG_ 400 Rr_MCUDCBusVolt 65535;
BA_ "DataCenterDataType" SG_ 400 Rr_MCUDCBusVolt "INT(3)";
BA_ "GenSigInvalidValue" SG_ 400 Rr_TMSpd 65535;
BA_ "GenSigStartValue" SG_ 400 Rr_TMSpd 18000;
BA_ "GenSigRoutingTimeoutValue_String" SG_ 400 Rr_TMSpd "0xFFFF";
BA_ "GenSigInactiveValue" SG_ 400 Rr_TMSpd 65535;
BA_ "GenSigRoutingTimeoutValue" SG_ 400 Rr_TMSpd 65535;
BA_ "DataCenterDataType" SG_ 400 Rr_TMSpd "INT(5)";
BA_ "GenSigInvalidValue" SG_ 400 Rr_EDURealTMTq 65535;
BA_ "GenSigStartValue" SG_ 400 Rr_EDURealTMTq 10220;
BA_ "GenSigRoutingTimeoutValue_String" SG_ 400 Rr_EDURealTMTq "0xFFFF";
BA_ "GenSigInactiveValue" SG_ 400 Rr_EDURealTMTq 65535;
BA_ "GenSigRoutingTimeoutValue" SG_ 400 Rr_EDURealTMTq 65535;
BA_ "DataCenterDataType" SG_ 400 Rr_EDURealTMTq "INT(4)";
BA_ "GenSigInvalidValue" SG_ 400 Rr_EDUTqReqFbk 4095;
BA_ "GenSigStartValue" SG_ 400 Rr_EDUTqReqFbk 1022;
BA_ "GenSigInvalidValue" SG_ 400 MCU_B_R_RealPwrKw_Sta 65535;
BA_ "GenSigStartValue" SG_ 400 MCU_B_R_RealPwrKw_Sta 5300;
BA_ "GenSigRoutingTimeoutValue_String" SG_ 400 MCU_B_R_RealPwrKw_Sta "0xFFFF";
BA_ "GenSigInactiveValue" SG_ 400 MCU_B_R_RealPwrKw_Sta 5300;
BA_ "GenSigRoutingTimeoutValue" SG_ 400 MCU_B_R_RealPwrKw_Sta 65535;
BA_ "GenSigInvalidValue" SG_ 400 MCU_B_R_IGBTDdeTemp_Sta 511;
BA_ "GenSigStartValue" SG_ 400 MCU_B_R_IGBTDdeTemp_Sta 40;
BA_ "GenSigRoutingTimeoutValue_String" SG_ 400 MCU_B_R_IGBTDdeTemp_Sta "0x1FF";
BA_ "GenSigInactiveValue" SG_ 400 MCU_B_R_IGBTDdeTemp_Sta 40;
BA_ "GenSigRoutingTimeoutValue" SG_ 400 MCU_B_R_IGBTDdeTemp_Sta 511;
BA_ "GenSigStartValue" SG_ 402 MCUWarn_R_Nidec 7;
BA_ "GenSigInvalidValue" SG_ 402 Rr_MCUBAT_Nidec 255;
BA_ "GenSigInvalidValue" SG_ 402 Rr_RegenAvailTq_Nidec 4095;
BA_ "GenSigInvalidValue" SG_ 402 Rr_MotorAvailTq_Nidec 4095;
BA_ "GenSigRoutingTimeoutValue_String" SG_ 402 Rr_MotorAvailTq_Nidec "0xFFF";
BA_ "GenSigInactiveValue" SG_ 402 Rr_MotorAvailTq_Nidec 4095;
BA_ "GenSigRoutingTimeoutValue" SG_ 402 Rr_MotorAvailTq_Nidec 4095;
BA_ "GenSigInvalidValue" SG_ 402 Rr_TMiq_Nidec 32767;
BA_ "GenSigStartValue" SG_ 402 Rr_TMiq_Nidec 15000;
BA_ "GenSigInvalidValue" SG_ 402 Rr_TMid_Nidec 32767;
BA_ "GenSigStartValue" SG_ 402 Rr_TMid_Nidec 15000;
BA_ "GenSigInvalidValue" SG_ 402 Rr_TMTemp_Nidec 511;
BA_ "GenSigRoutingTimeoutValue_String" SG_ 402 Rr_TMTemp_Nidec "0x1FF";
BA_ "GenSigInactiveValue" SG_ 402 Rr_TMTemp_Nidec 511;
BA_ "GenSigRoutingTimeoutValue" SG_ 402 Rr_TMTemp_Nidec 511;
BA_ "GenSigInvalidValue" SG_ 402 Rr_MCUTemp_Nidec 511;
BA_ "GenSigRoutingTimeoutValue_String" SG_ 402 Rr_MCUTemp_Nidec "0x1FF";
BA_ "GenSigInactiveValue" SG_ 402 Rr_MCUTemp_Nidec 511;
BA_ "GenSigRoutingTimeoutValue" SG_ 402 Rr_MCUTemp_Nidec 511;
BA_ "GenSigInvalidValue" SG_ 402 Rr_MCUDCBusCurr_Nidec 32767;
BA_ "GenSigStartValue" SG_ 402 Rr_MCUDCBusCurr_Nidec 15000;
BA_ "DataCenterDataType" SG_ 402 Rr_MCUDCBusCurr_Nidec "Decimal";
BA_ "GenSigInvalidValue" SG_ 402 Rr_MCUDCBusVolt_Nidec 65535;
BA_ "DataCenterDataType" SG_ 402 Rr_MCUDCBusVolt_Nidec "INT(3)";
BA_ "GenSigInvalidValue" SG_ 402 Rr_TMSpd_Nidec 65535;
BA_ "GenSigStartValue" SG_ 402 Rr_TMSpd_Nidec 17000;
BA_ "GenSigRoutingTimeoutValue_String" SG_ 402 Rr_TMSpd_Nidec "0xFFFF";
BA_ "GenSigInactiveValue" SG_ 402 Rr_TMSpd_Nidec 65535;
BA_ "GenSigRoutingTimeoutValue" SG_ 402 Rr_TMSpd_Nidec 65535;
BA_ "DataCenterDataType" SG_ 402 Rr_TMSpd_Nidec "INT(5)";
BA_ "GenSigInvalidValue" SG_ 402 Rr_EDURealTMTq_Nidec 4095;
BA_ "GenSigStartValue" SG_ 402 Rr_EDURealTMTq_Nidec 1022;
BA_ "GenSigRoutingTimeoutValue_String" SG_ 402 Rr_EDURealTMTq_Nidec "0xFFF";
BA_ "GenSigInactiveValue" SG_ 402 Rr_EDURealTMTq_Nidec 4095;
BA_ "GenSigRoutingTimeoutValue" SG_ 402 Rr_EDURealTMTq_Nidec 4095;
BA_ "DataCenterDataType" SG_ 402 Rr_EDURealTMTq_Nidec "INT(4)";
BA_ "GenSigInvalidValue" SG_ 402 Rr_EDUTqReqFbk_Nidec 4095;
BA_ "GenSigStartValue" SG_ 402 Rr_EDUTqReqFbk_Nidec 1022;
BA_ "GenSigInvalidValue" SG_ 403 Rr_LLCflowReq 63;
BA_ "GenSigInvalidValue" SG_ 403 Rr_CoolanttempReq 511;
BA_ "GenSigStartValue" SG_ 403 Rr_CoolanttempReq 40;
BA_ "GenSigInvalidValue" SG_ 403 Rr_TMTempWarn 3;
BA_ "GenSigStartValue" SG_ 403 Rr_TMTempWarn 3;
BA_ "GenSigRoutingTimeoutValue_String" SG_ 403 Rr_TMTempWarn "0x3";
BA_ "GenSigInactiveValue" SG_ 403 Rr_TMTempWarn 3;
BA_ "GenSigRoutingTimeoutValue" SG_ 403 Rr_TMTempWarn 3;
BA_ "DataCenterDataType" SG_ 403 Rr_TMTempWarn "Varchar(10)";
BA_ "GenSigInvalidValue" SG_ 403 Rr_MCUTempWarn 3;
BA_ "GenSigStartValue" SG_ 403 Rr_MCUTempWarn 3;
BA_ "GenSigRoutingTimeoutValue_String" SG_ 403 Rr_MCUTempWarn "0x3";
BA_ "GenSigInactiveValue" SG_ 403 Rr_MCUTempWarn 3;
BA_ "GenSigRoutingTimeoutValue" SG_ 403 Rr_MCUTempWarn 3;
BA_ "DataCenterDataType" SG_ 403 Rr_MCUTempWarn "Varchar(10)";
BA_ "GenSigInvalidValue" SG_ 403 Rr_LLCTemp 511;
BA_ "GenSigStartValue" SG_ 403 Rr_LLCTemp 40;
BA_ "GenSigInvalidValue" SG_ 403 MCU_B_R_LLCTempWarn_Sta 3;
BA_ "GenSigRoutingTimeoutValue_String" SG_ 403 MCU_B_R_LLCTempWarn_Sta "0x3";
BA_ "GenSigInactiveValue" SG_ 403 MCU_B_R_LLCTempWarn_Sta 3;
BA_ "GenSigRoutingTimeoutValue" SG_ 403 MCU_B_R_LLCTempWarn_Sta 3;
BA_ "GenSigInvalidValue" SG_ 403 MCU_B_R_FailLv_Sta 7;
BA_ "GenSigRoutingTimeoutValue_String" SG_ 403 MCU_B_R_FailLv_Sta "0x7";
BA_ "GenSigRoutingTimeoutValue" SG_ 403 MCU_B_R_FailLv_Sta 7;
BA_ "GenSigInvalidValue" SG_ 403 MCU_B_R_KL302TqCnt_Sta 255;
BA_ "GenSigRoutingTimeoutValue_String" SG_ 403 MCU_B_R_KL302TqCnt_Sta "0xFF";
BA_ "GenSigRoutingTimeoutValue" SG_ 403 MCU_B_R_KL302TqCnt_Sta 255;
BA_ "GenSigInvalidValue" SG_ 412 Rr_CoolanttempReq_Nidec 511;
BA_ "GenSigStartValue" SG_ 412 Rr_CoolanttempReq_Nidec 40;
BA_ "GenSigInvalidValue" SG_ 412 Rr_TMTempWarn_Nidec 3;
BA_ "GenSigStartValue" SG_ 412 Rr_TMTempWarn_Nidec 3;
BA_ "GenSigRoutingTimeoutValue_String" SG_ 412 Rr_TMTempWarn_Nidec "0x3";
BA_ "GenSigInactiveValue" SG_ 412 Rr_TMTempWarn_Nidec 3;
BA_ "GenSigRoutingTimeoutValue" SG_ 412 Rr_TMTempWarn_Nidec 3;
BA_ "DataCenterDataType" SG_ 412 Rr_TMTempWarn_Nidec "Varchar(10)";
BA_ "GenSigInvalidValue" SG_ 412 Rr_MCUTempWarn_Nidec 3;
BA_ "GenSigStartValue" SG_ 412 Rr_MCUTempWarn_Nidec 3;
BA_ "GenSigRoutingTimeoutValue_String" SG_ 412 Rr_MCUTempWarn_Nidec "0x3";
BA_ "GenSigInactiveValue" SG_ 412 Rr_MCUTempWarn_Nidec 3;
BA_ "GenSigRoutingTimeoutValue" SG_ 412 Rr_MCUTempWarn_Nidec 3;
BA_ "DataCenterDataType" SG_ 412 Rr_MCUTempWarn_Nidec "Varchar(10)";
BA_ "GenSigInvalidValue" SG_ 412 Rr_EOP_SpdSet_Nidec 4095;
BA_ "GenSigInvalidValue" SG_ 412 Rr_LLCTemp_Nidec 511;
BA_ "GenSigStartValue" SG_ 412 Rr_LLCTemp_Nidec 40;
BA_ "GenSigInvalidValue" SG_ 412 Rr_LLCflowReq_Nidec 63;
BA_ "DataCenterDataType" SG_ 412 MCU_R_ResetCnt_Sta "INT(3)";
BA_ "GenSigSendType" SG_ 1283 NM_MCU_N_R_Node_ID 7;
BA_ "GenSigSendType" SG_ 1283 NM_MCU_N_R_Rpt_Msg_Req 7;
BA_ "GenSigSendType" SG_ 1283 NM_MCU_N_R_CSB 7;
BA_ "GenSigSendType" SG_ 1283 NM_MCU_N_R_Active_WU 7;
BA_ "GenSigSendType" SG_ 1283 NM_MCU_N_R_PNI 7;
BA_ "GenSigSendType" SG_ 1283 NM_MCU_N_R_ERROR_State 7;
BA_ "GenSigSendType" SG_ 1539 DiagRespFromMCU_N_R 3;
BA_ "GenSigSendType" SG_ 385 Shifter_CRC8 3;
BA_ "GenSigSendType" SG_ 385 Shifter_RC 3;
BA_ "GenSigRoutingTimeoutValue_String" SG_ 385 Shifter_Fail_sta "0x3";
BA_ "GenSigRoutingTimeoutValue" SG_ 385 Shifter_Fail_sta 3;
BA_ "GenSigSendType" SG_ 385 Shifter_Fail_sta 3;
BA_ "GenSigInvalidValue" SG_ 385 Shifter_Handle_Cmd 255;
BA_ "GenSigRoutingTimeoutValue_String" SG_ 385 Shifter_Handle_Cmd "0xFF";
BA_ "GenSigRoutingTimeoutValue" SG_ 385 Shifter_Handle_Cmd 255;
BA_ "GenSigSendType" SG_ 385 Shifter_Handle_Cmd 3;
BA_ "GenSigSendType" SG_ 1336 NM_Shifter_Node_ID 7;
BA_ "GenSigSendType" SG_ 1336 NM_Shifter_Rpt_Msg_Req 7;
BA_ "GenSigSendType" SG_ 1336 NM_Shifter_CSB 7;
BA_ "GenSigSendType" SG_ 1336 NM_Shifter_Active_WU 7;
BA_ "GenSigSendType" SG_ 1336 NM_Shifter_PNI 7;
BA_ "GenSigSendType" SG_ 1336 NM_Shifter_ERROR_State 7;
BA_ "GenSigSendType" SG_ 1592 DiagRespFromShifter 3;
BA_ "GenSigSendType" SG_ 1545 DiagRespFromMCU_B_R 3;
BA_ "GenSigSendType" SG_ 1673 DiagPhysReqToMCU_B_R 3;
BA_ "GenSigSendType" SG_ 1674 DiagPhysReqToMCU_B_F 3;
BA_ "GenSigSendType" SG_ 1546 DiagRespFromMCU_B_F 3;
BA_ "GenSigSendType" SG_ 1289 NM_MCU_B_R_Node_ID 7;
BA_ "GenSigSendType" SG_ 1289 NM_MCU_B_R_ERROR_State 7;
BA_ "GenSigSendType" SG_ 1289 NM_MCU_B_R_Active_WU 7;
BA_ "GenSigSendType" SG_ 1289 NM_MCU_B_R_CSB 7;
BA_ "GenSigSendType" SG_ 1289 NM_MCU_B_R_PNI 7;
BA_ "GenSigSendType" SG_ 1289 NM_MCU_B_R_Rpt_Msg_Req 7;
BA_ "GenSigSendType" SG_ 1290 NM_MCU_B_F_Node_ID 7;
BA_ "GenSigSendType" SG_ 1290 NM_MCU_B_F_ERROR_State 7;
BA_ "GenSigSendType" SG_ 1290 NM_MCU_B_F_Active_WU 7;
BA_ "GenSigSendType" SG_ 1290 NM_MCU_B_F_CSB 7;
BA_ "GenSigSendType" SG_ 1290 NM_MCU_B_F_PNI 7;
BA_ "GenSigSendType" SG_ 1290 NM_MCU_B_F_Rpt_Msg_Req 7;
BA_ "GenSigInvalidValue" SG_ 368 CSW2_TurnSw_Sta 5;
BA_ "GenSigRoutingTimeoutValue_String" SG_ 368 CSW2_TurnSw_Sta "0x5";
BA_ "GenSigRoutingTimeoutValue" SG_ 368 CSW2_TurnSw_Sta 5;
BA_ "GenSigSendType" SG_ 368 CSW2_TurnSw_Sta 3;
BA_ "GenSigInvalidValue" SG_ 368 CSW2_FWipSw_Sta 7;
BA_ "GenSigRoutingTimeoutValue_String" SG_ 368 CSW2_FWipSw_Sta "0x7";
BA_ "GenSigRoutingTimeoutValue" SG_ 368 CSW2_FWipSw_Sta 7;
BA_ "GenSigSendType" SG_ 368 CSW2_FWipSw_Sta 3;
BA_ "GenSigInvalidValue" SG_ 368 CSW2_RWipWasSw_Sta 3;
BA_ "GenSigRoutingTimeoutValue_String" SG_ 368 CSW2_RWipWasSw_Sta "0x3";
BA_ "GenSigRoutingTimeoutValue" SG_ 368 CSW2_RWipWasSw_Sta 3;
BA_ "GenSigSendType" SG_ 368 CSW2_RWipWasSw_Sta 3;
BA_ "GenSigInvalidValue" SG_ 368 CSW2_FWasSw_Sta 3;
BA_ "GenSigRoutingTimeoutValue_String" SG_ 368 CSW2_FWasSw_Sta "0x3";
BA_ "GenSigRoutingTimeoutValue" SG_ 368 CSW2_FWasSw_Sta 3;
BA_ "GenSigSendType" SG_ 368 CSW2_FWasSw_Sta 3;
BA_ "GenSigSendType" SG_ 368 CSW2_PassSW_Sta 3;
BA_ "GenSigSendType" SG_ 368 CSW2_DimSw_Sta 3;
BA_ "GenSigSendType" SG_ 2015 DiagFuncReqOBD 3;
BA_ "GenSigInvalidValue" SG_ 564 CellVoltage160 65535;
BA_ "DataCenterDataType" SG_ 564 CellVoltage160 "int(5)";
BA_ "GenSigInvalidValue" SG_ 564 CellVoltage159 65535;
BA_ "DataCenterDataType" SG_ 564 CellVoltage159 "int(5)";
BA_ "GenSigInvalidValue" SG_ 564 CellVoltage158 65535;
BA_ "DataCenterDataType" SG_ 564 CellVoltage158 "int(5)";
BA_ "GenSigInvalidValue" SG_ 564 CellVoltage157 65535;
BA_ "DataCenterDataType" SG_ 564 CellVoltage157 "int(5)";
BA_ "GenSigInvalidValue" SG_ 564 CellVoltage156 65535;
BA_ "DataCenterDataType" SG_ 564 CellVoltage156 "int(5)";
BA_ "GenSigInvalidValue" SG_ 564 CellVoltage155 65535;
BA_ "DataCenterDataType" SG_ 564 CellVoltage155 "int(5)";
BA_ "GenSigInvalidValue" SG_ 564 CellVoltage154 65535;
BA_ "DataCenterDataType" SG_ 564 CellVoltage154 "int(5)";
BA_ "GenSigInvalidValue" SG_ 564 CellVoltage153 65535;
BA_ "DataCenterDataType" SG_ 564 CellVoltage153 "int(5)";
BA_ "GenSigInvalidValue" SG_ 564 CellVoltage152 65535;
BA_ "DataCenterDataType" SG_ 564 CellVoltage152 "int(5)";
BA_ "GenSigInvalidValue" SG_ 564 CellVoltage151 65535;
BA_ "DataCenterDataType" SG_ 564 CellVoltage151 "int(5)";
BA_ "GenSigInvalidValue" SG_ 564 CellVoltage150 65535;
BA_ "DataCenterDataType" SG_ 564 CellVoltage150 "int(5)";
BA_ "GenSigInvalidValue" SG_ 564 CellVoltage149 65535;
BA_ "DataCenterDataType" SG_ 564 CellVoltage149 "int(5)";
BA_ "GenSigInvalidValue" SG_ 564 CellVoltage148 65535;
BA_ "DataCenterDataType" SG_ 564 CellVoltage148 "int(5)";
BA_ "GenSigInvalidValue" SG_ 564 CellVoltage147 65535;
BA_ "DataCenterDataType" SG_ 564 CellVoltage147 "int(5)";
BA_ "GenSigInvalidValue" SG_ 564 CellVoltage146 65535;
BA_ "DataCenterDataType" SG_ 564 CellVoltage146 "int(5)";
BA_ "GenSigInvalidValue" SG_ 564 CellVoltage145 65535;
BA_ "DataCenterDataType" SG_ 564 CellVoltage145 "int(5)";
BA_ "GenSigInvalidValue" SG_ 564 CellVoltage144 65535;
BA_ "DataCenterDataType" SG_ 564 CellVoltage144 "int(5)";
BA_ "GenSigInvalidValue" SG_ 564 CellVoltage143 65535;
BA_ "DataCenterDataType" SG_ 564 CellVoltage143 "int(5)";
BA_ "GenSigInvalidValue" SG_ 564 CellVoltage142 65535;
BA_ "DataCenterDataType" SG_ 564 CellVoltage142 "int(5)";
BA_ "GenSigInvalidValue" SG_ 564 CellVoltage141 65535;
BA_ "DataCenterDataType" SG_ 564 CellVoltage141 "int(5)";
BA_ "GenSigInvalidValue" SG_ 564 CellVoltage140 65535;
BA_ "DataCenterDataType" SG_ 564 CellVoltage140 "int(5)";
BA_ "GenSigInvalidValue" SG_ 564 CellVoltage139 65535;
BA_ "DataCenterDataType" SG_ 564 CellVoltage139 "int(5)";
BA_ "GenSigInvalidValue" SG_ 564 CellVoltage138 65535;
BA_ "DataCenterDataType" SG_ 564 CellVoltage138 "int(5)";
BA_ "GenSigInvalidValue" SG_ 564 CellVoltage137 65535;
BA_ "DataCenterDataType" SG_ 564 CellVoltage137 "int(5)";
BA_ "GenSigInvalidValue" SG_ 564 CellVoltage136 65535;
BA_ "DataCenterDataType" SG_ 564 CellVoltage136 "int(5)";
BA_ "GenSigInvalidValue" SG_ 564 CellVoltage135 65535;
BA_ "DataCenterDataType" SG_ 564 CellVoltage135 "int(5)";
BA_ "GenSigInvalidValue" SG_ 564 CellVoltage134 65535;
BA_ "DataCenterDataType" SG_ 564 CellVoltage134 "int(5)";
BA_ "GenSigInvalidValue" SG_ 564 CellVoltage133 65535;
BA_ "DataCenterDataType" SG_ 564 CellVoltage133 "int(5)";
BA_ "GenSigInvalidValue" SG_ 564 CellVoltage132 65535;
BA_ "DataCenterDataType" SG_ 564 CellVoltage132 "int(5)";
BA_ "GenSigInvalidValue" SG_ 564 CellVoltage131 65535;
BA_ "DataCenterDataType" SG_ 564 CellVoltage131 "int(5)";
BA_ "GenSigInvalidValue" SG_ 564 CellVoltage130 65535;
BA_ "DataCenterDataType" SG_ 564 CellVoltage130 "int(5)";
BA_ "GenSigInvalidValue" SG_ 564 CellVoltage129 65535;
BA_ "DataCenterDataType" SG_ 564 CellVoltage129 "int(5)";
BA_ "GenSigInvalidValue" SG_ 565 CellVoltage192 65535;
BA_ "DataCenterDataType" SG_ 565 CellVoltage192 "int(5)";
BA_ "GenSigInvalidValue" SG_ 565 CellVoltage191 65535;
BA_ "DataCenterDataType" SG_ 565 CellVoltage191 "int(5)";
BA_ "GenSigInvalidValue" SG_ 565 CellVoltage190 65535;
BA_ "DataCenterDataType" SG_ 565 CellVoltage190 "int(5)";
BA_ "GenSigInvalidValue" SG_ 565 CellVoltage189 65535;
BA_ "DataCenterDataType" SG_ 565 CellVoltage189 "int(5)";
BA_ "GenSigInvalidValue" SG_ 565 CellVoltage188 65535;
BA_ "DataCenterDataType" SG_ 565 CellVoltage188 "int(5)";
BA_ "GenSigInvalidValue" SG_ 565 CellVoltage187 65535;
BA_ "DataCenterDataType" SG_ 565 CellVoltage187 "int(5)";
BA_ "GenSigInvalidValue" SG_ 565 CellVoltage186 65535;
BA_ "DataCenterDataType" SG_ 565 CellVoltage186 "int(5)";
BA_ "GenSigInvalidValue" SG_ 565 CellVoltage185 65535;
BA_ "DataCenterDataType" SG_ 565 CellVoltage185 "int(5)";
BA_ "GenSigInvalidValue" SG_ 565 CellVoltage184 65535;
BA_ "DataCenterDataType" SG_ 565 CellVoltage184 "int(5)";
BA_ "GenSigInvalidValue" SG_ 565 CellVoltage183 65535;
BA_ "DataCenterDataType" SG_ 565 CellVoltage183 "int(5)";
BA_ "GenSigInvalidValue" SG_ 565 CellVoltage182 65535;
BA_ "DataCenterDataType" SG_ 565 CellVoltage182 "int(5)";
BA_ "GenSigInvalidValue" SG_ 565 CellVoltage181 65535;
BA_ "DataCenterDataType" SG_ 565 CellVoltage181 "int(5)";
BA_ "GenSigInvalidValue" SG_ 565 CellVoltage180 65535;
BA_ "DataCenterDataType" SG_ 565 CellVoltage180 "int(5)";
BA_ "GenSigInvalidValue" SG_ 565 CellVoltage179 65535;
BA_ "DataCenterDataType" SG_ 565 CellVoltage179 "int(5)";
BA_ "GenSigInvalidValue" SG_ 565 CellVoltage178 65535;
BA_ "DataCenterDataType" SG_ 565 CellVoltage178 "int(5)";
BA_ "GenSigInvalidValue" SG_ 565 CellVoltage177 65535;
BA_ "DataCenterDataType" SG_ 565 CellVoltage177 "int(5)";
BA_ "GenSigInvalidValue" SG_ 565 CellVoltage176 65535;
BA_ "DataCenterDataType" SG_ 565 CellVoltage176 "int(5)";
BA_ "GenSigInvalidValue" SG_ 565 CellVoltage175 65535;
BA_ "DataCenterDataType" SG_ 565 CellVoltage175 "int(5)";
BA_ "GenSigInvalidValue" SG_ 565 CellVoltage174 65535;
BA_ "DataCenterDataType" SG_ 565 CellVoltage174 "int(5)";
BA_ "GenSigInvalidValue" SG_ 565 CellVoltage173 65535;
BA_ "DataCenterDataType" SG_ 565 CellVoltage173 "int(5)";
BA_ "GenSigInvalidValue" SG_ 565 CellVoltage172 65535;
BA_ "DataCenterDataType" SG_ 565 CellVoltage172 "int(5)";
BA_ "GenSigInvalidValue" SG_ 565 CellVoltage171 65535;
BA_ "DataCenterDataType" SG_ 565 CellVoltage171 "int(5)";
BA_ "GenSigInvalidValue" SG_ 565 CellVoltage170 65535;
BA_ "DataCenterDataType" SG_ 565 CellVoltage170 "int(5)";
BA_ "GenSigInvalidValue" SG_ 565 CellVoltage169 65535;
BA_ "DataCenterDataType" SG_ 565 CellVoltage169 "int(5)";
BA_ "GenSigInvalidValue" SG_ 565 CellVoltage168 65535;
BA_ "DataCenterDataType" SG_ 565 CellVoltage168 "int(5)";
BA_ "GenSigInvalidValue" SG_ 565 CellVoltage167 65535;
BA_ "DataCenterDataType" SG_ 565 CellVoltage167 "int(5)";
BA_ "GenSigInvalidValue" SG_ 565 CellVoltage166 65535;
BA_ "DataCenterDataType" SG_ 565 CellVoltage166 "int(5)";
BA_ "GenSigInvalidValue" SG_ 565 CellVoltage165 65535;
BA_ "DataCenterDataType" SG_ 565 CellVoltage165 "int(5)";
BA_ "GenSigInvalidValue" SG_ 565 CellVoltage164 65535;
BA_ "DataCenterDataType" SG_ 565 CellVoltage164 "int(5)";
BA_ "GenSigInvalidValue" SG_ 565 CellVoltage163 65535;
BA_ "DataCenterDataType" SG_ 565 CellVoltage163 "int(5)";
BA_ "GenSigInvalidValue" SG_ 565 CellVoltage162 65535;
BA_ "DataCenterDataType" SG_ 565 CellVoltage162 "int(5)";
BA_ "GenSigInvalidValue" SG_ 565 CellVoltage161 65535;
BA_ "DataCenterDataType" SG_ 565 CellVoltage161 "int(5)";
BA_ "GenSigInvalidValue" SG_ 566 CellVoltage216 65535;
BA_ "DataCenterDataType" SG_ 566 CellVoltage216 "int(5)";
BA_ "GenSigInvalidValue" SG_ 566 CellVoltage215 65535;
BA_ "DataCenterDataType" SG_ 566 CellVoltage215 "int(5)";
BA_ "GenSigInvalidValue" SG_ 566 CellVoltage214 65535;
BA_ "DataCenterDataType" SG_ 566 CellVoltage214 "int(5)";
BA_ "GenSigInvalidValue" SG_ 566 CellVoltage213 65535;
BA_ "DataCenterDataType" SG_ 566 CellVoltage213 "int(5)";
BA_ "GenSigInvalidValue" SG_ 566 CellVoltage212 65535;
BA_ "DataCenterDataType" SG_ 566 CellVoltage212 "int(5)";
BA_ "GenSigInvalidValue" SG_ 566 CellVoltage211 65535;
BA_ "DataCenterDataType" SG_ 566 CellVoltage211 "int(5)";
BA_ "GenSigInvalidValue" SG_ 566 CellVoltage210 65535;
BA_ "DataCenterDataType" SG_ 566 CellVoltage210 "int(5)";
BA_ "GenSigInvalidValue" SG_ 566 CellVoltage209 65535;
BA_ "DataCenterDataType" SG_ 566 CellVoltage209 "int(5)";
BA_ "GenSigInvalidValue" SG_ 566 CellVoltage208 65535;
BA_ "DataCenterDataType" SG_ 566 CellVoltage208 "int(5)";
BA_ "GenSigInvalidValue" SG_ 566 CellVoltage207 65535;
BA_ "DataCenterDataType" SG_ 566 CellVoltage207 "int(5)";
BA_ "GenSigInvalidValue" SG_ 566 CellVoltage206 65535;
BA_ "DataCenterDataType" SG_ 566 CellVoltage206 "int(5)";
BA_ "GenSigInvalidValue" SG_ 566 CellVoltage205 65535;
BA_ "DataCenterDataType" SG_ 566 CellVoltage205 "int(5)";
BA_ "GenSigInvalidValue" SG_ 566 CellVoltage204 65535;
BA_ "DataCenterDataType" SG_ 566 CellVoltage204 "int(5)";
BA_ "GenSigInvalidValue" SG_ 566 CellVoltage203 65535;
BA_ "DataCenterDataType" SG_ 566 CellVoltage203 "int(5)";
BA_ "GenSigInvalidValue" SG_ 566 CellVoltage202 65535;
BA_ "DataCenterDataType" SG_ 566 CellVoltage202 "int(5)";
BA_ "GenSigInvalidValue" SG_ 566 CellVoltage201 65535;
BA_ "DataCenterDataType" SG_ 566 CellVoltage201 "int(5)";
BA_ "GenSigInvalidValue" SG_ 566 CellVoltage200 65535;
BA_ "DataCenterDataType" SG_ 566 CellVoltage200 "int(5)";
BA_ "GenSigInvalidValue" SG_ 566 CellVoltage199 65535;
BA_ "DataCenterDataType" SG_ 566 CellVoltage199 "int(5)";
BA_ "GenSigInvalidValue" SG_ 566 CellVoltage198 65535;
BA_ "DataCenterDataType" SG_ 566 CellVoltage198 "int(5)";
BA_ "GenSigInvalidValue" SG_ 566 CellVoltage197 65535;
BA_ "DataCenterDataType" SG_ 566 CellVoltage197 "int(5)";
BA_ "GenSigInvalidValue" SG_ 566 CellVoltage196 65535;
BA_ "DataCenterDataType" SG_ 566 CellVoltage196 "int(5)";
BA_ "GenSigInvalidValue" SG_ 566 CellVoltage195 65535;
BA_ "DataCenterDataType" SG_ 566 CellVoltage195 "int(5)";
BA_ "GenSigInvalidValue" SG_ 566 CellVoltage194 65535;
BA_ "DataCenterDataType" SG_ 566 CellVoltage194 "int(5)";
BA_ "GenSigInvalidValue" SG_ 566 CellVoltage193 65535;
BA_ "DataCenterDataType" SG_ 566 CellVoltage193 "int(5)";
BA_ "GenSigInvalidValue" SG_ 409 MCU_FVT_R_TMSpd_Sta 65535;
BA_ "GenSigStartValue" SG_ 409 MCU_FVT_R_TMSpd_Sta 22000;
BA_ "GenSigRoutingTimeoutValue_String" SG_ 409 MCU_FVT_R_TMSpd_Sta "0xFFFF";
BA_ "GenSigInactiveValue" SG_ 409 MCU_FVT_R_TMSpd_Sta 65535;
BA_ "GenSigRoutingTimeoutValue" SG_ 409 MCU_FVT_R_TMSpd_Sta 65535;
BA_ "GenSigInvalidValue" SG_ 409 MCU_FVT_R_EDUTqReq_Fbk 65535;
BA_ "GenSigStartValue" SG_ 409 MCU_FVT_R_EDUTqReq_Fbk 10220;
BA_ "GenSigRoutingTimeoutValue_String" SG_ 409 MCU_FVT_R_EDUTqReq_Fbk "0xFFFF";
BA_ "GenSigInactiveValue" SG_ 409 MCU_FVT_R_EDUTqReq_Fbk 65535;
BA_ "GenSigRoutingTimeoutValue" SG_ 409 MCU_FVT_R_EDUTqReq_Fbk 65535;
BA_ "GenSigInvalidValue" SG_ 409 MCU_FVT_R_Failcode3_Sta 255;
BA_ "GenSigRoutingTimeoutValue_String" SG_ 409 MCU_FVT_R_Failcode3_Sta "0xFF";
BA_ "GenSigRoutingTimeoutValue" SG_ 409 MCU_FVT_R_Failcode3_Sta 255;
BA_ "GenSigInvalidValue" SG_ 409 MCU_FVT_R_OilTemp_Sta 511;
BA_ "GenSigStartValue" SG_ 409 MCU_FVT_R_OilTemp_Sta 40;
BA_ "GenSigRoutingTimeoutValue_String" SG_ 409 MCU_FVT_R_OilTemp_Sta "0x1FF";
BA_ "GenSigInactiveValue" SG_ 409 MCU_FVT_R_OilTemp_Sta 511;
BA_ "GenSigRoutingTimeoutValue" SG_ 409 MCU_FVT_R_OilTemp_Sta 511;
BA_ "GenSigRoutingTimeoutValue" SG_ 409 MCU_FVT_R_MCUBAT_Sta 511;
BA_ "GenSigInvalidValue" SG_ 409 MCU_FVT_R_MCUSys_Sta 15;
BA_ "GenSigStartValue" SG_ 409 MCU_FVT_R_MCUSys_Sta 6;
BA_ "GenSigRoutingTimeoutValue_String" SG_ 409 MCU_FVT_R_MCUSys_Sta "0xF";
BA_ "GenSigRoutingTimeoutValue" SG_ 409 MCU_FVT_R_MCUSys_Sta 15;
BA_ "GenSigRoutingTimeoutValue_String" SG_ 409 MCU_FVT_R_HeatingOP_Sta "0x0";
BA_ "GenSigRoutingTimeoutValue_String" SG_ 409 MCU_FVT_R_BoostOP_Sta "0x0";
BA_ "GenSigInvalidValue" SG_ 410 MCU_FVT_F_TMSpd_Sta 65535;
BA_ "GenSigStartValue" SG_ 410 MCU_FVT_F_TMSpd_Sta 22000;
BA_ "GenSigRoutingTimeoutValue_String" SG_ 410 MCU_FVT_F_TMSpd_Sta "0xFFFF";
BA_ "GenSigInactiveValue" SG_ 410 MCU_FVT_F_TMSpd_Sta 65535;
BA_ "GenSigRoutingTimeoutValue" SG_ 410 MCU_FVT_F_TMSpd_Sta 65535;
BA_ "GenSigInvalidValue" SG_ 410 MCU_FVT_F_EDUTqReq_Fbk 65535;
BA_ "GenSigStartValue" SG_ 410 MCU_FVT_F_EDUTqReq_Fbk 10220;
BA_ "GenSigRoutingTimeoutValue_String" SG_ 410 MCU_FVT_F_EDUTqReq_Fbk "0xFFFF";
BA_ "GenSigInactiveValue" SG_ 410 MCU_FVT_F_EDUTqReq_Fbk 65535;
BA_ "GenSigRoutingTimeoutValue" SG_ 410 MCU_FVT_F_EDUTqReq_Fbk 65535;
BA_ "GenSigInvalidValue" SG_ 410 MCU_FVT_F_Failcode3_Sta 255;
BA_ "GenSigRoutingTimeoutValue_String" SG_ 410 MCU_FVT_F_Failcode3_Sta "0xFF";
BA_ "GenSigRoutingTimeoutValue" SG_ 410 MCU_FVT_F_Failcode3_Sta 255;
BA_ "GenSigInvalidValue" SG_ 410 MCU_FVT_F_OilTemp_Sta 511;
BA_ "GenSigStartValue" SG_ 410 MCU_FVT_F_OilTemp_Sta 40;
BA_ "GenSigRoutingTimeoutValue_String" SG_ 410 MCU_FVT_F_OilTemp_Sta "0x1FF";
BA_ "GenSigInactiveValue" SG_ 410 MCU_FVT_F_OilTemp_Sta 511;
BA_ "GenSigRoutingTimeoutValue" SG_ 410 MCU_FVT_F_OilTemp_Sta 511;
BA_ "GenSigRoutingTimeoutValue" SG_ 410 MCU_FVT_F_MCUBAT_Sta 511;
BA_ "GenSigInvalidValue" SG_ 410 MCU_FVT_F_MCUSys_Sta 15;
BA_ "GenSigStartValue" SG_ 410 MCU_FVT_F_MCUSys_Sta 6;
BA_ "GenSigRoutingTimeoutValue_String" SG_ 410 MCU_FVT_F_MCUSys_Sta "0xF";
BA_ "GenSigRoutingTimeoutValue" SG_ 410 MCU_FVT_F_MCUSys_Sta 15;
BA_ "GenSigRoutingTimeoutValue_String" SG_ 410 MCU_FVT_F_HeatingOP_Sta "0x0";
BA_ "GenSigRoutingTimeoutValue_String" SG_ 410 MCU_FVT_F_BoostOP_Sta "0x0";
BA_ "GenSigSendType" SG_ 1731 DiagPhysReqToEOP_FVT_R 3;
BA_ "GenSigSendType" SG_ 1603 DiagRespFromEOP_FVT_R 3;
BA_ "GenSigSendType" SG_ 1732 DiagPhysReqToEOP_FVT_F 3;
BA_ "GenSigSendType" SG_ 1604 DiagRespFromEOP_FVT_F 3;
VAL_ 496 SysPwrSta 10 "ON_HVChrg" 9 "OFF-C_LVChrg" 8 "HVChrgPre-action" 7 "Power_down" 6 "Power_up" 5 "READY" 4 "ON_NoChrg" 3 "STANDBY" 2 "OFF-A" 1 "OFF-C_HVChrg" 0 "OFF";
VAL_ 496 PowerUpFault 8 "DCDC_SetVoltFail" 7 "DriverSafetyChkFail" 6 "SafetyChkFail" 5 "MCU_EnableFail" 4 "OBC_EnableFail" 3 "DCDC_EnableFail" 2 "BattUpFail" 1 "PreChargeChkFail" 0 "No Fault";
VAL_ 496 PowerUpState 9 "HVSysChk" 8 "DriverSafetyChk" 7 "SafetyChk" 6 "PowerUpFail" 5 "Completed" 4 "MCU_Enable" 3 "OBC_Enable" 2 "DCDC_Enable" 1 "BattPACK" 0 "Initialize";
VAL_ 496 PowerDownFault 7 "SafetyChkMLvFail" 6 "MCU_Disable" 5 "MCU_Discharge" 4 "BattPDFail" 3 "OBC_Disable" 2 "DCDC_Stop" 1 "DCDC_Disable" 0 "No Fault";
VAL_ 496 PowerDownState 7 "MCU_Disable" 6 "MLvSafetyChkPowerDown" 5 "Completed" 4 "OBC_Disable" 3 "MCU_DisCharge" 2 "BattPACK" 1 "DCDC Disable" 0 "Initialize";
VAL_ 496 TCountSta 2 "Counting finish" 1 "Timmer counting" 0 "No counting";
VAL_ 496 PwrStaConstraint 4 "Keep HV active for time" 3 "Keep power state ON for time" 2 "Keep HV active" 1 "Power state ON" 0 "No request";
VAL_ 496 PwrStaSelect 3 "Go OFF-A" 2 "Go OFF-C" 1 "Go ON" 0 "No request";
VAL_ 496 Rr_TqSource 9 "ForceIdle" 8 "APS" 7 "MSA" 6 "ADAS" 5 "CC" 4 "TCS" 3 "RollABS" 2 "ABS" 1 "Internal" 0 "Invalid";
VAL_ 496 PwrDownReq 2 "System request  power down" 1 "User request  power down" 0 "No request";
VAL_ 496 PwrUpReq 2 "System request  power up" 1 "User request  power up" 0 "No request";
VAL_ 496 HVTHCMSysAvail 3 "Invalid" 2 "Reserved" 1 "Failure" 0 "Normal";
VAL_ 496 LVBattVoltSta 3 "Invalid" 2 "Reserved" 1 "Failure" 0 "Normal";
VAL_ 496 Fr_TqSource 9 "ForceIdle" 8 "APS" 7 "MSA" 6 "ADAS" 5 "CC" 4 "TCS" 3 "RollABS" 2 "ABS" 1 "Internal" 0 "Invalid";
VAL_ 496 HVRlyOpFail 1 "Fail" 0 "Normal";
VAL_ 496 SysAllowReadySta 1 "Not allow ready" 0 "Normal";
VAL_ 496 VCURRDoorSta 1 "Fail" 0 "Normal";
VAL_ 496 VCURLDoorSta 1 "Fail" 0 "Normal";
VAL_ 496 VCUFRDoorSta 1 "Fail" 0 "Normal";
VAL_ 496 VCUFLDoorSta 1 "Fail" 0 "Normal";
VAL_ 496 VCUBrkSWSta 2 "Invalid" 1 "On" 0 "OFF";
VAL_ 496 PwrStaTOSta 1 "Timeout" 0 "Normal";
VAL_ 496 PwrStaONTOIVIPopReq 1 "On" 0 "OFF";
VAL_ 496 MCUActDisFail 1 "Fail" 0 "Normal";
VAL_ 496 TimerAllowSleep 1 "Allow sleep" 0 "Not allow sleep";
VAL_ 496 LVSilentChrgReq 1 "Request LV silent charging" 0 "No request,";
VAL_ 496 LVSilentChrgLv 3 "Level 3" 2 "Level 2" 1 "Level 1" 0 "Invalid";
VAL_ 496 LVSilentChrgSta 3 "Fault" 2 "Charging completed" 1 "Charging" 0 "No action";
VAL_ 496 SilentChkAllowSleep 1 "Allow sleep" 0 "Not allow sleep";
VAL_ 496 SchedChgTOSta 1 "Timeout" 0 "Normal";
VAL_ 496 EVCCAplusPwrUpReq 1 "Request" 0 "No Request";
VAL_ 496 PMMAllowECUSleep 1 "Allow sleep" 0 "Not allow sleep";
VAL_ 496 WisrBootReason 1048576 "WKPU_SRC_EXT_RTC" 16 "WKPU_SRC_LLCE_CAN4_RX" 524288 "WKPU_SRC_BRAKE_SW" 8 "WKPU_SRC_LLCE_CAN3_RX" 262144 "WKPU_SRC_IOEXP_INT_B1_FDC2" 4 "WKPU_SRC_LLCE_CAN2_RX" 131072 "WKPU_SRC_HAZARD_SW_IN" 2 "WKPU_SRC_LLCE_CAN1_RX" 65536 "WKPU_SRC_RR_AJAR_SW_IN" 1 "WKPU_SRC_FLEX_CAN_0_RXD" 32 "WKPU_SRC_LLCE_CAN5_RX" 256 "WKPU_SRC_BLE_WU_SOC" 2097152 "WKPU_SRC_RL_AJAR_SW_IN" 2048 "WKPU_SRC_FR_AJAR_SW_IN" 4096 "WKPU_SRC_IOEXP_INT_B_FDC1 or WKPU_SRC_FL_AJAR_SW_IN_FDC2" 1024 "WKPU_SRC_HOOD_AJAR_SW_IN 10" 512 "WKPU_SRC_EVCC_CP_WAKE" 64 "WKPU_SRC_LLCE_CAN6_RX";
VAL_ 496 PmicBootReason 4 "Unknown" 3 "Standby timer expired" 2 "Watchdog reset" 1 "WISR wake-up" 0 "Power cycle";
VAL_ 496 FDC_VCU_DTCCarousel_Sta 87 "P100A19" 86 "P100A18" 85 "P100A17" 84 "P100A16" 83 "P100A15" 82 "P100A14" 81 "P100A13" 80 "P100A12" 79 "P100A11" 78 "P100A10" 77 "U100A0F" 76 "U100A0E" 75 "U100A0D" 74 "U100A0C" 73 "U100A0B" 72 "U100A0A" 71 "U100A09" 70 "U100A08" 69 "U100A07" 68 "U100A06" 67 "U100A05" 66 "U100A04" 65 "U100A03" 64 "U100A02" 63 "U100A01" 62 "P100252" 61 "P100251" 60 "P100250" 59 "P100249" 58 "P100246" 57 "P100245" 56 "P100244" 55 "P100243" 54 "P100242" 53 "U100241" 52 "U100240" 51 "U10023F" 50 "U10023E" 49 "U10023D" 48 "U10023C" 47 "U10023B" 46 "U10023A" 45 "U100239" 44 "U100238" 43 "U100237" 42 "U100236" 41 "U100235" 40 "U100234" 39 "U100233" 38 "U100232" 37 "U100231" 36 "U100230" 35 "B10022F" 34 "B10022E" 33 "U10022D" 32 "U10022C" 31 "U10022B" 30 "U10022A" 29 "U100229" 28 "U100228" 27 "P100227" 26 "P100226" 25 "P100225" 24 "P100224" 23 "P100223" 22 "P100221" 21 "P100220" 20 "B10021F" 19 "P10021E" 18 "P10021D" 17 "P10021C" 16 "P10021B" 15 "P10021A" 14 "P100219" 13 "P100218" 12 "P100217" 11 "P100216" 10 "P100215" 9 "P100214" 8 "P100213" 7 "P100212" 6 "P100211" 5 "P100210" 4 "P10020E" 3 "P10020D" 2 "P10020C" 1 "P10020B" 0 "0";
VAL_ 496 FDC_VCU_VehMalfunLevel_Sta 5 "Invalid" 4 "4th grade malfunction" 3 "3rd grade malfunction" 2 "2nd grade malfunction" 1 "1st grade malfunction" 0 "Normal";
VAL_ 496 FDC_VCU_RWDRDCActive_Sta 2 "Exit immediately" 1 "Ramp out" 0 "No request";
VAL_ 496 FDC_VCU_AllowMovThd_OTA_Sta 2 "Invalid" 1 "Not allow to ready" 0 "Allow to ready";
VAL_ 496 FDC_VCU_RegenTqLimitEn_Sta 1 "Enable" 0 "Disable";
VAL_ 496 FDC_VCU_ForceP_Cmd 1 "On" 0 "Off";
VAL_ 496 FDC_VCU_PwrReq_OTA_Sta 3 "Request power STANDBY" 2 "Request power OFF" 1 "Request power ON" 0 "No request";
VAL_ 496 FDC_VCU_OTAPwrReqOFFChk_Sta 3 "Reserved" 2 "Request power OFF and timeout" 1 "Request power OFF and no timeout" 0 "No request";
VAL_ 496 FDC_VCU_OTAPwrReqStdChk_Sta 3 "Reserved" 2 "Request power STANDBY and timeout" 1 "Request power STANDBY and no timeout" 0 "No request";
VAL_ 496 FDC_VCU_EAPS2Raw_Sta 255 "Invalid";
VAL_ 496 FDC_VCU_EAPS1Raw_Sta 255 "Invalid";
VAL_ 496 FDC_VCU_EAPS2Min_Sta 255 "Invalid";
VAL_ 496 FDC_VCU_EAPS1Min_Sta 255 "Invalid";
VAL_ 496 FDC_VCU_CANBrkSW2Sta_Sta 2 "Error" 1 "ON" 0 "OFF";
VAL_ 496 FDC_VCU_BrkPedalPosSta_Sta 2 "Error" 1 "ON" 0 "OFF";
VAL_ 496 FDC_VCU_LowIdleAccPedal_Sta 1 "Low idle" 0 "Pedal pressed";
VAL_ 496 FDC_SYS_PmicBootPath 10 "~0xFFFFFFFF OS Exception" 9 "PMICOffMode_SilentReboot" 8 "WatchdogReset_StdbyTimer_wakeup" 7 "PMICOffMode_A_Core_Sleep_failed" 6 "PMICOffMode_A_Core_request" 5 "PMICStandbyMode_Check_A_Core" 4 "PMICStandbyMode" 3 "BSWInitDone_Running" 2 "PMICInit_Complete" 1 "PMICInit_ToDo" 0 "SystemPwrOFF2ON";
VAL_ 496 FDC_VCU_FrRateLimitInc_Sta 65535 "Invalid";
VAL_ 496 FDC_VCU_RrRateLimitInc_Sta 65535 "Invalid";
VAL_ 496 FDC_VCU_FrRateLimitDec_Sta 0 "Invalid";
VAL_ 496 FDC_VCU_RrRateLimitDec_Sta 0 "Invalid";
VAL_ 496 FDC_VCU_FrFirstOrderInpTs 255 "Invalid";
VAL_ 496 FDC_VCU_RrFirstOrderInpTs 255 "Invalid";
VAL_ 496 FDC_VCU_BOSEnable_Sta 1 "ON" 0 "OFF";
VAL_ 534 BCM_Buzzer_Req 1 "Request" 0 "No Request";
VAL_ 534 TailgateRemote 3 "Invalid" 2 "Handle Request" 1 "Remote Request" 0 "No Request";
VAL_ 534 RoomLampL 1 "ON" 0 "OFF";
VAL_ 534 RoomLampH 1 "ON" 0 "OFF";
VAL_ 534 DimmerEN 1 "Enable" 0 "Disable";
VAL_ 534 BCM_DoorLock_Sta 1 "Lock" 0 "Unlock";
VAL_ 534 HornCtrl 1 "ON" 0 "OFF";
VAL_ 534 LockSetting 1 "Unlock Single Door" 0 "Unlock All Door";
VAL_ 534 LTurnLP 1 "On" 0 "Off";
VAL_ 534 RTurnLP 1 "On" 0 "Off";
VAL_ 534 AntitheftSta 3 "Alarm Status" 2 "Wait for Rearm Status" 1 "Arm Status" 0 "Disarm Status";
VAL_ 534 AntiTheftSeatFold 1 "Fold" 0 "No Request";
VAL_ 534 CrashDetd 1 "Crash detected" 0 "Crash not detected";
VAL_ 534 L_APM_WdwEnable 1 "Normal" 0 "Inhibit";
VAL_ 534 RDRL 1 "On" 0 "Off";
VAL_ 534 ReverseLamp 1 "On" 0 "Off";
VAL_ 534 BrakeLamp 1 "On" 0 "Off";
VAL_ 534 LBSD 1 "On" 0 "Off";
VAL_ 534 RBSD 1 "On" 0 "Off";
VAL_ 534 Fr_FogLamp 1 "On" 0 "Off";
VAL_ 534 Rr_FogLamp 1 "On" 0 "Off";
VAL_ 534 HazardSW 1 "On" 0 "Off";
VAL_ 534 Rr_Wiper 1 "On" 0 "Off";
VAL_ 534 WiperFixMode 1 "On" 0 "Off";
VAL_ 534 WasherCtrl 3 "Undefined" 2 "Rear Washer" 1 "Front Washer" 0 "No Command";
VAL_ 534 L_Beam 1 "On" 0 "Off";
VAL_ 534 H_Beam 1 "On" 0 "Off";
VAL_ 534 PosLamp 1 "On" 0 "Off";
VAL_ 534 LDRL 1 "On" 0 "Off";
VAL_ 534 MirrorDefog 1 "On" 0 "Off";
VAL_ 534 Rr_Defog 1 "On" 0 "Off";
VAL_ 534 TrunkRel 1 "Release" 0 "Off";
VAL_ 534 TailgateHDSW 1 "Press" 0 "Release";
VAL_ 534 MirrorCtrl 3 "Undefined" 2 "Unfold" 1 "Fold" 0 "No Command";
VAL_ 534 Fr_Wiper_H 1 "On" 0 "Off";
VAL_ 534 Fr_Wiper_L 1 "On" 0 "Off";
VAL_ 534 CTDCtrl 3 "Lock All Door" 2 "Unlock All Door" 1 "Unlock Driver Door" 0 "No Command";
VAL_ 534 Fr_ChargingDoorCtrl 3 "Undefined" 2 "Lock" 1 "Unlock" 0 "No Command";
VAL_ 534 Rr_ChargingDoorCtrl 3 "Undefined" 2 "Lock" 1 "Unlock" 0 "No Command";
VAL_ 534 CTDLockSW 1 "Press" 0 "Release";
VAL_ 534 CTDUnlockSW 1 "Press" 0 "Release";
VAL_ 534 DrDoorSW 1 "Open" 0 "Close";
VAL_ 534 PsDoorSW 1 "Open" 0 "Close";
VAL_ 534 RLDoorSW 1 "Open" 0 "Close";
VAL_ 534 RRDoorSW 1 "Open" 0 "Close";
VAL_ 534 AllDoorSW 1 "Any Door Open" 0 "Close";
VAL_ 534 DoorLockIND 1 "On" 0 "Off";
VAL_ 534 HoodSW 1 "Open" 0 "Close";
VAL_ 534 Tailgate_SW 1 "Open" 0 "Close";
VAL_ 884 Req_V2LSwOn 1 "Request for V2L plug switch on" 0 "Not request for V2L plug switch on";
VAL_ 884 Req_V2L_IVI_Popup 7 "Request IVI popup 'Stop By Plug in'" 6 "Request IVI popup 'V2L Fault'" 5 "Request IVI popup 'V2L Time up'" 4 "Request IVI popup 'SOC is too low'" 3 "Request IVI popup 'Stop by V2L SOC Set'" 2 "Request IVI popup 'V2L plug-in and V2L SW off'" 1 "Request IVI popup 'Check V2L Plug'" 0 "Not request";
VAL_ 884 FDC_V2L_OBCIntrV2L_Cmd 1 "Internal V2L discharge" 0 "Not request for V2L discharge";
VAL_ 884 FDC_V2L_OBCExtrV2L_Cmd 1 "External V2L discharge" 0 "Not request for V2L discharge";
VAL_ 884 Req_OBCV2LEna 2 "Internal V2L discharge" 1 "External V2L discharge" 0 "Not request for V2L discharge";
VAL_ 1080 OTA_Progress_Rate 102 "Invalid" 101 "Not in progress";
VAL_ 1080 OTA_DL_Available 1 "Ready for Download" 0 "Not Ready";
VAL_ 1080 OTA_Mode 1 "OTA mode" 0 "Normal mode";
VAL_ 1080 OTA_Network_Type 3 "Undefine" 2 "WiFi" 1 "LTE" 0 "Network Not Available";
VAL_ 1080 OTA_MDA_Status 15 "Undefine" 14 "Vehicle Reversed" 13 "OTA Task Finished" 12 "Vehicle Update Complete" 11 "Update Failed" 10 "Download Failed" 9 "Wait Arm" 8 "Download Suspend" 7 "Vehicle Roll-Back" 6 "Vehicle Updating" 5 "Wait Update" 4 "Campaign Downloading" 3 "Wait Download" 2 "Ask Campaign" 1 "Wait Network" 0 "Not Ready";
VAL_ 1080 OTA_Updating_ECU_8bit 255 "Invalid" 43 "CSW" 42 "Meter" 41 "WCM" 40 "LDM_RR" 39 "LDM_RL" 38 "LDM_FR" 37 "LDM_FL" 36 "BodyZone_Ps" 35 "BodyZone_Dr" 34 "DKC_UWB3" 33 "DKC_UWB2" 32 "DKC_UWB1" 31 "DKC_NFC" 30 "DKC_BLE" 29 "HMI" 28 "W_PTC" 27 "EBM" 26 "AIRPTC" 25 "E_Compressor" 24 "Shifter" 23 "TELLTALE" 22 "MRR" 21 "SRR_M" 20 "FCM" 19 "EPS" 18 "EOP_F" 17 "EOP_R" 16 "MCU_F" 15 "MCU_R" 14 "eBST" 13 "ESC" 12 "ABM" 11 "PSEAT" 10 "DSEAT" 9 "PTG" 8 "CCU" 7 "BMS" 6 "DKC" 5 "Zone_Dr" 4 "Zone_Fr" 3 "T-Box" 2 "IVI" 1 "FDC" 0 "No action";
VAL_ 1080 OTA_InVehicle_FW 2 "FW Need Update" 1 "FW Up to Date" 0 "Not Confirm";
VAL_ 1080 OTA_TBOXResetReq 1 "Request reset" 0 "No request";
VAL_ 1080 OTA_Lock_Req 1 "Lock Request" 0 "No action";
VAL_ 1080 OTA_Remained_Time 1081 "No action";
VAL_ 1080 OTA_Update_Available 1 "Ready for Update" 0 "Not Ready";
VAL_ 1080 OTA_Permit_Agreed 1 "Confirmed" 0 "Not Confirm";
VAL_ 1080 OTA_Debug_Code 63 "Backend unreachable" 56 "ECU upgrade stuck" 40 "Invalid parameter" 55 "ECU invalid data" 54 "ECU timeout" 53 "ECU unreachable" 51 "Method not support" 50 "Unknown error" 65 "Backend invalid data" 64 "Backend timeout" 0 "Normal state";
VAL_ 1080 OTA_Emergency_Sta 2 "Emergency - Lock Mode" 1 "Emergency - Limp Mode" 0 "Normal";
VAL_ 1183 IVI_Time_Month_toNidec 15 "Not Used" 14 "Not Used" 13 "Not Used" 0 "invalid";
VAL_ 1280 NM_FUSION_Rpt_Msg_Req 1 "Repeat Message State requested" 0 "Repeat Message State not requested";
VAL_ 1280 NM_FUSION_CSB 1 "Start of synchronized shutdown is requested by main coordinator" 0 "Start of synchronized shutdown is not requested by main coordinator";
VAL_ 1280 NM_FUSION_Active_WU 1 "Node has woken up the network (active Wakeup)" 0 "Node has not woken up the network (passive wakeup)";
VAL_ 1280 NM_FUSION_PNI 1 "NM PDU contains Partial Network request information" 0 "NM PDU contains no Partial Network request information";
VAL_ 1280 NM_FUSION_ERROR_State 8 "BUS OFF_L2" 4 "BUS OFF_L1" 2 "ERROR PASSIVE" 1 "ERROR ACTIVE" 0 "Inactive";
VAL_ 401 Fr_MCUSysSta 15 "Not used" 14 "Not used" 13 "Not used" 12 "Not used" 11 "Not used" 10 "Not used" 9 "Resolver Adjust." 8 "Diag Service" 7 "Discharge" 6 "AfterRun" 5 "Failure" 4 "Speed Control" 3 "Torque Control" 2 "Ready" 1 "Stand by" 0 "Initial Diag";
VAL_ 401 MCUWarn_F 7 "MCU Normal(NO Error)" 3 "ERR LVL3" 2 "ERR LVL2" 1 "ERR LVL1" 0 "ERR LVL0";
VAL_ 401 Fr_MCUReady 1 "Ready" 0 "Not Ready";
VAL_ 401 Fr_MCUIGN_sta 1 "MCU IGN On" 0 "MCU IGN Off";
VAL_ 401 Fr_MotorAvailTq 4095 "Invalid";
VAL_ 401 Fr_MCUErr 33 "Rolling counter_Err" 32 "Checksum_Err" 31 "BAT_High_Err" 30 "DrvrBrdOff" 29 "HWth3PHmax" 28 "AD2SInit_Err" 27 "B_OFFSET_Err" 26 "IGN_High_Err" 25 "IGBT_TEMP_sensing_Err" 24 "Motor_TEMP_sensing_Err" 23 "UVW_sensing_Err" 22 "UVW_unbalance" 21 "VPN_sensing_Err" 20 "IGN_Low_Err" 19 "BAT_Low_Err" 18 "Motor_TEMP_OVER" 17 "thRDX_ERROR" 16 "RDX_LOS" 15 "C_OFFSET_Err" 14 "A_OFFSET_Err" 13 "th3PHmax" 12 "H_sensor_Fault" 11 "VPN_250V" 10 "VPN_450V" 9 "HCU_miss" 8 "BMS_miss" 7 "UVW_open" 6 "IGBT_TEMP_OVER" 5 "P30BAT_ERR" 4 "DIR_ERR" 3 "Motor_speed_OVER" 2 "IGBT_FAULT" 1 "Motor_stuck" 0 "Nofault";
VAL_ 401 Fr_TMTemp 511 "Invalid";
VAL_ 401 Fr_MCUTemp 511 "Invalid";
VAL_ 401 Fr_MCUReady4Pre 1 "Ready for Precharge" 0 "Not Ready for Precharge";
VAL_ 401 Fr_ActvDmpDisabSta 1 "Disable" 0 "Enable";
VAL_ 401 Fr_EDUDrtSta 1 "Torque Derating" 0 "Normal operation";
VAL_ 401 Fr_MCUDischrgSta 1 "Discharge completed" 0 "Discharge not ready";
VAL_ 401 Fr_TMSpd 65535 "Invalid";
VAL_ 401 Fr_EDURealTMTq 65535 "Invalid";
VAL_ 401 Fr_MCUEnaSta 1 "Enable is ready" 0 "Disabled";
VAL_ 401 Fr_EDUOpratingSta 1 "Speed" 0 "Torque";
VAL_ 401 Fr_EDURotateDirction 2 "Backward" 1 "Forward" 0 "Stop";
VAL_ 401 MCU_B_F_IGBTDdeTemp_Sta 511 "Invalid";
VAL_ 401 MCU_B_F_RealPwrKw_Sta 65535 "Invalid";
VAL_ 404 Fr_Failcodehistory1 2 "Past failure" 1 "Latest failure" 0 "Nothing";
VAL_ 404 Fr_Failcodehistory2 2 "Past failure" 1 "Latest failure" 0 "Nothing";
VAL_ 404 Fr_TMTempWarn 3 "Invalid" 2 "Reserve" 1 "Warning" 0 "Normal";
VAL_ 404 Fr_MCUTempWarn 3 "Invalid" 2 "Reserve" 1 "Warning" 0 "Normal";
VAL_ 404 MCU_B_F_LLCTempWarn_Sta 3 "Invalid" 2 "Reserve" 1 "Warning" 0 "Normal";
VAL_ 404 MCU_B_F_FailLv_Sta 7 "Invalid" 6 "Reserved" 5 "Reserved" 4 "Reserved" 3 "Reserved" 2 "ASC" 1 "FW" 0 "Normal";
VAL_ 404 MCU_B_F_KL302TqCnt_Sta 255 "Invalid";
VAL_ 406 MCUWarn_F_Nidec 7 "MCU Normal(NO Error)" 3 "ERR LVL3" 2 "ERR LVL2" 1 "ERR LVL1" 0 "ERR LVL0";
VAL_ 406 Fr_MCUReady_Nidec 1 "Ready" 0 "Not Ready";
VAL_ 406 Fr_MCUSysSta_Nidec 15 "Not used" 14 "Not used" 13 "Not used" 12 "Not used" 11 "Not used" 10 "Not used" 9 "Resolver Adjust." 8 "Diag Service" 7 "Discharge" 6 "AfterRun" 5 "Failure" 4 "Speed Control" 3 "Torque Control" 2 "Ready" 1 "Stand by" 0 "Initial Diag";
VAL_ 406 Fr_MCUIGN_sta_Nidec 1 "MCU IGN On" 0 "MCU IGN Off";
VAL_ 406 Fr_MotorAvailTq_Nidec 4095 "Invalid";
VAL_ 406 Fr_MCUErr_Nidec 33 "Rolling counter_Err" 32 "Checksum_Err" 31 "BAT_High_Err" 30 "DrvrBrdOff" 29 "HWth3PHmax" 28 "AD2SInit_Err" 27 "B_OFFSET_Err" 26 "IGN_High_Err" 25 "IGBT_TEMP_sensing_Err" 24 "Motor_TEMP_sensing_Err" 23 "UVW_sensing_Err" 22 "UVW_unbalance" 21 "VPN_sensing_Err" 20 "IGN_Low_Err" 19 "BAT_Low_Err" 18 "Motor_TEMP_OVER" 17 "thRDX_ERROR" 16 "RDX_LOS" 15 "C_OFFSET_Err" 14 "A_OFFSET_Err" 13 "th3PHmax" 12 "H_sensor_Fault" 11 "VPN_250V" 10 "VPN_450V" 9 "HCU_miss" 8 "BMS_miss" 7 "UVW_open" 6 "IGBT_TEMP_OVER" 5 "P30BAT_ERR" 4 "DIR_ERR" 3 "Motor_speed_OVER" 2 "IGBT_FAULT" 1 "Motor_stuck" 0 "Nofault";
VAL_ 406 Fr_TMTemp_Nidec 511 "Invalid";
VAL_ 406 Fr_MCUTemp_Nidec 511 "Invalid";
VAL_ 406 Fr_MCUReady4Pre_Nidec 1 "Ready for Precharge" 0 "Not Ready for Precharge";
VAL_ 406 Fr_ActvDmpDisabSta_Nidec 1 "Disable" 0 "Enable";
VAL_ 406 Fr_EDUDrtSta_Nidec 1 "Torque Derating" 0 "Normal operation";
VAL_ 406 Fr_MCUDischrgSta_Nidec 1 "Discharge completed" 0 "Discharge not ready";
VAL_ 406 Fr_TMSpd_Nidec 65535 "Invalid";
VAL_ 406 Fr_EDURealTMTq_Nidec 4095 "Invalid";
VAL_ 406 Fr_MCUEnaSta_Nidec 1 "Enable is ready" 0 "Disabled";
VAL_ 406 Fr_EDUOpratingSta_Nidec 1 "Speed" 0 "Torque";
VAL_ 406 Fr_EDURotateDirction_Nidec 2 "Backward" 1 "Forward" 0 "Stop";
VAL_ 408 Fr_Failcodehistory1_Nidec 2 "Past failure" 1 "Latest failure" 0 "Nothing";
VAL_ 408 Fr_Failcodehistory2_Nidec 2 "Past failure" 1 "Latest failure" 0 "Nothing";
VAL_ 408 Fr_TMTempWarn_Nidec 3 "Invalid" 2 "Reserve" 1 "Warning" 0 "Normal";
VAL_ 408 Fr_MCUTempWarn_Nidec 3 "Invalid" 2 "Reserve" 1 "Warning" 0 "Normal";
VAL_ 1288 NM_MCU_N_F_Rpt_Msg_Req 1 "Repeat Message State requested" 0 "Repeat Message State not requested";
VAL_ 1288 NM_MCU_N_F_CSB 1 "Start of synchronized shutdown is requested by main coordinator" 0 "Start of synchronized shutdown is not requested by main coordinator";
VAL_ 1288 NM_MCU_N_F_Active_WU 1 "Node has woken up the network (active Wakeup)" 0 "Node has not woken up the network (passive wakeup)";
VAL_ 1288 NM_MCU_N_F_PNI 1 "NM PDU contains Partial Network request information" 0 "NM PDU contains no Partial Network request information";
VAL_ 1288 NM_MCU_N_F_ERROR_State 8 "BUS OFF_L2" 4 "BUS OFF_L1" 2 "ERROR PASSIVE" 1 "ERROR ACTIVE" 0 "Inactive";
VAL_ 400 Rr_MCUSysSta 15 "Not used" 14 "Not used" 13 "Not used" 12 "Not used" 11 "Not used" 10 "Not used" 9 "Resolver Adjust." 8 "Diag Service" 7 "Discharge" 6 "AfterRun" 5 "Failure" 4 "Speed Control" 3 "Torque Control" 2 "Ready" 1 "Stand by" 0 "Initial Diag";
VAL_ 400 MCUWarn_R 7 "MCU Normal(NO Error)" 3 "ERR LVL3" 2 "ERR LVL2" 1 "ERR LVL1" 0 "ERR LVL0";
VAL_ 400 Rr_MCUReady 1 "Ready" 0 "Not Ready";
VAL_ 400 Rr_MCUIGN_sta 1 "MCU IGN On" 0 "MCU IGN Off";
VAL_ 400 Rr_MotorAvailTq 4095 "Invalid";
VAL_ 400 Rr_MCUErr 33 "Rolling counter_Err" 32 "Checksum_Err" 31 "BAT_High_Err" 30 "DrvrBrdOff" 29 "HWth3PHmax" 28 "AD2SInit_Err" 27 "B_OFFSET_Err" 26 "IGN_High_Err" 25 "IGBT_TEMP_sensing_Err" 24 "Motor_TEMP_sensing_Err" 23 "UVW_sensing_Err" 22 "UVW_unbalance" 21 "VPN_sensing_Err" 20 "IGN_Low_Err" 19 "BAT_Low_Err" 18 "Motor_TEMP_OVER" 17 "thRDX_ERROR" 16 "RDX_LOS" 15 "C_OFFSET_Err" 14 "A_OFFSET_Err" 13 "th3PHmax" 12 "H_sensor_Fault" 11 "VPN_250V" 10 "VPN_450V" 9 "HCU_miss" 8 "BMS_miss" 7 "UVW_open" 6 "IGBT_TEMP_OVER" 5 "P30BAT_ERR" 4 "DIR_ERR" 3 "Motor_speed_OVER" 2 "IGBT_FAULT" 1 "Motor_stuck" 0 "Nofault";
VAL_ 400 Rr_TMTemp 511 "Invalid";
VAL_ 400 Rr_MCUTemp 511 "Invalid";
VAL_ 400 Rr_MCUReady4Pre 1 "Ready for Precharge" 0 "Not Ready for Precharge";
VAL_ 400 Rr_ActvDmpDisabSta 1 "Disable" 0 "Enable";
VAL_ 400 Rr_EDUDrtSta 1 "Torque Derating" 0 "Normal operation";
VAL_ 400 Rr_MCUDischrgSta 1 "Discharge completed" 0 "Discharge not ready";
VAL_ 400 Rr_TMSpd 65535 "Invalid";
VAL_ 400 Rr_EDURealTMTq 65535 "Invalid";
VAL_ 400 Rr_MCUEnaSta 1 "Enable is ready" 0 "Disabled";
VAL_ 400 Rr_EDUOpratingSta 1 "Speed" 0 "Torque";
VAL_ 400 Rr_EDURotateDirction 2 "Backward" 1 "Forward" 0 "Stop";
VAL_ 400 MCU_B_R_RealPwrKw_Sta 65535 "Invalid";
VAL_ 400 MCU_B_R_IGBTDdeTemp_Sta 511 "Invalid";
VAL_ 402 MCUWarn_R_Nidec 7 "MCU Normal(NO Error)" 3 "ERR LVL3" 2 "ERR LVL2" 1 "ERR LVL1" 0 "ERR LVL0";
VAL_ 402 Rr_MCUSysSta_Nidec 15 "Not used" 14 "Not used" 13 "Not used" 12 "Not used" 11 "Not used" 10 "Not used" 9 "Resolver Adjust." 8 "Diag Service" 7 "Discharge" 6 "AfterRun" 5 "Failure" 4 "Speed Control" 3 "Torque Control" 2 "Ready" 1 "Stand by" 0 "Initial Diag";
VAL_ 402 Rr_MCUIGN_sta_Nidec 1 "MCU IGN On" 0 "MCU IGN Off";
VAL_ 402 Rr_MotorAvailTq_Nidec 4095 "Invalid";
VAL_ 402 Rr_MCUErr_Nidec 33 "Rolling counter_Err" 32 "Checksum_Err" 31 "BAT_High_Err" 30 "DrvrBrdOff" 29 "HWth3PHmax" 28 "AD2SInit_Err" 27 "B_OFFSET_Err" 26 "IGN_High_Err" 25 "IGBT_TEMP_sensing_Err" 24 "Motor_TEMP_sensing_Err" 23 "UVW_sensing_Err" 22 "UVW_unbalance" 21 "VPN_sensing_Err" 20 "IGN_Low_Err" 19 "BAT_Low_Err" 18 "Motor_TEMP_OVER" 17 "thRDX_ERROR" 16 "RDX_LOS" 15 "C_OFFSET_Err" 14 "A_OFFSET_Err" 13 "th3PHmax" 12 "H_sensor_Fault" 11 "VPN_250V" 10 "VPN_450V" 9 "HCU_miss" 8 "BMS_miss" 7 "UVW_open" 6 "IGBT_TEMP_OVER" 5 "P30BAT_ERR" 4 "DIR_ERR" 3 "Motor_speed_OVER" 2 "IGBT_FAULT" 1 "Motor_stuck" 0 "Nofault";
VAL_ 402 Rr_TMTemp_Nidec 511 "Invalid";
VAL_ 402 Rr_MCUTemp_Nidec 511 "Invalid";
VAL_ 402 Rr_MCUReady4Pre_Nidec 1 "Ready for Precharge" 0 "Not Ready for Precharge";
VAL_ 402 Rr_ActvDmpDisabSta_Nidec 1 "Disable" 0 "Enable";
VAL_ 402 Rr_EDUDrtSta_Nidec 1 "Torque Derating" 0 "Normal operation";
VAL_ 402 Rr_MCUDischrgSta_Nidec 1 "Discharge completed" 0 "Discharge not ready";
VAL_ 402 Rr_MCUReady_Nidec 1 "Ready" 0 "Not Ready";
VAL_ 402 Rr_TMSpd_Nidec 65535 "Invalid";
VAL_ 402 Rr_EDURealTMTq_Nidec 4095 "Invalid";
VAL_ 402 Rr_MCUEnaSta_Nidec 1 "Enable is ready" 0 "Disabled";
VAL_ 402 Rr_EDUOpratingSta_Nidec 1 "Speed" 0 "Torque";
VAL_ 402 Rr_EDURotateDirction_Nidec 2 "Backward" 1 "Forward" 0 "Stop";
VAL_ 403 Rr_Failcodehistory1 2 "Past failure" 1 "Latest failure" 0 "Nothing";
VAL_ 403 Rr_Failcodehistory2 2 "Past failure" 1 "Latest failure" 0 "Nothing";
VAL_ 403 Rr_TMTempWarn 3 "Invalid" 2 "Reserve" 1 "Warning" 0 "Normal";
VAL_ 403 Rr_MCUTempWarn 3 "Invalid" 2 "Reserve" 1 "Warning" 0 "Normal";
VAL_ 403 MCU_B_R_LLCTempWarn_Sta 3 "Invalid" 2 "Reserve" 1 "Warning" 0 "Normal";
VAL_ 403 MCU_B_R_FailLv_Sta 7 "Invalid" 6 "Reserved" 5 "Reserved" 4 "Reserved" 3 "Reserved" 2 "ASC" 1 "FW" 0 "Normal";
VAL_ 403 MCU_B_R_KL302TqCnt_Sta 255 "Invalid";
VAL_ 412 Rr_Failcodehistory1_Nidec 2 "Past failure" 1 "Latest failure" 0 "Nothing";
VAL_ 412 Rr_Failcodehistory2_Nidec 2 "Past failure" 1 "Latest failure" 0 "Nothing";
VAL_ 412 Rr_TMTempWarn_Nidec 3 "Invalid" 2 "Reserve" 1 "Warning" 0 "Normal";
VAL_ 412 Rr_MCUTempWarn_Nidec 3 "Invalid" 2 "Reserve" 1 "Warning" 0 "Normal";
VAL_ 1283 NM_MCU_N_R_Rpt_Msg_Req 1 "Repeat Message State requested" 0 "Repeat Message State not requested";
VAL_ 1283 NM_MCU_N_R_CSB 1 "Start of synchronized shutdown is requested by main coordinator" 0 "Start of synchronized shutdown is not requested by main coordinator";
VAL_ 1283 NM_MCU_N_R_Active_WU 1 "Node has woken up the network (active Wakeup)" 0 "Node has not woken up the network (passive wakeup)";
VAL_ 1283 NM_MCU_N_R_PNI 1 "NM PDU contains Partial Network request information" 0 "NM PDU contains no Partial Network request information";
VAL_ 1283 NM_MCU_N_R_ERROR_State 8 "BUS OFF_L2" 4 "BUS OFF_L1" 2 "ERROR PASSIVE" 1 "ERROR ACTIVE" 0 "Inactive";
VAL_ 385 Shifter_Fail_sta 3 "shifter failure" 2 "Hall failure" 1 "P button failure" 0 "normal";
VAL_ 385 Shifter_Handle_Cmd 255 "invalid" 7 "Reverse" 5 "Drive" 4 "Neutral" 2 "Park" 0 "Default";
VAL_ 1336 NM_Shifter_Rpt_Msg_Req 1 "Repeat Message State requested" 0 "Repeat Message State not requested";
VAL_ 1336 NM_Shifter_CSB 1 "Start of synchronized shutdown is requested by main coordinator" 0 "Start of synchronized shutdown is not requested by main coordinator";
VAL_ 1336 NM_Shifter_Active_WU 1 "Node has woken up the network (active Wakeup)" 0 "Node has not woken up the network (passive wakeup)";
VAL_ 1336 NM_Shifter_PNI 1 "NM PDU contains Partial Network request information" 0 "NM PDU contains no Partial Network request information";
VAL_ 1336 NM_Shifter_ERROR_State 8 "BUS OFF_L2" 4 "BUS OFF_L1" 2 "ERROR PASSIVE" 1 "ERROR ACTIVE" 0 "Inactive";
VAL_ 1289 NM_MCU_B_R_ERROR_State 8 "BUS OFF_L2" 4 "BUS OFF_L1" 2 "ERROR PASSIVE" 1 "ERROR ACTIVE" 0 "Inactive";
VAL_ 1289 NM_MCU_B_R_Active_WU 1 "Node has woken up the network (active Wakeup)" 0 "Node has not woken up the network (passive wakeup)";
VAL_ 1289 NM_MCU_B_R_CSB 1 "Start of synchronized shutdown is requested by main coordinator" 0 "Start of synchronized shutdown is not requested by main coordinator";
VAL_ 1289 NM_MCU_B_R_PNI 1 "NM PDU contains Partial Network request information" 0 "NM PDU contains no Partial Network request information";
VAL_ 1289 NM_MCU_B_R_Rpt_Msg_Req 1 "Repeat Message State requested" 0 "Repeat Message State not requested";
VAL_ 1290 NM_MCU_B_F_ERROR_State 8 "BUS OFF_L2" 4 "BUS OFF_L1" 2 "ERROR PASSIVE" 1 "ERROR ACTIVE" 0 "Inactive";
VAL_ 1290 NM_MCU_B_F_Active_WU 1 "Node has woken up the network (active Wakeup)" 0 "Node has not woken up the network (passive wakeup)";
VAL_ 1290 NM_MCU_B_F_CSB 1 "Start of synchronized shutdown is requested by main coordinator" 0 "Start of synchronized shutdown is not requested by main coordinator";
VAL_ 1290 NM_MCU_B_F_PNI 1 "NM PDU contains Partial Network request information" 0 "NM PDU contains no Partial Network request information";
VAL_ 1290 NM_MCU_B_F_Rpt_Msg_Req 1 "Repeat Message State requested" 0 "Repeat Message State not requested";
VAL_ 368 CSW2_TurnSw_Sta 5 "Invalid" 4 "Right" 3 "Slight Right" 2 "Left" 1 "Slight Left" 0 "Off";
VAL_ 368 CSW2_FWipSw_Sta 7 "Invaild" 4 "AutoPlus" 3 "High" 2 "Low" 1 "Auto" 0 "Off";
VAL_ 368 CSW2_RWipWasSw_Sta 3 "Invalid" 2 "Mist" 1 "On" 0 "Off";
VAL_ 368 CSW2_FWasSw_Sta 3 "Invalid" 2 "Mist" 1 "On" 0 "Off";
VAL_ 368 CSW2_PassSW_Sta 1 "Press" 0 "Release";
VAL_ 368 CSW2_DimSw_Sta 1 "Press" 0 "Release";
VAL_ 409 MCU_FVT_R_TMSpd_Sta 65535 "Invalid";
VAL_ 409 MCU_FVT_R_EDUTqReq_Fbk 65535 "Invalid";
VAL_ 409 MCU_FVT_R_Failcode3_Sta 255 "Invalid";
VAL_ 409 MCU_FVT_R_MCUErr_Sta 33 "Rolling counter_Err" 32 "Checksum_Err" 31 "BAT_High_Err" 30 "DrvrBrdOff" 29 "HWth3PHmax" 28 "AD2SInit_Err" 27 "B_OFFSET_Err" 26 "IGN_High_Err" 25 "IGBT_TEMP_sensing_Err" 24 "Motor_TEMP_sensing_Err" 23 "UVW_sensing_Err" 22 "UVW_unbalance" 21 "VPN_sensing_Err" 20 "IGN_Low_Err" 19 "BAT_Low_Err" 18 "Motor_TEMP_OVER" 17 "thRDX_ERROR" 16 "RDX_LOS" 15 "C_OFFSET_Err" 14 "A_OFFSET_Err" 13 "th3PHmax" 12 "H_sensor_Fault" 11 "VPN_530V" 10 "VPN_830V" 9 "HCU_miss" 8 "BMS_miss" 7 "UVW_open" 6 "IGBT_TEMP_OVER" 5 "P30BAT_ERR" 4 "DIR_ERR" 3 "Motor_speed_OVER" 2 "IGBT_FAULT" 1 "Motor_stuck" 0 "Nofault";
VAL_ 409 MCU_FVT_R_OilTemp_Sta 511 "Invalid";
VAL_ 409 MCU_FVT_R_MCUBAT_Sta 511 "Invalid";
VAL_ 409 MCU_FVT_R_MCUSys_Sta 15 "Invalid" 14 "Reserved" 13 "Reserved" 12 "Boost charge mode" 11 "Heating mode" 10 "Emergency Power Down" 9 "Resolver Adjust." 8 "Diag Service" 7 "Discharge" 6 "AfterRun" 5 "Failure" 4 "Speed Control" 3 "Torque Control" 2 "Ready" 1 "Stand by" 0 "Initial Diag";
VAL_ 409 MCU_FVT_R_HeatingOP_Sta 1 "Heating" 0 "No Heating";
VAL_ 409 MCU_FVT_R_BoostOP_Sta 1 "Boost" 0 "No Boost";
VAL_ 410 MCU_FVT_F_TMSpd_Sta 65535 "Invalid";
VAL_ 410 MCU_FVT_F_EDUTqReq_Fbk 65535 "Invalid";
VAL_ 410 MCU_FVT_F_Failcode3_Sta 255 "Invalid";
VAL_ 410 MCU_FVT_F_MCUErr_Sta 33 "Rolling counter_Err" 32 "Checksum_Err" 31 "BAT_High_Err" 30 "DrvrBrdOff" 29 "HWth3PHmax" 28 "AD2SInit_Err" 27 "B_OFFSET_Err" 26 "IGN_High_Err" 25 "IGBT_TEMP_sensing_Err" 24 "Motor_TEMP_sensing_Err" 23 "UVW_sensing_Err" 22 "UVW_unbalance" 21 "VPN_sensing_Err" 20 "IGN_Low_Err" 19 "BAT_Low_Err" 18 "Motor_TEMP_OVER" 17 "thRDX_ERROR" 16 "RDX_LOS" 15 "C_OFFSET_Err" 14 "A_OFFSET_Err" 13 "th3PHmax" 12 "H_sensor_Fault" 11 "VPN_530V" 10 "VPN_830V" 9 "HCU_miss" 8 "BMS_miss" 7 "UVW_open" 6 "IGBT_TEMP_OVER" 5 "P30BAT_ERR" 4 "DIR_ERR" 3 "Motor_speed_OVER" 2 "IGBT_FAULT" 1 "Motor_stuck" 0 "Nofault";
VAL_ 410 MCU_FVT_F_OilTemp_Sta 511 "Invalid";
VAL_ 410 MCU_FVT_F_MCUBAT_Sta 511 "Invalid";
VAL_ 410 MCU_FVT_F_MCUSys_Sta 15 "Invalid" 14 "Reserved" 13 "Reserved" 12 "Boost charge mode" 11 "Heating mode" 10 "Emergency Power Down" 9 "Resolver Adjust." 8 "Diag Service" 7 "Discharge" 6 "AfterRun" 5 "Failure" 4 "Speed Control" 3 "Torque Control" 2 "Ready" 1 "Stand by" 0 "Initial Diag";
VAL_ 410 MCU_FVT_F_HeatingOP_Sta 1 "Heating" 0 "No Heating";
VAL_ 410 MCU_FVT_F_BoostOP_Sta 1 "Boost" 0 "No Boost";
